VERSION ""

NS_ :

BS_:

BU_: WCM VPM VLM VKM UVM TIM TEST_TOOL_2 TEST_TOOL_1 TCP TCM TCCM3 TCCM STC SRR_SRR SRR_SLR SRR_RR SRR_RF SRR_LR_CR SRR_LF SIB SDM SCL SBZA_R SBZA_L SBM SADS RadioLow RSC RDCM PTM PDR PA NVM MTCM_R MTCM_L MSM_RR MSM_P MSM_LR MSM_D MSB2 MSB1 MRCM_R MRCM_L MFC LRR_HC LRR LIB1 IPC ICS_Info ICCM HVAC_FP_R HVAC_FP_F HUD_CAN HDLM FCM_LC FCM EPS EOCM_HCP2 EOCM_HCP1 EOCM ELM ECP_X1 ECP_MC ECP_E ECM EBCM DMS DEFC DCM CSM CMMb CMMa CGM BSM_MH BSM BCM ARS ARB APA AOS AMP ALC AHS AHL_AFL AGC

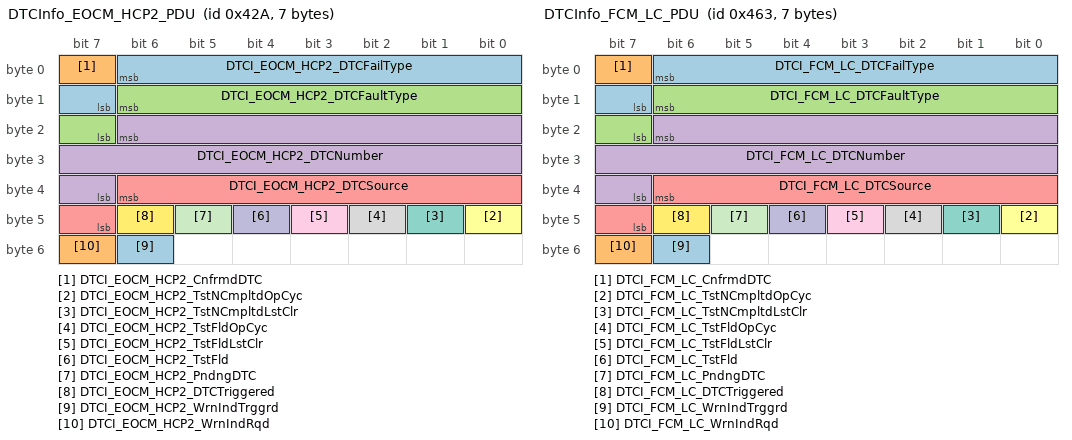
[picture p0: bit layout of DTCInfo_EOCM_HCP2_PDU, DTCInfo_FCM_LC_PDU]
BO_ 1066 DTCInfo_EOCM_HCP2_PDU: 7 EOCM_HCP2
 SG_ DTCI_EOCM_HCP2_DTCFailType : 6|8@0+ (1,0) [0|255] "" CGM
 SG_ DTCI_EOCM_HCP2_CnfrmdDTC : 7|1@0+ (1,0) [0|1] "" CGM
 SG_ DTCI_EOCM_HCP2_DTCFaultType : 14|8@0+ (1,0) [0|3] "" CGM
 SG_ DTCI_EOCM_HCP2_DTCNumber : 22|16@0+ (1,0) [0|65535] "" CGM
 SG_ DTCI_EOCM_HCP2_DTCSource : 38|8@0+ (1,0) [0|255] "" CGM
 SG_ DTCI_EOCM_HCP2_TstNCmpltdOpCyc : 40|1@0+ (1,0) [0|1] "" CGM
 SG_ DTCI_EOCM_HCP2_TstNCmpltdLstClr : 41|1@0+ (1,0) [0|1] "" CGM
 SG_ DTCI_EOCM_HCP2_TstFldOpCyc : 42|1@0+ (1,0) [0|1] "" CGM
 SG_ DTCI_EOCM_HCP2_TstFldLstClr : 43|1@0+ (1,0) [0|1] "" CGM
 SG_ DTCI_EOCM_HCP2_TstFld : 44|1@0+ (1,0) [0|1] "" CGM
 SG_ DTCI_EOCM_HCP2_PndngDTC : 45|1@0+ (1,0) [0|1] "" CGM
 SG_ DTCI_EOCM_HCP2_DTCTriggered : 46|1@0+ (1,0) [0|1] "" CGM
 SG_ DTCI_EOCM_HCP2_WrnIndTrggrd : 54|1@0+ (1,0) [0|1] "" CGM
 SG_ DTCI_EOCM_HCP2_WrnIndRqd : 55|1@0+ (1,0) [0|1] "" CGM

BO_ 1123 DTCInfo_FCM_LC_PDU: 7 FCM_LC
 SG_ DTCI_FCM_LC_DTCFailType : 6|8@0+ (1,0) [0|255] "" CGM
 SG_ DTCI_FCM_LC_CnfrmdDTC : 7|1@0+ (1,0) [0|1] "" CGM
 SG_ DTCI_FCM_LC_DTCFaultType : 14|8@0+ (1,0) [0|3] "" CGM
 SG_ DTCI_FCM_LC_DTCNumber : 22|16@0+ (1,0) [0|65535] "" CGM
 SG_ DTCI_FCM_LC_DTCSource : 38|8@0+ (1,0) [0|255] "" CGM
 SG_ DTCI_FCM_LC_TstNCmpltdOpCyc : 40|1@0+ (1,0) [0|1] "" CGM
 SG_ DTCI_FCM_LC_TstNCmpltdLstClr : 41|1@0+ (1,0) [0|1] "" CGM
 SG_ DTCI_FCM_LC_TstFldOpCyc : 42|1@0+ (1,0) [0|1] "" CGM
 SG_ DTCI_FCM_LC_TstFldLstClr : 43|1@0+ (1,0) [0|1] "" CGM
 SG_ DTCI_FCM_LC_TstFld : 44|1@0+ (1,0) [0|1] "" CGM
 SG_ DTCI_FCM_LC_PndngDTC : 45|1@0+ (1,0) [0|1] "" CGM
 SG_ DTCI_FCM_LC_DTCTriggered : 46|1@0+ (1,0) [0|1] "" CGM
 SG_ DTCI_FCM_LC_WrnIndTrggrd : 54|1@0+ (1,0) [0|1] "" CGM
 SG_ DTCI_FCM_LC_WrnIndRqd : 55|1@0+ (1,0) [0|1] "" CGM

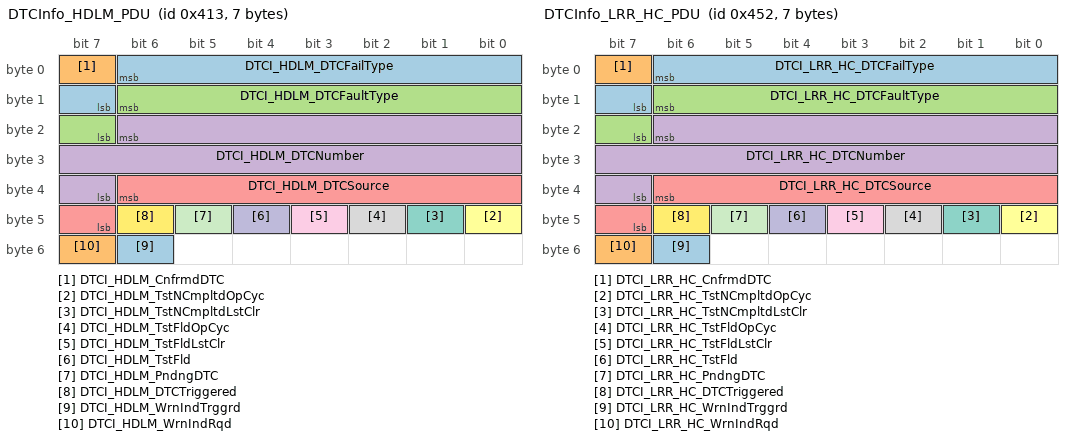
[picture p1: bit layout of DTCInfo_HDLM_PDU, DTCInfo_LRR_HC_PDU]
BO_ 1043 DTCInfo_HDLM_PDU: 7 HDLM
 SG_ DTCI_HDLM_DTCFailType : 6|8@0+ (1,0) [0|255] "" CGM
 SG_ DTCI_HDLM_CnfrmdDTC : 7|1@0+ (1,0) [0|1] "" CGM
 SG_ DTCI_HDLM_DTCFaultType : 14|8@0+ (1,0) [0|3] "" CGM
 SG_ DTCI_HDLM_DTCNumber : 22|16@0+ (1,0) [0|65535] "" CGM
 SG_ DTCI_HDLM_DTCSource : 38|8@0+ (1,0) [0|255] "" CGM
 SG_ DTCI_HDLM_TstNCmpltdOpCyc : 40|1@0+ (1,0) [0|1] "" CGM
 SG_ DTCI_HDLM_TstNCmpltdLstClr : 41|1@0+ (1,0) [0|1] "" CGM
 SG_ DTCI_HDLM_TstFldOpCyc : 42|1@0+ (1,0) [0|1] "" CGM
 SG_ DTCI_HDLM_TstFldLstClr : 43|1@0+ (1,0) [0|1] "" CGM
 SG_ DTCI_HDLM_TstFld : 44|1@0+ (1,0) [0|1] "" CGM
 SG_ DTCI_HDLM_PndngDTC : 45|1@0+ (1,0) [0|1] "" CGM
 SG_ DTCI_HDLM_DTCTriggered : 46|1@0+ (1,0) [0|1] "" CGM
 SG_ DTCI_HDLM_WrnIndTrggrd : 54|1@0+ (1,0) [0|1] "" CGM
 SG_ DTCI_HDLM_WrnIndRqd : 55|1@0+ (1,0) [0|1] "" CGM

BO_ 1106 DTCInfo_LRR_HC_PDU: 7 LRR_HC
 SG_ DTCI_LRR_HC_DTCFailType : 6|8@0+ (1,0) [0|255] "" CGM
 SG_ DTCI_LRR_HC_CnfrmdDTC : 7|1@0+ (1,0) [0|1] "" CGM
 SG_ DTCI_LRR_HC_DTCFaultType : 14|8@0+ (1,0) [0|3] "" CGM
 SG_ DTCI_LRR_HC_DTCNumber : 22|16@0+ (1,0) [0|65535] "" CGM
 SG_ DTCI_LRR_HC_DTCSource : 38|8@0+ (1,0) [0|255] "" CGM
 SG_ DTCI_LRR_HC_TstNCmpltdOpCyc : 40|1@0+ (1,0) [0|1] "" CGM
 SG_ DTCI_LRR_HC_TstNCmpltdLstClr : 41|1@0+ (1,0) [0|1] "" CGM
 SG_ DTCI_LRR_HC_TstFldOpCyc : 42|1@0+ (1,0) [0|1] "" CGM
 SG_ DTCI_LRR_HC_TstFldLstClr : 43|1@0+ (1,0) [0|1] "" CGM
 SG_ DTCI_LRR_HC_TstFld : 44|1@0+ (1,0) [0|1] "" CGM
 SG_ DTCI_LRR_HC_PndngDTC : 45|1@0+ (1,0) [0|1] "" CGM
 SG_ DTCI_LRR_HC_DTCTriggered : 46|1@0+ (1,0) [0|1] "" CGM
 SG_ DTCI_LRR_HC_WrnIndTrggrd : 54|1@0+ (1,0) [0|1] "" CGM
 SG_ DTCI_LRR_HC_WrnIndRqd : 55|1@0+ (1,0) [0|1] "" CGM

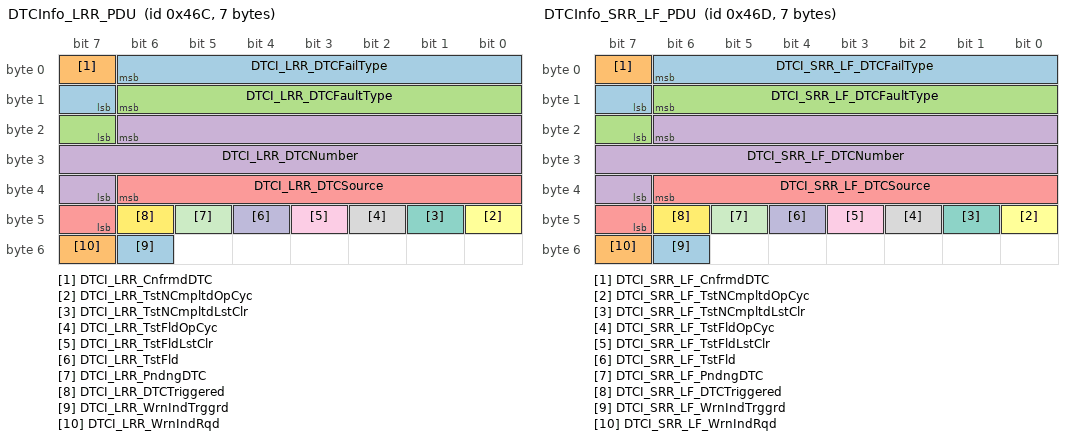
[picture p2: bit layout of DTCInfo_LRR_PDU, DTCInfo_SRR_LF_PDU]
BO_ 1132 DTCInfo_LRR_PDU: 7 LRR
 SG_ DTCI_LRR_DTCFailType : 6|8@0+ (1,0) [0|255] "" CGM
 SG_ DTCI_LRR_CnfrmdDTC : 7|1@0+ (1,0) [0|1] "" CGM
 SG_ DTCI_LRR_DTCFaultType : 14|8@0+ (1,0) [0|3] "" CGM
 SG_ DTCI_LRR_DTCNumber : 22|16@0+ (1,0) [0|65535] "" CGM
 SG_ DTCI_LRR_DTCSource : 38|8@0+ (1,0) [0|255] "" CGM
 SG_ DTCI_LRR_TstNCmpltdOpCyc : 40|1@0+ (1,0) [0|1] "" CGM
 SG_ DTCI_LRR_TstNCmpltdLstClr : 41|1@0+ (1,0) [0|1] "" CGM
 SG_ DTCI_LRR_TstFldOpCyc : 42|1@0+ (1,0) [0|1] "" CGM
 SG_ DTCI_LRR_TstFldLstClr : 43|1@0+ (1,0) [0|1] "" CGM
 SG_ DTCI_LRR_TstFld : 44|1@0+ (1,0) [0|1] "" CGM
 SG_ DTCI_LRR_PndngDTC : 45|1@0+ (1,0) [0|1] "" CGM
 SG_ DTCI_LRR_DTCTriggered : 46|1@0+ (1,0) [0|1] "" CGM
 SG_ DTCI_LRR_WrnIndTrggrd : 54|1@0+ (1,0) [0|1] "" CGM
 SG_ DTCI_LRR_WrnIndRqd : 55|1@0+ (1,0) [0|1] "" CGM

BO_ 1133 DTCInfo_SRR_LF_PDU: 7 SRR_LF
 SG_ DTCI_SRR_LF_DTCFailType : 6|8@0+ (1,0) [0|255] "" CGM
 SG_ DTCI_SRR_LF_CnfrmdDTC : 7|1@0+ (1,0) [0|1] "" CGM
 SG_ DTCI_SRR_LF_DTCFaultType : 14|8@0+ (1,0) [0|3] "" CGM
 SG_ DTCI_SRR_LF_DTCNumber : 22|16@0+ (1,0) [0|65535] "" CGM
 SG_ DTCI_SRR_LF_DTCSource : 38|8@0+ (1,0) [0|255] "" CGM
 SG_ DTCI_SRR_LF_TstNCmpltdOpCyc : 40|1@0+ (1,0) [0|1] "" CGM
 SG_ DTCI_SRR_LF_TstNCmpltdLstClr : 41|1@0+ (1,0) [0|1] "" CGM
 SG_ DTCI_SRR_LF_TstFldOpCyc : 42|1@0+ (1,0) [0|1] "" CGM
 SG_ DTCI_SRR_LF_TstFldLstClr : 43|1@0+ (1,0) [0|1] "" CGM
 SG_ DTCI_SRR_LF_TstFld : 44|1@0+ (1,0) [0|1] "" CGM
 SG_ DTCI_SRR_LF_PndngDTC : 45|1@0+ (1,0) [0|1] "" CGM
 SG_ DTCI_SRR_LF_DTCTriggered : 46|1@0+ (1,0) [0|1] "" CGM
 SG_ DTCI_SRR_LF_WrnIndTrggrd : 54|1@0+ (1,0) [0|1] "" CGM
 SG_ DTCI_SRR_LF_WrnIndRqd : 55|1@0+ (1,0) [0|1] "" CGM

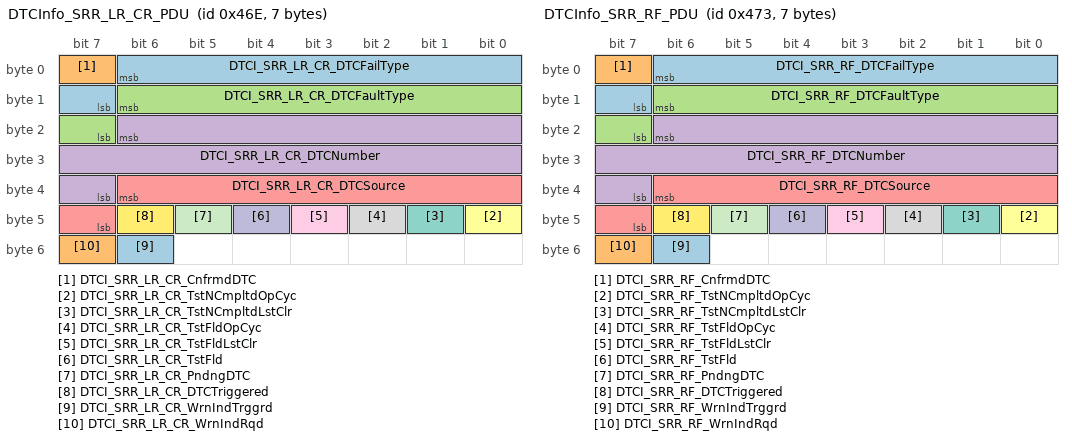
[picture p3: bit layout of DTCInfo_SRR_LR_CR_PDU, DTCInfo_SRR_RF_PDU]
BO_ 1134 DTCInfo_SRR_LR_CR_PDU: 7 SRR_LR_CR
 SG_ DTCI_SRR_LR_CR_DTCFailType : 6|8@0+ (1,0) [0|255] "" CGM
 SG_ DTCI_SRR_LR_CR_CnfrmdDTC : 7|1@0+ (1,0) [0|1] "" CGM
 SG_ DTCI_SRR_LR_CR_DTCFaultType : 14|8@0+ (1,0) [0|3] "" CGM
 SG_ DTCI_SRR_LR_CR_DTCNumber : 22|16@0+ (1,0) [0|65535] "" CGM
 SG_ DTCI_SRR_LR_CR_DTCSource : 38|8@0+ (1,0) [0|255] "" CGM
 SG_ DTCI_SRR_LR_CR_TstNCmpltdOpCyc : 40|1@0+ (1,0) [0|1] "" CGM
 SG_ DTCI_SRR_LR_CR_TstNCmpltdLstClr : 41|1@0+ (1,0) [0|1] "" CGM
 SG_ DTCI_SRR_LR_CR_TstFldOpCyc : 42|1@0+ (1,0) [0|1] "" CGM
 SG_ DTCI_SRR_LR_CR_TstFldLstClr : 43|1@0+ (1,0) [0|1] "" CGM
 SG_ DTCI_SRR_LR_CR_TstFld : 44|1@0+ (1,0) [0|1] "" CGM
 SG_ DTCI_SRR_LR_CR_PndngDTC : 45|1@0+ (1,0) [0|1] "" CGM
 SG_ DTCI_SRR_LR_CR_DTCTriggered : 46|1@0+ (1,0) [0|1] "" CGM
 SG_ DTCI_SRR_LR_CR_WrnIndTrggrd : 54|1@0+ (1,0) [0|1] "" CGM
 SG_ DTCI_SRR_LR_CR_WrnIndRqd : 55|1@0+ (1,0) [0|1] "" CGM

BO_ 1139 DTCInfo_SRR_RF_PDU: 7 SRR_RF
 SG_ DTCI_SRR_RF_DTCFailType : 6|8@0+ (1,0) [0|255] "" CGM
 SG_ DTCI_SRR_RF_CnfrmdDTC : 7|1@0+ (1,0) [0|1] "" CGM
 SG_ DTCI_SRR_RF_DTCFaultType : 14|8@0+ (1,0) [0|3] "" CGM
 SG_ DTCI_SRR_RF_DTCNumber : 22|16@0+ (1,0) [0|65535] "" CGM
 SG_ DTCI_SRR_RF_DTCSource : 38|8@0+ (1,0) [0|255] "" CGM
 SG_ DTCI_SRR_RF_TstNCmpltdOpCyc : 40|1@0+ (1,0) [0|1] "" CGM
 SG_ DTCI_SRR_RF_TstNCmpltdLstClr : 41|1@0+ (1,0) [0|1] "" CGM
 SG_ DTCI_SRR_RF_TstFldOpCyc : 42|1@0+ (1,0) [0|1] "" CGM
 SG_ DTCI_SRR_RF_TstFldLstClr : 43|1@0+ (1,0) [0|1] "" CGM
 SG_ DTCI_SRR_RF_TstFld : 44|1@0+ (1,0) [0|1] "" CGM
 SG_ DTCI_SRR_RF_PndngDTC : 45|1@0+ (1,0) [0|1] "" CGM
 SG_ DTCI_SRR_RF_DTCTriggered : 46|1@0+ (1,0) [0|1] "" CGM
 SG_ DTCI_SRR_RF_WrnIndTrggrd : 54|1@0+ (1,0) [0|1] "" CGM
 SG_ DTCI_SRR_RF_WrnIndRqd : 55|1@0+ (1,0) [0|1] "" CGM

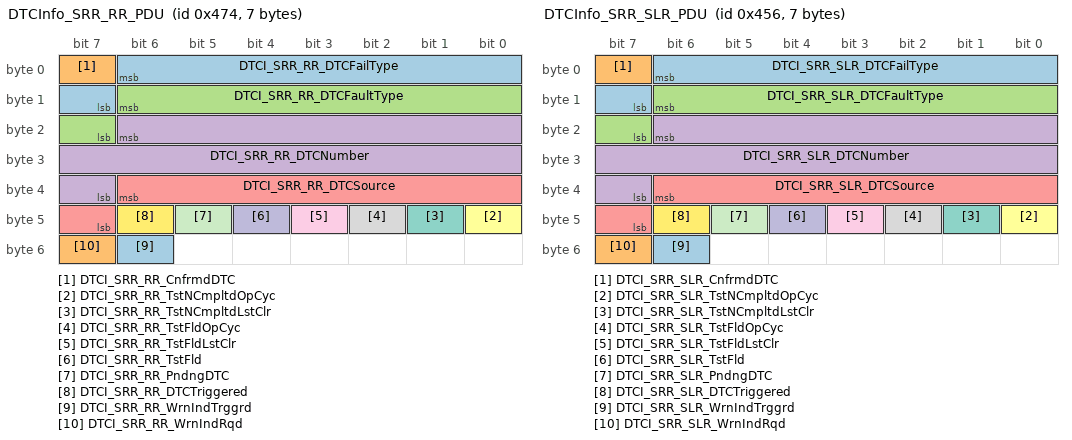
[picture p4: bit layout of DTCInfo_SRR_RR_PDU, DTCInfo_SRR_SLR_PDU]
BO_ 1140 DTCInfo_SRR_RR_PDU: 7 SRR_RR
 SG_ DTCI_SRR_RR_DTCFailType : 6|8@0+ (1,0) [0|255] "" CGM
 SG_ DTCI_SRR_RR_CnfrmdDTC : 7|1@0+ (1,0) [0|1] "" CGM
 SG_ DTCI_SRR_RR_DTCFaultType : 14|8@0+ (1,0) [0|3] "" CGM
 SG_ DTCI_SRR_RR_DTCNumber : 22|16@0+ (1,0) [0|65535] "" CGM
 SG_ DTCI_SRR_RR_DTCSource : 38|8@0+ (1,0) [0|255] "" CGM
 SG_ DTCI_SRR_RR_TstNCmpltdOpCyc : 40|1@0+ (1,0) [0|1] "" CGM
 SG_ DTCI_SRR_RR_TstNCmpltdLstClr : 41|1@0+ (1,0) [0|1] "" CGM
 SG_ DTCI_SRR_RR_TstFldOpCyc : 42|1@0+ (1,0) [0|1] "" CGM
 SG_ DTCI_SRR_RR_TstFldLstClr : 43|1@0+ (1,0) [0|1] "" CGM
 SG_ DTCI_SRR_RR_TstFld : 44|1@0+ (1,0) [0|1] "" CGM
 SG_ DTCI_SRR_RR_PndngDTC : 45|1@0+ (1,0) [0|1] "" CGM
 SG_ DTCI_SRR_RR_DTCTriggered : 46|1@0+ (1,0) [0|1] "" CGM
 SG_ DTCI_SRR_RR_WrnIndTrggrd : 54|1@0+ (1,0) [0|1] "" CGM
 SG_ DTCI_SRR_RR_WrnIndRqd : 55|1@0+ (1,0) [0|1] "" CGM

BO_ 1110 DTCInfo_SRR_SLR_PDU: 7 SRR_SLR
 SG_ DTCI_SRR_SLR_DTCFailType : 6|8@0+ (1,0) [0|255] "" CGM
 SG_ DTCI_SRR_SLR_CnfrmdDTC : 7|1@0+ (1,0) [0|1] "" CGM
 SG_ DTCI_SRR_SLR_DTCFaultType : 14|8@0+ (1,0) [0|3] "" CGM
 SG_ DTCI_SRR_SLR_DTCNumber : 22|16@0+ (1,0) [0|65535] "" CGM
 SG_ DTCI_SRR_SLR_DTCSource : 38|8@0+ (1,0) [0|255] "" CGM
 SG_ DTCI_SRR_SLR_TstNCmpltdOpCyc : 40|1@0+ (1,0) [0|1] "" CGM
 SG_ DTCI_SRR_SLR_TstNCmpltdLstClr : 41|1@0+ (1,0) [0|1] "" CGM
 SG_ DTCI_SRR_SLR_TstFldOpCyc : 42|1@0+ (1,0) [0|1] "" CGM
 SG_ DTCI_SRR_SLR_TstFldLstClr : 43|1@0+ (1,0) [0|1] "" CGM
 SG_ DTCI_SRR_SLR_TstFld : 44|1@0+ (1,0) [0|1] "" CGM
 SG_ DTCI_SRR_SLR_PndngDTC : 45|1@0+ (1,0) [0|1] "" CGM
 SG_ DTCI_SRR_SLR_DTCTriggered : 46|1@0+ (1,0) [0|1] "" CGM
 SG_ DTCI_SRR_SLR_WrnIndTrggrd : 54|1@0+ (1,0) [0|1] "" CGM
 SG_ DTCI_SRR_SLR_WrnIndRqd : 55|1@0+ (1,0) [0|1] "" CGM

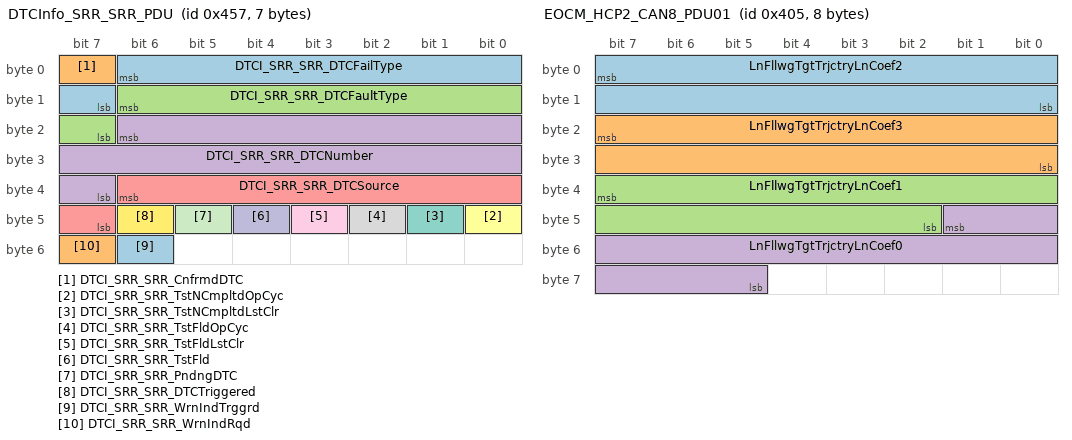
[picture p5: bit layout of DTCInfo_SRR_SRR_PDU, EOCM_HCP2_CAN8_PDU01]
BO_ 1111 DTCInfo_SRR_SRR_PDU: 7 SRR_SRR
 SG_ DTCI_SRR_SRR_DTCFailType : 6|8@0+ (1,0) [0|255] "" CGM
 SG_ DTCI_SRR_SRR_CnfrmdDTC : 7|1@0+ (1,0) [0|1] "" CGM
 SG_ DTCI_SRR_SRR_DTCFaultType : 14|8@0+ (1,0) [0|3] "" CGM
 SG_ DTCI_SRR_SRR_DTCNumber : 22|16@0+ (1,0) [0|65535] "" CGM
 SG_ DTCI_SRR_SRR_DTCSource : 38|8@0+ (1,0) [0|255] "" CGM
 SG_ DTCI_SRR_SRR_TstNCmpltdOpCyc : 40|1@0+ (1,0) [0|1] "" CGM
 SG_ DTCI_SRR_SRR_TstNCmpltdLstClr : 41|1@0+ (1,0) [0|1] "" CGM
 SG_ DTCI_SRR_SRR_TstFldOpCyc : 42|1@0+ (1,0) [0|1] "" CGM
 SG_ DTCI_SRR_SRR_TstFldLstClr : 43|1@0+ (1,0) [0|1] "" CGM
 SG_ DTCI_SRR_SRR_TstFld : 44|1@0+ (1,0) [0|1] "" CGM
 SG_ DTCI_SRR_SRR_PndngDTC : 45|1@0+ (1,0) [0|1] "" CGM
 SG_ DTCI_SRR_SRR_DTCTriggered : 46|1@0+ (1,0) [0|1] "" CGM
 SG_ DTCI_SRR_SRR_WrnIndTrggrd : 54|1@0+ (1,0) [0|1] "" CGM
 SG_ DTCI_SRR_SRR_WrnIndRqd : 55|1@0+ (1,0) [0|1] "" CGM

BO_ 1122 EOCM_CAN8_PDU01: 6 EOCM
 SG_ ASDREvntTrgrPrty : 5|4@0+ (1,0) [0|15] "" FCM_LC
 SG_ ACCAutoStSpStat : 7|2@0+ (1,0) [0|3] "" CGM,FCM_LC

BO_ 178 EOCM_CAN8_PDU02: 6 EOCM
 SG_ ACCBRP_ACCActvAuth : 7|1@0+ (1,0) [0|1] "" FCM_LC

BO_ 1108 EOCM_CAN8_PDU03: 6 EOCM
 SG_ LnDprtrWrnCtlSdThrtRtMirIndReq : 5|2@0+ (1,0) [0|3] "" SRR_SRR
 SG_ LnDprtrWrnCtlSdThrtLtMirIndReq : 7|2@0+ (1,0) [0|3] "" SRR_SLR

BO_ 1029 EOCM_HCP2_CAN8_PDU01: 8 EOCM_HCP2
 SG_ LnFllwgTgtTrjctryLnCoef2 : 7|16@0- (9.77e-07,0) [-0.0320143|0.0320134] "1/m" CGM
 SG_ LnFllwgTgtTrjctryLnCoef3 : 23|16@0- (3.73e-09,0) [-0.000122225|0.000122221] "1/m^2" CGM
 SG_ LnFllwgTgtTrjctryLnCoef1 : 39|14@0- (0.00125,0) [-10.24|10.2388] "m/m" CGM
 SG_ LnFllwgTgtTrjctryLnCoef0 : 41|13@0- (0.00309,0) [-12.6566|12.6535] "m" CGM

BO_ 1045 ElecPrkBrkSts_Prtctd_PDU: 6 CGM
 SG_ EPBSP_ElecPrkBrkApplStsAuth : 35|3@0+ (1,0) [0|4] "" SRR_SLR,SRR_SRR

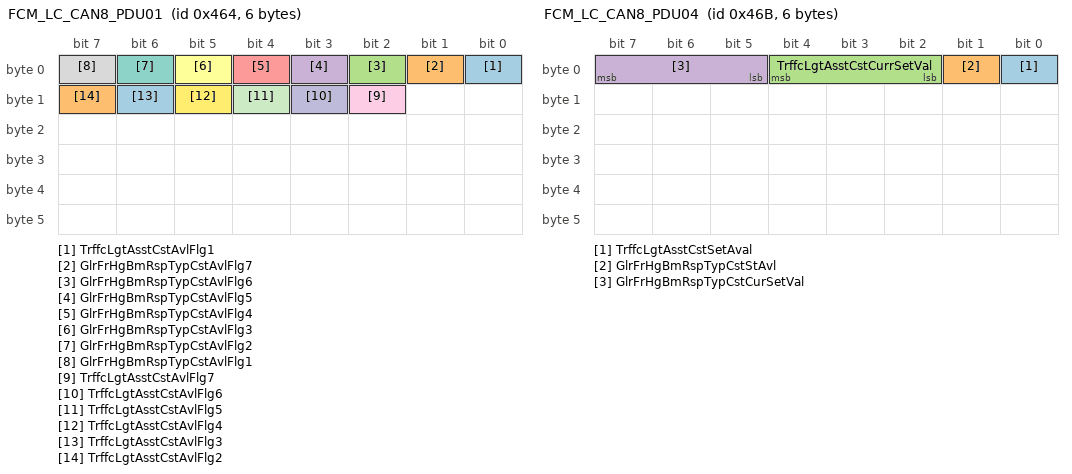
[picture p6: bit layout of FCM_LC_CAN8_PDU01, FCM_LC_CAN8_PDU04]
BO_ 1124 FCM_LC_CAN8_PDU01: 6 FCM_LC
 SG_ TrffcLgtAsstCstAvlFlg1 : 0|1@0+ (1,0) [0|1] "" CGM
 SG_ GlrFrHgBmRspTypCstAvlFlg7 : 1|1@0+ (1,0) [0|1] "" CGM
 SG_ GlrFrHgBmRspTypCstAvlFlg6 : 2|1@0+ (1,0) [0|1] "" CGM
 SG_ GlrFrHgBmRspTypCstAvlFlg5 : 3|1@0+ (1,0) [0|1] "" CGM
 SG_ GlrFrHgBmRspTypCstAvlFlg4 : 4|1@0+ (1,0) [0|1] "" CGM
 SG_ GlrFrHgBmRspTypCstAvlFlg3 : 5|1@0+ (1,0) [0|1] "" CGM
 SG_ GlrFrHgBmRspTypCstAvlFlg2 : 6|1@0+ (1,0) [0|1] "" CGM
 SG_ GlrFrHgBmRspTypCstAvlFlg1 : 7|1@0+ (1,0) [0|1] "" CGM
 SG_ TrffcLgtAsstCstAvlFlg7 : 10|1@0+ (1,0) [0|1] "" CGM
 SG_ TrffcLgtAsstCstAvlFlg6 : 11|1@0+ (1,0) [0|1] "" CGM
 SG_ TrffcLgtAsstCstAvlFlg5 : 12|1@0+ (1,0) [0|1] "" CGM
 SG_ TrffcLgtAsstCstAvlFlg4 : 13|1@0+ (1,0) [0|1] "" CGM
 SG_ TrffcLgtAsstCstAvlFlg3 : 14|1@0+ (1,0) [0|1] "" CGM
 SG_ TrffcLgtAsstCstAvlFlg2 : 15|1@0+ (1,0) [0|1] "" CGM

BO_ 1126 FCM_LC_CAN8_PDU02: 6 FCM_LC
 SG_ TrffcLgtAsstWrnChmEvntStat : 10|2@0+ (1,0) [0|3] "" CGM

BO_ 1129 FCM_LC_CAN8_PDU03: 6 FCM_LC
 SG_ AutoHgBmCtrlIO : 7|1@0+ (1,0) [0|1] "" CGM

BO_ 1131 FCM_LC_CAN8_PDU04: 6 FCM_LC
 SG_ TrffcLgtAsstCstSetAval : 0|1@0+ (1,0) [0|1] "" CGM
 SG_ GlrFrHgBmRspTypCstStAvl : 1|1@0+ (1,0) [0|1] "" CGM
 SG_ TrffcLgtAsstCstCurrSetVal : 4|3@0+ (1,0) [0|7] "" CGM
 SG_ GlrFrHgBmRspTypCstCurSetVal : 7|3@0+ (1,0) [0|7] "" CGM

BO_ 1070 FCODP_Brst1_PCSM_PDU: 8 FCM_LC
 SG_ FCODP_Brst1_PCSM : 0|64@1+ (1,0) [0|1.84467e+019] "" EOCM,EOCM_HCP1,EOCM_HCP2,HDLM

BO_ 17 FsdLoclzdRdTyp_CAN8_PDU01: 6 EOCM
 SG_ FsdLoclzdRdTyp : 1|2@0+ (1,0) [0|2] "" CGM

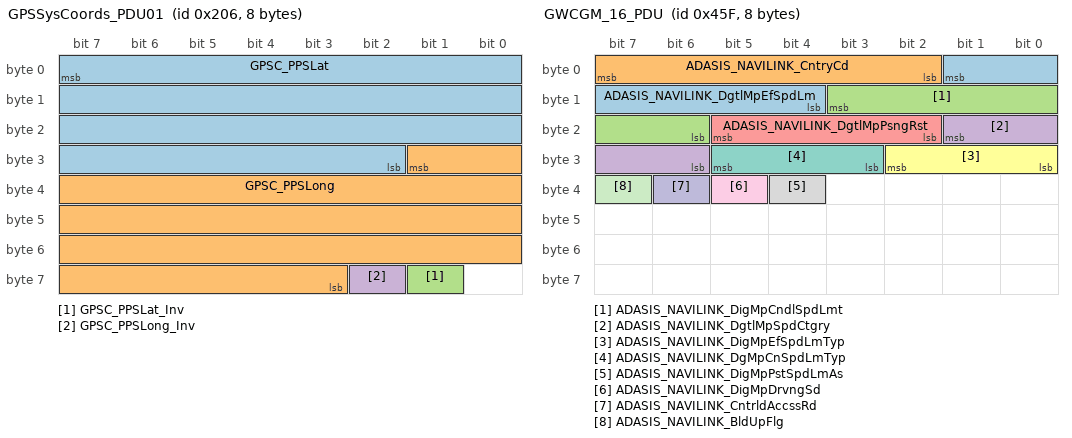
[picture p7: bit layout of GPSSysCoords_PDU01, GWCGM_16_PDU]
BO_ 518 GPSSysCoords_PDU01: 8 CGM
 SG_ GPSC_PPSLat : 7|30@0- (1,0) [-5.36871e+008|5.36871e+008] "ms arc" FCM_LC
 SG_ GPSC_PPSLong : 25|31@0- (1,0) [-1.07374e+009|1.07374e+009] "ms arc" FCM_LC
 SG_ GPSC_PPSLat_Inv : 57|1@0+ (1,0) [0|1] "" FCM_LC
 SG_ GPSC_PPSLong_Inv : 58|1@0+ (1,0) [0|1] "" FCM_LC

BO_ 1128 GWCGM_12_PDU: 8 FCM_LC
 SG_ TSMCurrSpdLim : 7|8@0+ (1,0) [0|255] "" Vector__XXX
 SG_ TSMEurDispSgn2Mn : 9|6@0+ (1,0) [0|54] "" Vector__XXX
 SG_ TSMEurDispSgn1Mn : 15|6@0+ (1,0) [0|54] "" Vector__XXX
 SG_ TSMUSAndCADispSgn1Mn : 19|6@0+ (1,0) [0|45] "" Vector__XXX
 SG_ TSMUSAndCADispSgn2Mn : 29|6@0+ (1,0) [0|45] "" Vector__XXX
 SG_ TSMEurDispSgn2AddOn : 35|4@0+ (1,0) [0|15] "" Vector__XXX
 SG_ TSMEurDispSgn1AddOn : 39|4@0+ (1,0) [0|15] "" Vector__XXX
 SG_ FrwdVsFlDtcnIndOn : 40|1@0+ (1,0) [0|1] "" Vector__XXX
 SG_ FrwdVsAdvWthrIndOn : 41|1@0+ (1,0) [0|1] "" Vector__XXX
 SG_ TSMUSAndCADispSgn2AddOn : 44|3@0+ (1,0) [0|5] "" Vector__XXX
 SG_ TSMUSAndCADispSgn1AddOn : 47|3@0+ (1,0) [0|5] "" Vector__XXX
 SG_ TrffcLgtAsstHUDWrnIndOn : 48|1@0+ (1,0) [0|1] "" Vector__XXX
 SG_ TrffcLgtAsstClstrWrnIndOn : 49|1@0+ (1,0) [0|1] "" Vector__XXX
 SG_ TSMSgnNtfnIndOn : 50|1@0+ (1,0) [0|1] "" Vector__XXX
 SG_ TSMPDAMnSgnFlshgReq : 51|1@0+ (1,0) [0|1] "" Vector__XXX
 SG_ TSMNoEntryIndOn : 52|1@0+ (1,0) [0|1] "" Vector__XXX
 SG_ TSMIcePsblIndOn : 53|1@0+ (1,0) [0|1] "" Vector__XXX
 SG_ TSMAddTrfSgnAvIndOn : 54|1@0+ (1,0) [0|1] "" Vector__XXX
 SG_ FrwdVsFllBlckIndOn : 55|1@0+ (1,0) [0|1] "" Vector__XXX
 SG_ TrffcLgtAsstRLADWrnIndOn : 63|1@0+ (1,0) [0|1] "" Vector__XXX

BO_ 1119 GWCGM_16_PDU: 8 CGM
 SG_ ADASIS_NAVILINK_DgtlMpEfSpdLm : 1|6@0+ (1,0) [0|31] "" FCM_LC
 SG_ ADASIS_NAVILINK_CntryCd : 7|6@0+ (1,0) [0|46] "" FCM_LC
 SG_ ADASIS_NAVILINK_DigMpCndlSpdLmt : 11|6@0+ (1,0) [0|31] "" FCM_LC
 SG_ ADASIS_NAVILINK_DgtlMpSpdCtgry : 17|4@0+ (1,0) [0|8] "" FCM_LC
 SG_ ADASIS_NAVILINK_DgtlMpPsngRst : 21|4@0+ (1,0) [0|7] "" FCM_LC
 SG_ ADASIS_NAVILINK_DigMpEfSpdLmTyp : 26|3@0+ (1,0) [0|7] "" FCM_LC
 SG_ ADASIS_NAVILINK_DgMpCnSpdLmTyp : 29|3@0+ (1,0) [0|7] "" FCM_LC
 SG_ ADASIS_NAVILINK_DigMpPstSpdLmAs : 36|1@0+ (1,0) [0|1] "" FCM_LC
 SG_ ADASIS_NAVILINK_DigMpDrvngSd : 37|1@0+ (1,0) [0|1] "" FCM_LC
 SG_ ADASIS_NAVILINK_CntrldAccssRd : 38|1@0+ (1,0) [0|1] "" FCM_LC
 SG_ ADASIS_NAVILINK_BldUpFlg : 39|1@0+ (1,0) [0|1] "" FCM_LC

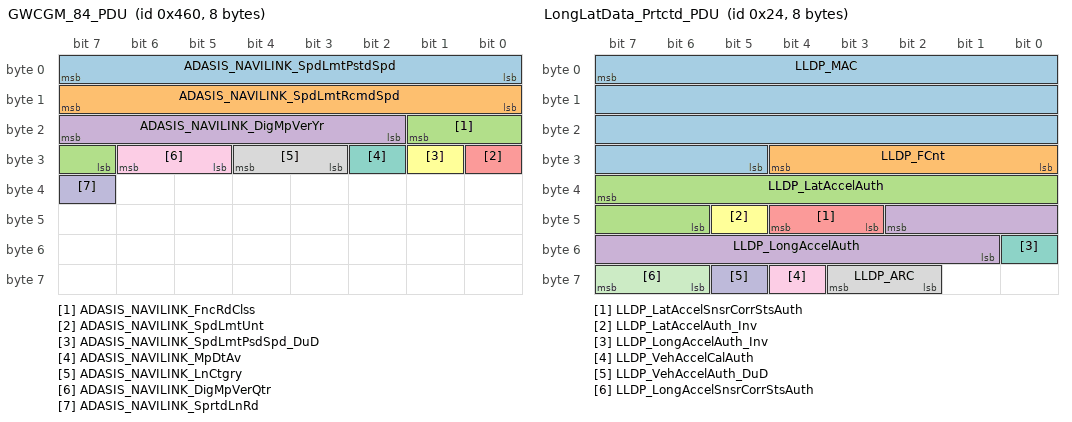
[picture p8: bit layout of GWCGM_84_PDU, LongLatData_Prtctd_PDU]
BO_ 1120 GWCGM_84_PDU: 8 CGM
 SG_ ADASIS_NAVILINK_SpdLmtPstdSpd : 7|8@0+ (1,0) [0|255] "" FCM_LC,HDLM
 SG_ ADASIS_NAVILINK_SpdLmtRcmdSpd : 15|8@0+ (1,0) [0|255] "" FCM_LC
 SG_ ADASIS_NAVILINK_FncRdClss : 17|3@0+ (1,0) [0|7] "" EOCM,EOCM_HCP2,FCM_LC,HDLM
 SG_ ADASIS_NAVILINK_DigMpVerYr : 23|6@0+ (1,0) [0|63] "" FCM_LC
 SG_ ADASIS_NAVILINK_SpdLmtUnt : 24|1@0+ (1,0) [0|1] "" FCM_LC
 SG_ ADASIS_NAVILINK_SpdLmtPsdSpd_DuD : 25|1@0+ (1,0) [0|1] "" FCM_LC
 SG_ ADASIS_NAVILINK_MpDtAv : 26|1@0+ (1,0) [0|1] "" EOCM,EOCM_HCP2,FCM_LC
 SG_ ADASIS_NAVILINK_LnCtgry : 28|2@0+ (1,0) [0|3] "" FCM_LC
 SG_ ADASIS_NAVILINK_DigMpVerQtr : 30|2@0+ (1,0) [0|3] "" FCM_LC
 SG_ ADASIS_NAVILINK_SprtdLnRd : 39|1@0+ (1,0) [0|1] "" FCM_LC

BO_ 1060 GWCGM_85_PDU: 6 CGM
 SG_ VehIdNmDig1 : 7|8@0+ (1,0) [0|255] "" HDLM

BO_ 514 GWCGM_92_PDU: 6 CGM
 SG_ EASSI_StrtStpSt : 5|2@0+ (1,0) [0|3] "" HDLM

BO_ 577 HstVehPathParms_PCSM_PDU: 8 EOCM
 SG_ HstVehPathParms_PCSM : 0|64@1+ (1,0) [0|1.84467e+019] "" FCM_LC,LRR,SRR_LF,SRR_LR_CR,SRR_RF,SRR_RR,SRR_SLR,SRR_SRR

BO_ 32 HstVehPathParms_Prtctd_PDU: 32 EOCM
 SG_ HVPPP_MAC : 7|32@0+ (1,0) [0|4.29497e+009] "" FCM_LC,LRR,SRR_LF,SRR_LR_CR,SRR_RF,SRR_RR,SRR_SLR,SRR_SRR
 SG_ HVPPP_FCnt : 39|5@0+ (1,0) [0|31] "" FCM_LC,LRR,SRR_LF,SRR_LR_CR,SRR_RF,SRR_RR,SRR_SLR,SRR_SRR
 SG_ HVPPP_HstVehTrnCntrLatOfstAuth : 42|14@0+ (1,-8192) [-8192|8191] "m" FCM_LC,LRR,SRR_LF,SRR_LR_CR,SRR_RF,SRR_RR,SRR_SLR,SRR_SRR
 SG_ HVPPP_ShrtRngRadarModeCmdAuth : 44|2@0+ (1,0) [0|2] "" FCM_LC,LRR,SRR_LF,SRR_LR_CR,SRR_RF,SRR_RR,SRR_SLR,SRR_SRR
 SG_ HVPPP_LngRngRadarModeCmdAuth : 46|2@0+ (1,0) [0|2] "" FCM_LC,LRR,SRR_LF,SRR_LR_CR,SRR_RF,SRR_RR,SRR_SLR,SRR_SRR
 SG_ HVPPP_HstVehLatVelAuth_Inv : 47|1@0+ (1,0) [0|1] "" FCM_LC,LRR,SRR_LF,SRR_LR_CR,SRR_RF,SRR_RR,SRR_SLR,SRR_SRR
 SG_ HVPPP_HstVehYawRateAuth : 60|12@0+ (0.0625,-128) [-128|127.938] "deg/s" FCM_LC,LRR,SRR_LF,SRR_LR_CR,SRR_RF,SRR_RR,SRR_SLR,SRR_SRR
 SG_ HVPPP_ObjSnsrTmSyncMstrClckAuth : 64|32@0+ (1,0) [0|4.29497e+009] "ms" FCM_LC,LRR,SRR_LF,SRR_LR_CR,SRR_RF,SRR_RR,SRR_SLR,SRR_SRR
 SG_ HVPPP_HstVehVelAuth_Inv : 96|1@0+ (1,0) [0|1] "" FCM_LC,LRR,SRR_LF,SRR_LR_CR,SRR_RF,SRR_RR,SRR_SLR,SRR_SRR
 SG_ HVPPP_HstVehPathCrvDrvtAuth : 111|15@0+ (0.001,-16) [-16|16.767] "1/m-s" FCM_LC,LRR,SRR_LF,SRR_LR_CR,SRR_RF,SRR_RR,SRR_SLR,SRR_SRR
 SG_ HVPPP_HstVehLatVelAuth : 112|8@0+ (0.05,-6.4) [-6.4|6.35] "m/s" FCM_LC,LRR,SRR_LF,SRR_LR_CR,SRR_RF,SRR_RR,SRR_SLR,SRR_SRR
 SG_ HVPPP_ObjsRetndRrwdSnsrsAuth : 120|2@0+ (1,0) [0|2] "" FCM_LC,LRR,SRR_LF,SRR_LR_CR,SRR_RF,SRR_RR,SRR_SLR,SRR_SRR
 SG_ HVPPP_HstVehLngVelAuth : 134|12@0+ (0.0625,-128) [-128|127.938] "m/s" FCM_LC,LRR,SRR_LF,SRR_LR_CR,SRR_RF,SRR_RR,SRR_SLR,SRR_SRR
 SG_ HVPPP_HstVehTrnCntrLngOfstAuth : 137|8@0+ (0.1,-12.8) [-12.8|12.7] "m" FCM_LC,LRR,SRR_LF,SRR_LR_CR,SRR_RF,SRR_RR,SRR_SLR,SRR_SRR
 SG_ HVPPP_HstVehLngVelAuth_Inv : 138|1@0+ (1,0) [0|1] "" FCM_LC,LRR,SRR_LF,SRR_LR_CR,SRR_RF,SRR_RR,SRR_SLR,SRR_SRR
 SG_ HVPPP_HstVehPathCrvAuth : 145|16@0- (1e-05,0) [-0.32768|0.32767] "1/m" FCM_LC,LRR,SRR_LF,SRR_LR_CR,SRR_RF,SRR_RR,SRR_SLR,SRR_SRR
 SG_ HVPPP_HstVehVelAuth : 161|12@0+ (0.0625,-128) [-128|127.938] "m/s" FCM_LC,LRR,SRR_LF,SRR_LR_CR,SRR_RF,SRR_RR,SRR_SLR,SRR_SRR
 SG_ HVPPP_HstVehSdslAngAuth : 179|12@0+ (0.0625,-128) [-128|127.938] "deg/s" FCM_LC,LRR,SRR_LF,SRR_LR_CR,SRR_RF,SRR_RR,SRR_SLR,SRR_SRR
 SG_ HVPPP_ObjsRetndFrwdSnsrsAuth : 181|2@0+ (1,0) [0|2] "" FCM_LC,LRR,SRR_LF,SRR_LR_CR,SRR_RF,SRR_RR,SRR_SLR,SRR_SRR
 SG_ HVPPP_ARC : 193|2@0+ (1,0) [0|3] "" FCM_LC,LRR,SRR_LF,SRR_LR_CR,SRR_RF,SRR_RR,SRR_SLR,SRR_SRR
 SG_ HVPPP_HstVehPathModeAuth : 195|2@0+ (1,0) [0|2] "" FCM_LC,LRR,SRR_LF,SRR_LR_CR,SRR_RF,SRR_RR,SRR_SLR,SRR_SRR
 SG_ HVPPP_HstVehYawRateAuth_Inv : 196|1@0+ (1,0) [0|1] "" FCM_LC,LRR,SRR_LF,SRR_LR_CR,SRR_RF,SRR_RR,SRR_SLR,SRR_SRR
 SG_ HVPPP_HstVehTrvlDirAuth : 198|2@0+ (1,0) [0|3] "" FCM_LC,LRR,SRR_LF,SRR_LR_CR,SRR_RF,SRR_RR,SRR_SLR,SRR_SRR
 SG_ HVPPP_FrwdVsnModeCmdAuth : 199|1@0+ (1,0) [0|1] "" FCM_LC,LRR,SRR_LF,SRR_LR_CR,SRR_RF,SRR_RR,SRR_SLR,SRR_SRR

BO_ 1082 LRRODP_Brst1_PCSM_PDU: 8 LRR
 SG_ LRRODP_Brst1_PCSM : 0|64@1+ (1,0) [0|1.84467e+019] "" EOCM,EOCM_HCP1,EOCM_HCP2

BO_ 593 LongLatData_PCSM_PDU: 8 CGM
 SG_ LongLatData_PCSM : 0|64@1+ (1,0) [0|1.84467e+019] "" FCM_LC

BO_ 36 LongLatData_Prtctd_PDU: 8 CGM
 SG_ LLDP_MAC : 7|27@0+ (1,0) [0|1.34218e+008] "" FCM_LC
 SG_ LLDP_FCnt : 28|5@0+ (1,0) [0|31] "" FCM_LC
 SG_ LLDP_LatAccelAuth : 39|10@0- (0.0625,0) [-32|31.9375] "m/s^2" FCM_LC
 SG_ LLDP_LongAccelAuth : 42|10@0- (0.0625,0) [-32|31.9375] "m/s^2" FCM_LC
 SG_ LLDP_LatAccelSnsrCorrStsAuth : 44|2@0+ (1,0) [0|3] "" FCM_LC
 SG_ LLDP_LatAccelAuth_Inv : 45|1@0+ (1,0) [0|1] "" FCM_LC
 SG_ LLDP_LongAccelAuth_Inv : 48|1@0+ (1,0) [0|1] "" FCM_LC
 SG_ LLDP_ARC : 59|2@0+ (1,0) [0|3] "" FCM_LC
 SG_ LLDP_VehAccelCalAuth : 60|1@0+ (1,0) [0|1] "" FCM_LC
 SG_ LLDP_VehAccelAuth_DuD : 61|1@0+ (1,0) [0|1] "" FCM_LC
 SG_ LLDP_LongAccelSnsrCorrStsAuth : 63|2@0+ (1,0) [0|3] "" FCM_LC

BO_ 1377 NodeStatus_CAN8_PDU01: 8 CGM
 SG_ NodeStsAPA_CAN_2_LcFA : 0|1@0+ (1,0) [0|1] "" Vector__XXX
 SG_ NodeStsAPA_CAN_1_LcFA : 1|1@0+ (1,0) [0|1] "" Vector__XXX
 SG_ NodeStsAOS_LcFA : 2|1@0+ (1,0) [0|1] "" Vector__XXX
 SG_ NodeStsAMP_LcFA : 3|1@0+ (1,0) [0|1] "" Vector__XXX
 SG_ NodeStsALC_LcFA : 4|1@0+ (1,0) [0|1] "" Vector__XXX
 SG_ NodeStsAHL_AFL_LcFA : 5|1@0+ (1,0) [0|1] "" Vector__XXX
 SG_ NodeStsAGC_LcFA : 6|1@0+ (1,0) [0|1] "" Vector__XXX
 SG_ NodeStsDMS_LcFA : 8|1@0+ (1,0) [0|1] "" Vector__XXX
 SG_ NodeStsDEFC_LcFA : 9|1@0+ (1,0) [0|1] "" Vector__XXX
 SG_ NodeStsDCM_LcFA : 10|1@0+ (1,0) [0|1] "" Vector__XXX
 SG_ NodeStsCSM_LcFA : 11|1@0+ (1,0) [0|1] "" Vector__XXX
 SG_ NodeStsBSM_CAN_3_LcFA : 12|1@0+ (1,0) [0|1] "" Vector__XXX
 SG_ NodeStsBSM_CAN_2_LcFA : 13|1@0+ (1,0) [0|1] "" Vector__XXX
 SG_ NodeStsBCM_LcFA : 14|1@0+ (1,0) [0|1] "" EOCM_HCP2,FCM_LC,HDLM,LRR,LRR_HC,SRR_LF,SRR_LR_CR,SRR_RF,SRR_RR,SRR_SLR,SRR_SRR
 SG_ NodeStsARB_LcFA : 15|1@0+ (1,0) [0|1] "" Vector__XXX
 SG_ NodeStsELM_LcFA : 16|1@0+ (1,0) [0|1] "" Vector__XXX
 SG_ NodeStsECP_X1_CAN_3_LcFA : 18|1@0+ (1,0) [0|1] "" Vector__XXX
 SG_ NodeStsECP_X1_CAN_2_LcFA : 19|1@0+ (1,0) [0|1] "" Vector__XXX
 SG_ NodeStsECM_CAN_3_LcFA : 20|1@0+ (1,0) [0|1] "" Vector__XXX
 SG_ NodeStsECM_CAN_2_LcFA : 21|1@0+ (1,0) [0|1] "" EOCM_HCP2,FCM_LC,LRR,LRR_HC,SRR_LF,SRR_LR_CR,SRR_RF,SRR_RR,SRR_SLR,SRR_SRR
 SG_ NodeStsEBCM_CAN_2_LcFA : 22|1@0+ (1,0) [0|1] "" Vector__XXX
 SG_ NodeStsEBCM_CAN_1_LcFA : 23|1@0+ (1,0) [0|1] "" FCM_LC
 SG_ NodeStsEPS_LcFA : 24|1@0+ (1,0) [0|1] "" FCM_LC
 SG_ NodeStsEOCM_HCP2_LcFA : 25|1@0+ (1,0) [0|1] "" Vector__XXX
 SG_ NodeStsEOCM_HCP1_CAN_8_LcFA : 26|1@0+ (1,0) [0|1] "" Vector__XXX
 SG_ NodeStsEOCM_HCP1_CAN_2_LcFA : 27|1@0+ (1,0) [0|1] "" Vector__XXX
 SG_ NodeStsEOCM_HCP1_CAN_1_LcFA : 28|1@0+ (1,0) [0|1] "" Vector__XXX
 SG_ NodeStsEOCM_CAN_8_LcFA : 29|1@0+ (1,0) [0|1] "" Vector__XXX
 SG_ NodeStsEOCM_CAN_2_LcFA : 30|1@0+ (1,0) [0|1] "" Vector__XXX
 SG_ NodeStsEOCM_CAN_1_LcFA : 31|1@0+ (1,0) [0|1] "" Vector__XXX
 SG_ NodeStsIPC_LcFA : 32|1@0+ (1,0) [0|1] "" Vector__XXX
 SG_ NodeStsICS_Info_LcFA : 33|1@0+ (1,0) [0|1] "" Vector__XXX
 SG_ NodeStsICCM_LcFA : 34|1@0+ (1,0) [0|1] "" Vector__XXX
 SG_ NodeStsHVAC_FP_R_LcFA : 35|1@0+ (1,0) [0|1] "" Vector__XXX
 SG_ NodeStsHVAC_FP_F_LcFA : 36|1@0+ (1,0) [0|1] "" Vector__XXX
 SG_ NodeStsHUD_CAN_LcFA : 37|1@0+ (1,0) [0|1] "" Vector__XXX
 SG_ NodeStsFCM_LcFA : 38|1@0+ (1,0) [0|1] "" Vector__XXX
 SG_ NodeStsFCM_LC_LcFA : 39|1@0+ (1,0) [0|1] "" Vector__XXX
 SG_ NodeStsMSM_D_LcFA : 40|1@0+ (1,0) [0|1] "" Vector__XXX
 SG_ NodeStsMSB2_LcFA : 41|1@0+ (1,0) [0|1] "" Vector__XXX
 SG_ NodeStsMSB1_LcFA : 42|1@0+ (1,0) [0|1] "" Vector__XXX
 SG_ NodeStsMRCM_R_LcFA : 43|1@0+ (1,0) [0|1] "" Vector__XXX
 SG_ NodeStsMRCM_L_LcFA : 44|1@0+ (1,0) [0|1] "" Vector__XXX
 SG_ NodeStsMFC_LcFA : 45|1@0+ (1,0) [0|1] "" Vector__XXX
 SG_ NodeStsLRR_LcFA : 46|1@0+ (1,0) [0|1] "" Vector__XXX
 SG_ NodeStsLRR_HC_LcFA : 47|1@0+ (1,0) [0|1] "" Vector__XXX
 SG_ NodeStsPDR_LcFA : 48|1@0+ (1,0) [0|1] "" Vector__XXX
 SG_ NodeStsPA_LcFA : 49|1@0+ (1,0) [0|1] "" Vector__XXX
 SG_ NodeStsNVM_LcFA : 50|1@0+ (1,0) [0|1] "" Vector__XXX
 SG_ NodeStsMTCM_R_LcFA : 51|1@0+ (1,0) [0|1] "" Vector__XXX
 SG_ NodeStsMTCM_L_LcFA : 52|1@0+ (1,0) [0|1] "" Vector__XXX
 SG_ NodeStsMSM_RR_LcFA : 53|1@0+ (1,0) [0|1] "" Vector__XXX
 SG_ NodeStsMSM_P_LcFA : 54|1@0+ (1,0) [0|1] "" Vector__XXX
 SG_ NodeStsMSM_LR_LcFA : 55|1@0+ (1,0) [0|1] "" Vector__XXX
 SG_ NodeStsSBZA_R_LcFA : 56|1@0+ (1,0) [0|1] "" Vector__XXX
 SG_ NodeStsSBZA_L_LcFA : 57|1@0+ (1,0) [0|1] "" Vector__XXX
 SG_ NodeStsSADS_LcFA : 58|1@0+ (1,0) [0|1] "" Vector__XXX
 SG_ NodeStsAHS_LcFA : 59|1@0+ (1,0) [0|1] "" Vector__XXX
 SG_ NodeStsRSC_LcFA : 60|1@0+ (1,0) [0|1] "" Vector__XXX
 SG_ NodeStsRDCM_LcFA : 61|1@0+ (1,0) [0|1] "" Vector__XXX
 SG_ NodeStsRadioLow_LcFA : 62|1@0+ (1,0) [0|1] "" Vector__XXX
 SG_ NodeStsPTM_LcFA : 63|1@0+ (1,0) [0|1] "" Vector__XXX

BO_ 1378 NodeStatus_CAN8_PDU02: 6 CGM
 SG_ NodeStsSRR_SLR_LcFA : 0|1@0+ (1,0) [0|1] "" Vector__XXX
 SG_ NodeStsSRR_RR_LcFA : 1|1@0+ (1,0) [0|1] "" Vector__XXX
 SG_ NodeStsSRR_RF_LcFA : 2|1@0+ (1,0) [0|1] "" Vector__XXX
 SG_ NodeStsSRR_LR_CR_LcFA : 3|1@0+ (1,0) [0|1] "" Vector__XXX
 SG_ NodeStsSRR_LF_LcFA : 4|1@0+ (1,0) [0|1] "" Vector__XXX
 SG_ NodeStsSIB_LcFA : 5|1@0+ (1,0) [0|1] "" Vector__XXX
 SG_ NodeStsSDM_LcFA : 6|1@0+ (1,0) [0|1] "" FCM_LC
 SG_ NodeStsSCL_LcFA : 7|1@0+ (1,0) [0|1] "" Vector__XXX
 SG_ NodeStsTIM_LcFA : 8|1@0+ (1,0) [0|1] "" Vector__XXX
 SG_ NodeStsTCP_LcFA : 9|1@0+ (1,0) [0|1] "" Vector__XXX
 SG_ NodeStsTCM_LcFA : 10|1@0+ (1,0) [0|1] "" Vector__XXX
 SG_ NodeStsTCCM3_LcFA : 11|1@0+ (1,0) [0|1] "" Vector__XXX
 SG_ NodeStsTCCM_LcFA : 12|1@0+ (1,0) [0|1] "" Vector__XXX
 SG_ NodeStsSTC_LcFA : 14|1@0+ (1,0) [0|1] "" Vector__XXX
 SG_ NodeStsSRR_SRR_LcFA : 15|1@0+ (1,0) [0|1] "" Vector__XXX
 SG_ NodeStsECP_E_CAN_9_LcFA : 16|1@0+ (1,0) [0|1] "" Vector__XXX
 SG_ NodeStsCMMb_CAN_2_LcFA : 17|1@0+ (1,0) [0|1] "" Vector__XXX
 SG_ NodeStsCMMa_CAN_2_LcFA : 18|1@0+ (1,0) [0|1] "" Vector__XXX
 SG_ NodeStsARS_LcFA : 19|1@0+ (1,0) [0|1] "" Vector__XXX
 SG_ NodeStsVLM_LcFA : 20|1@0+ (1,0) [0|1] "" Vector__XXX
 SG_ NodeStsWCM_LcFA : 21|1@0+ (1,0) [0|1] "" Vector__XXX
 SG_ NodeStsVPM_LcFA : 22|1@0+ (1,0) [0|1] "" Vector__XXX
 SG_ NodeStsVKM_LcFA : 23|1@0+ (1,0) [0|1] "" Vector__XXX
 SG_ NodeStsECP_E_CAN_2_LcFA : 31|1@0+ (1,0) [0|1] "" Vector__XXX

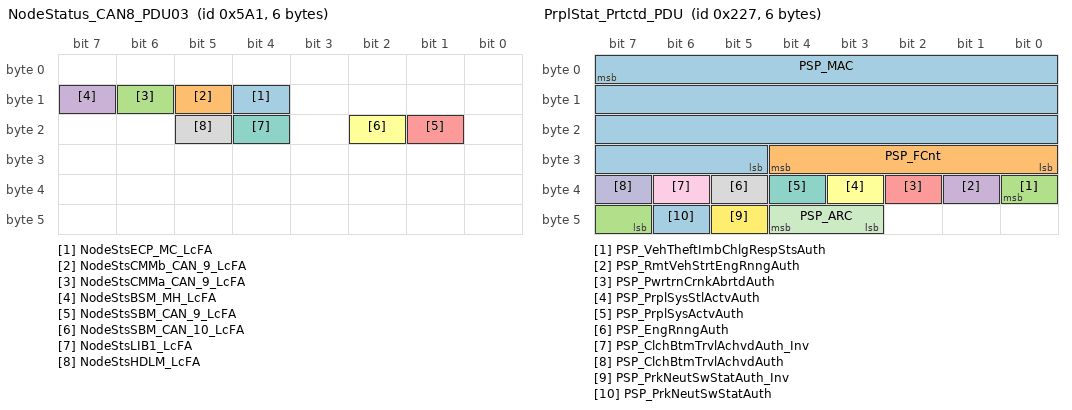
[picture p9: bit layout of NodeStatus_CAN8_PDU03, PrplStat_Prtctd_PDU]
BO_ 1441 NodeStatus_CAN8_PDU03: 6 CGM
 SG_ NodeStsECP_MC_LcFA : 12|1@0+ (1,0) [0|1] "" Vector__XXX
 SG_ NodeStsCMMb_CAN_9_LcFA : 13|1@0+ (1,0) [0|1] "" Vector__XXX
 SG_ NodeStsCMMa_CAN_9_LcFA : 14|1@0+ (1,0) [0|1] "" Vector__XXX
 SG_ NodeStsBSM_MH_LcFA : 15|1@0+ (1,0) [0|1] "" Vector__XXX
 SG_ NodeStsSBM_CAN_9_LcFA : 17|1@0+ (1,0) [0|1] "" Vector__XXX
 SG_ NodeStsSBM_CAN_10_LcFA : 18|1@0+ (1,0) [0|1] "" Vector__XXX
 SG_ NodeStsLIB1_LcFA : 20|1@0+ (1,0) [0|1] "" Vector__XXX
 SG_ NodeStsHDLM_LcFA : 21|1@0+ (1,0) [0|1] "" Vector__XXX

BO_ 566 PrplStat_PCSM_PDU: 8 CGM
 SG_ PrplStat_PCSM : 0|64@1+ (1,0) [0|1.84467e+019] "" HDLM

BO_ 551 PrplStat_Prtctd_PDU: 6 CGM
 SG_ PSP_MAC : 7|27@0+ (1,0) [0|1.34218e+008] "" HDLM
 SG_ PSP_FCnt : 28|5@0+ (1,0) [0|31] "" HDLM
 SG_ PSP_VehTheftImbChlgRespStsAuth : 32|2@0+ (1,0) [0|2] "" HDLM
 SG_ PSP_RmtVehStrtEngRnngAuth : 33|1@0+ (1,0) [0|1] "" HDLM
 SG_ PSP_PwrtrnCrnkAbrtdAuth : 34|1@0+ (1,0) [0|1] "" HDLM
 SG_ PSP_PrplSysStlActvAuth : 35|1@0+ (1,0) [0|1] "" HDLM
 SG_ PSP_PrplSysActvAuth : 36|1@0+ (1,0) [0|1] "" FCM_LC,HDLM,LRR,SRR_LF,SRR_LR_CR,SRR_RF,SRR_RR,SRR_SLR,SRR_SRR
 SG_ PSP_EngRnngAuth : 37|1@0+ (1,0) [0|1] "" EOCM_HCP2,FCM_LC,HDLM,LRR,LRR_HC,SRR_LF,SRR_LR_CR,SRR_RF,SRR_RR,SRR_SLR,SRR_SRR
 SG_ PSP_ClchBtmTrvlAchvdAuth_Inv : 38|1@0+ (1,0) [0|1] "" HDLM
 SG_ PSP_ClchBtmTrvlAchvdAuth : 39|1@0+ (1,0) [0|1] "" HDLM
 SG_ PSP_ARC : 44|2@0+ (1,0) [0|3] "" HDLM
 SG_ PSP_PrkNeutSwStatAuth_Inv : 45|1@0+ (1,0) [0|1] "" HDLM
 SG_ PSP_PrkNeutSwStatAuth : 46|1@0+ (1,0) [0|1] "" HDLM

BO_ 1054 RrCrsTrfcBrkgAutoBrkgRelIndOn_PD: 6 SRR_SLR
 SG_ RrCrsTrfcBrkgAutoBrkgRelIndOn : 7|1@0+ (1,0) [0|1] "" Vector__XXX

BO_ 140 RrCrsTrfcBrkgAutoBrkgReqdRt_PDU0: 6 SRR_SRR
 SG_ RrCrsTrfcBrkgAutoBrkgReqdRt : 7|1@0+ (1,0) [0|1] "" SRR_SLR

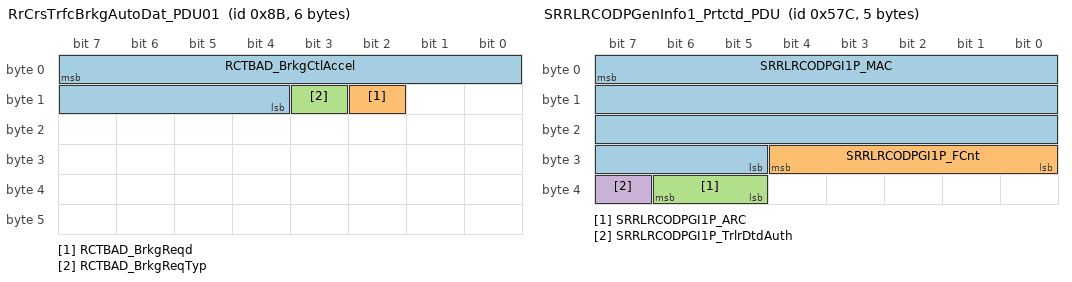
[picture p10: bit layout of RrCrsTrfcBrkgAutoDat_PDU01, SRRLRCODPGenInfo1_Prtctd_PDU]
BO_ 139 RrCrsTrfcBrkgAutoDat_PDU01: 6 SRR_SLR
 SG_ RCTBAD_BrkgCtlAccel : 7|12@0- (0.01,0) [-20.48|20.47] "m/s2" CGM
 SG_ RCTBAD_BrkgReqd : 10|1@0+ (1,0) [0|1] "" CGM
 SG_ RCTBAD_BrkgReqTyp : 11|1@0+ (1,0) [0|1] "" CGM

BO_ 1153 SDS_2_PDU01: 4 SRR_SLR
 SG_ RCTALSHSR_HptcStReqPuls : 5|6@0+ (1,0) [0|63] "pulses" CGM
 SG_ RCTALSHSR_HptcStReqSeqNum : 7|2@0+ (1,0) [0|3] "counts" CGM

BO_ 1154 SDS_2_PDU02: 4 SRR_SRR
 SG_ RCTARSHSR_HptcStReqPuls : 5|2@0+ (1,0) [0|3] "pulses" CGM
 SG_ RCTARSHSR_HptcStReqSeqNum : 7|2@0+ (1,0) [0|3] "counts" CGM

BO_ 613 SDS_3_PDU01: 4 SRR_LR_CR
 SG_ LtLnChgThrtAprchSpd : 7|8@0- (1,0) [-128|127] "Kph" CGM,FCM_LC

BO_ 1136 SDS_3_PDU02: 4 SRR_LR_CR
 SG_ LtFstAprchgVehObjDtd : 7|1@0+ (1,0) [0|1] "" CGM,EOCM,EOCM_HCP1,FCM_LC,SRR_SLR

BO_ 614 SDS_3_PDU03: 4 SRR_LR_CR
 SG_ RtLnChgThrtAprchSpd : 7|8@0- (1,0) [-128|127] "Kph" CGM,FCM_LC

BO_ 1137 SDS_3_PDU04: 4 SRR_LR_CR
 SG_ RtFstAprchgVehObjDtd : 7|1@0+ (1,0) [0|1] "" CGM,EOCM,EOCM_HCP1,FCM_LC,SRR_SRR

BO_ 1138 SDS_Width_CAN8_PDU01: 6 SRR_LR_CR
 SG_ RtSdObjDtdAdjTrlr : 7|1@0+ (1,0) [0|1] "" SRR_SRR

BO_ 1097 SRRLFODP_Brst1_PCSM_PDU: 8 SRR_LF
 SG_ SRRLFODP_Brst1_PCSM : 0|64@1+ (1,0) [0|1.84467e+019] "" EOCM,EOCM_HCP1,EOCM_HCP2

BO_ 1796 SRRLRCODPGenInfo1_PCSM_PDU: 8 SRR_LR_CR
 SG_ SRRLRCODPGenInfo1_PCSM : 0|64@1+ (1,0) [0|1.84467e+019] "" EOCM,EOCM_HCP1

BO_ 1404 SRRLRCODPGenInfo1_Prtctd_PDU: 5 SRR_LR_CR
 SG_ SRRLRCODPGI1P_MAC : 7|27@0+ (1,0) [0|1.34218e+008] "" EOCM,EOCM_HCP1
 SG_ SRRLRCODPGI1P_FCnt : 28|5@0+ (1,0) [0|31] "" EOCM,EOCM_HCP1
 SG_ SRRLRCODPGI1P_ARC : 38|2@0+ (1,0) [0|3] "" EOCM,EOCM_HCP1
 SG_ SRRLRCODPGI1P_TrlrDtdAuth : 39|1@0+ (1,0) [0|1] "" EOCM,EOCM_HCP1

BO_ 1098 SRRLRCODP_Brst1_PCSM_PDU: 8 SRR_LR_CR
 SG_ SRRLRCODP_Brst1_PCSM : 0|64@1+ (1,0) [0|1.84467e+019] "" EOCM,EOCM_HCP1,EOCM_HCP2

BO_ 1099 SRRRFODP_Brst1_PCSM_PDU: 8 SRR_RF
 SG_ SRRRFODP_Brst1_PCSM : 0|64@1+ (1,0) [0|1.84467e+019] "" EOCM,EOCM_HCP1,EOCM_HCP2

BO_ 1799 SRRRRODPGenInfo1_PCSM_PDU: 8 SRR_RR
 SG_ SRRRRODPGenInfo1_PCSM : 0|64@1+ (1,0) [0|1.84467e+019] "" EOCM,EOCM_HCP1

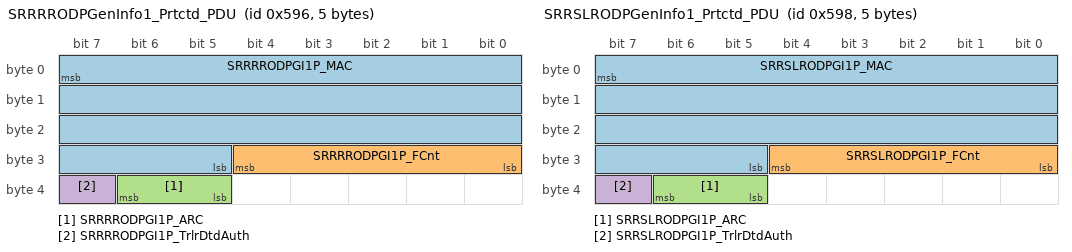
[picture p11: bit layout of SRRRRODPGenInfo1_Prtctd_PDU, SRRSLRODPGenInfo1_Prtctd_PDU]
BO_ 1430 SRRRRODPGenInfo1_Prtctd_PDU: 5 SRR_RR
 SG_ SRRRRODPGI1P_MAC : 7|27@0+ (1,0) [0|1.34218e+008] "" EOCM,EOCM_HCP1
 SG_ SRRRRODPGI1P_FCnt : 28|5@0+ (1,0) [0|31] "" EOCM,EOCM_HCP1
 SG_ SRRRRODPGI1P_ARC : 38|2@0+ (1,0) [0|3] "" EOCM,EOCM_HCP1
 SG_ SRRRRODPGI1P_TrlrDtdAuth : 39|1@0+ (1,0) [0|1] "" EOCM,EOCM_HCP1

BO_ 1100 SRRRRODP_Brst1_PCSM_PDU: 8 SRR_RR
 SG_ SRRRRODP_Brst1_PCSM : 0|64@1+ (1,0) [0|1.84467e+019] "" EOCM,EOCM_HCP1,EOCM_HCP2

BO_ 1804 SRRSLRODPGenInfo1_PCSM_PDU: 8 SRR_SLR
 SG_ SRRSLRODPGenInfo1_PCSM : 0|64@1+ (1,0) [0|1.84467e+019] "" EOCM,EOCM_HCP1

BO_ 1432 SRRSLRODPGenInfo1_Prtctd_PDU: 5 SRR_SLR
 SG_ SRRSLRODPGI1P_MAC : 7|27@0+ (1,0) [0|1.34218e+008] "" EOCM,EOCM_HCP1
 SG_ SRRSLRODPGI1P_FCnt : 28|5@0+ (1,0) [0|31] "" EOCM,EOCM_HCP1
 SG_ SRRSLRODPGI1P_ARC : 38|2@0+ (1,0) [0|3] "" EOCM,EOCM_HCP1
 SG_ SRRSLRODPGI1P_TrlrDtdAuth : 39|1@0+ (1,0) [0|1] "" EOCM,EOCM_HCP1

BO_ 1290 SRRSLRODP_Brst1_PCSM_PDU: 8 SRR_SLR
 SG_ SRRSLRODP_Brst1_PCSM : 0|64@1+ (1,0) [0|1.84467e+019] "" EOCM_HCP1,EOCM_HCP2

BO_ 1806 SRRSRRODPGenInfo1_PCSM_PDU: 8 SRR_SRR
 SG_ SRRSRRODPGenInfo1_PCSM : 0|64@1+ (1,0) [0|1.84467e+019] "" EOCM,EOCM_HCP1

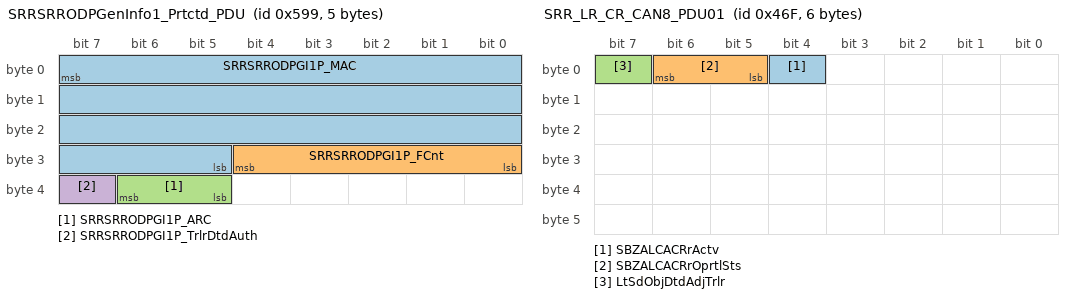
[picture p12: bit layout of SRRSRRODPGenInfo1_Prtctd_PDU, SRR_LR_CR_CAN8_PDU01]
BO_ 1433 SRRSRRODPGenInfo1_Prtctd_PDU: 5 SRR_SRR
 SG_ SRRSRRODPGI1P_MAC : 7|27@0+ (1,0) [0|1.34218e+008] "" EOCM,EOCM_HCP1
 SG_ SRRSRRODPGI1P_FCnt : 28|5@0+ (1,0) [0|31] "" EOCM,EOCM_HCP1
 SG_ SRRSRRODPGI1P_ARC : 38|2@0+ (1,0) [0|3] "" EOCM,EOCM_HCP1
 SG_ SRRSRRODPGI1P_TrlrDtdAuth : 39|1@0+ (1,0) [0|1] "" EOCM,EOCM_HCP1

BO_ 1291 SRRSRRODP_Brst1_PCSM_PDU: 8 SRR_SRR
 SG_ SRRSRRODP_Brst1_PCSM : 0|64@1+ (1,0) [0|1.84467e+019] "" EOCM_HCP1,EOCM_HCP2

BO_ 1135 SRR_LR_CR_CAN8_PDU01: 6 SRR_LR_CR
 SG_ SBZALCACRrActv : 4|1@0+ (1,0) [0|1] "" SRR_SLR
 SG_ SBZALCACRrOprtlSts : 6|2@0+ (1,0) [0|2] "" SRR_SLR
 SG_ LtSdObjDtdAdjTrlr : 7|1@0+ (1,0) [0|1] "" SRR_SLR

BO_ 1109 SRR_RR_CAN8_PDU02: 6 SRR_RR
 SG_ SBZALCARRActv : 5|1@0+ (1,0) [0|1] "" SRR_SLR
 SG_ SBZALCARROprtlSts : 7|2@0+ (1,0) [0|2] "" SRR_SLR

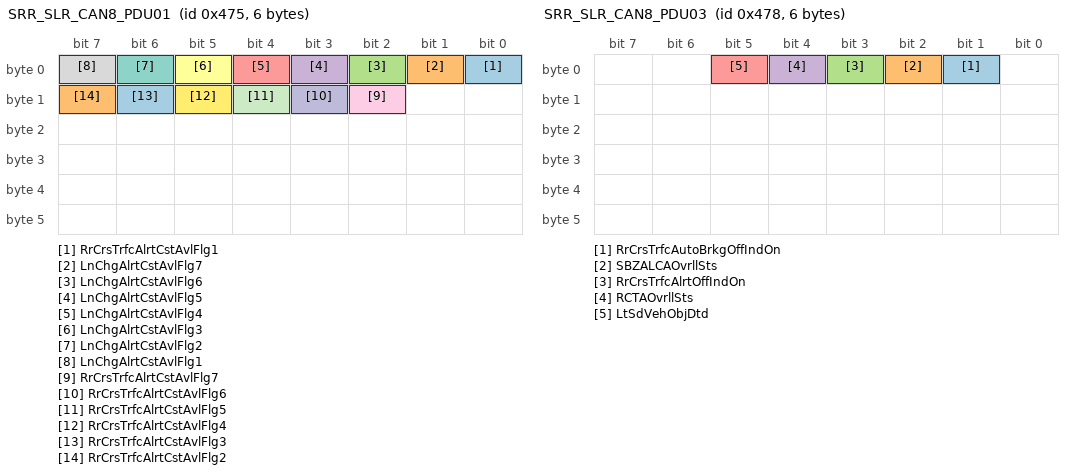
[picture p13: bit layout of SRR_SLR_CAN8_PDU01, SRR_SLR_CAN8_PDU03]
BO_ 1141 SRR_SLR_CAN8_PDU01: 6 SRR_SLR
 SG_ RrCrsTrfcAlrtCstAvlFlg1 : 0|1@0+ (1,0) [0|1] "" CGM
 SG_ LnChgAlrtCstAvlFlg7 : 1|1@0+ (1,0) [0|1] "" CGM
 SG_ LnChgAlrtCstAvlFlg6 : 2|1@0+ (1,0) [0|1] "" CGM
 SG_ LnChgAlrtCstAvlFlg5 : 3|1@0+ (1,0) [0|1] "" CGM
 SG_ LnChgAlrtCstAvlFlg4 : 4|1@0+ (1,0) [0|1] "" CGM
 SG_ LnChgAlrtCstAvlFlg3 : 5|1@0+ (1,0) [0|1] "" CGM
 SG_ LnChgAlrtCstAvlFlg2 : 6|1@0+ (1,0) [0|1] "" CGM
 SG_ LnChgAlrtCstAvlFlg1 : 7|1@0+ (1,0) [0|1] "" CGM
 SG_ RrCrsTrfcAlrtCstAvlFlg7 : 10|1@0+ (1,0) [0|1] "" CGM
 SG_ RrCrsTrfcAlrtCstAvlFlg6 : 11|1@0+ (1,0) [0|1] "" CGM
 SG_ RrCrsTrfcAlrtCstAvlFlg5 : 12|1@0+ (1,0) [0|1] "" CGM
 SG_ RrCrsTrfcAlrtCstAvlFlg4 : 13|1@0+ (1,0) [0|1] "" CGM
 SG_ RrCrsTrfcAlrtCstAvlFlg3 : 14|1@0+ (1,0) [0|1] "" CGM
 SG_ RrCrsTrfcAlrtCstAvlFlg2 : 15|1@0+ (1,0) [0|1] "" CGM

BO_ 1142 SRR_SLR_CAN8_PDU02: 6 SRR_SLR
 SG_ RrCrsTrfcAlrtLtSdChmEvntStat : 5|2@0+ (1,0) [0|2] "" CGM
 SG_ RrCrsTrfcAlrtLftIndCtrl : 7|2@0+ (1,0) [0|2] "" CGM

BO_ 1144 SRR_SLR_CAN8_PDU03: 6 SRR_SLR
 SG_ RrCrsTrfcAutoBrkgOffIndOn : 1|1@0+ (1,0) [0|1] "" CGM
 SG_ SBZALCAOvrllSts : 2|1@0+ (1,0) [0|1] "" SRR_SRR
 SG_ RrCrsTrfcAlrtOffIndOn : 3|1@0+ (1,0) [0|1] "" CGM
 SG_ RCTAOvrllSts : 4|1@0+ (1,0) [0|1] "" SRR_SRR
 SG_ LtSdVehObjDtd : 5|1@0+ (1,0) [0|1] "" CGM,FCM_LC

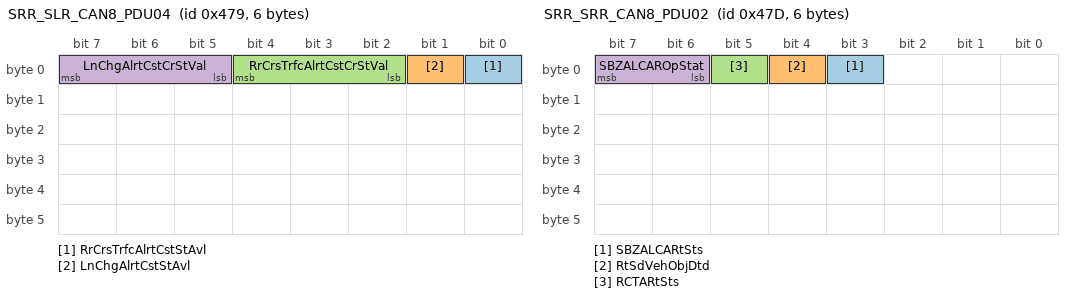
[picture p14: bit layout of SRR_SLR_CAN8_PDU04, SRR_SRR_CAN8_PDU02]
BO_ 1145 SRR_SLR_CAN8_PDU04: 6 SRR_SLR
 SG_ RrCrsTrfcAlrtCstStAvl : 0|1@0+ (1,0) [0|1] "" CGM
 SG_ LnChgAlrtCstStAvl : 1|1@0+ (1,0) [0|1] "" CGM
 SG_ RrCrsTrfcAlrtCstCrStVal : 4|3@0+ (1,0) [0|7] "" CGM,SRR_SRR
 SG_ LnChgAlrtCstCrStVal : 7|3@0+ (1,0) [0|7] "" CGM,SRR_LR_CR,SRR_RR,SRR_SRR

BO_ 1147 SRR_SRR_CAN8_PDU01: 6 SRR_SRR
 SG_ RrCrsTrfcAlrtRtSdChmEvntStat : 5|2@0+ (1,0) [0|2] "" CGM
 SG_ RrCrsTrfcAlrtRgIndCtrl : 7|2@0+ (1,0) [0|2] "" CGM

BO_ 1149 SRR_SRR_CAN8_PDU02: 6 SRR_SRR
 SG_ SBZALCARtSts : 3|1@0+ (1,0) [0|1] "" SRR_SLR
 SG_ RtSdVehObjDtd : 4|1@0+ (1,0) [0|1] "" CGM,FCM_LC
 SG_ RCTARtSts : 5|1@0+ (1,0) [0|1] "" SRR_SLR
 SG_ SBZALCAROpStat : 7|2@0+ (1,0) [0|2] "" SRR_SLR

BO_ 1155 Side_Blind_Spot_2_PDU01: 4 SRR_SLR
 SG_ SBZALCAOvrllOplSts : 7|2@0+ (1,0) [0|2] "" CGM,SRR_SRR

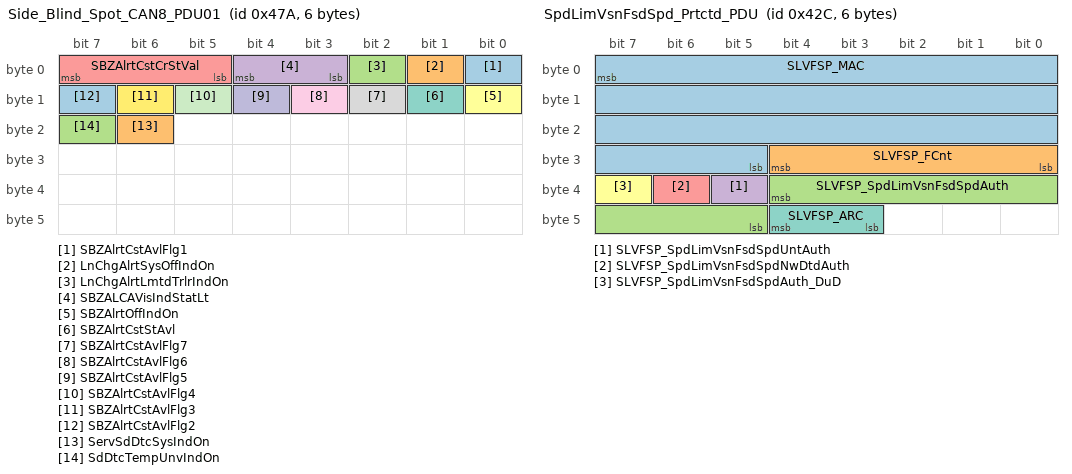
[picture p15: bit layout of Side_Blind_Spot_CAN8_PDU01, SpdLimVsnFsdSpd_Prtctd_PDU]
BO_ 1146 Side_Blind_Spot_CAN8_PDU01: 6 SRR_SLR
 SG_ SBZAlrtCstAvlFlg1 : 0|1@0+ (1,0) [0|1] "" CGM
 SG_ LnChgAlrtSysOffIndOn : 1|1@0+ (1,0) [0|1] "" CGM
 SG_ LnChgAlrtLmtdTrlrIndOn : 2|1@0+ (1,0) [0|1] "" CGM
 SG_ SBZALCAVisIndStatLt : 4|2@0+ (1,0) [0|2] "" CGM
 SG_ SBZAlrtCstCrStVal : 7|3@0+ (1,0) [0|7] "" CGM,SRR_LR_CR,SRR_RR,SRR_SRR
 SG_ SBZAlrtOffIndOn : 8|1@0+ (1,0) [0|1] "" CGM
 SG_ SBZAlrtCstStAvl : 9|1@0+ (1,0) [0|1] "" CGM
 SG_ SBZAlrtCstAvlFlg7 : 10|1@0+ (1,0) [0|1] "" CGM
 SG_ SBZAlrtCstAvlFlg6 : 11|1@0+ (1,0) [0|1] "" CGM
 SG_ SBZAlrtCstAvlFlg5 : 12|1@0+ (1,0) [0|1] "" CGM
 SG_ SBZAlrtCstAvlFlg4 : 13|1@0+ (1,0) [0|1] "" CGM
 SG_ SBZAlrtCstAvlFlg3 : 14|1@0+ (1,0) [0|1] "" CGM
 SG_ SBZAlrtCstAvlFlg2 : 15|1@0+ (1,0) [0|1] "" CGM
 SG_ ServSdDtcSysIndOn : 22|1@0+ (1,0) [0|1] "" CGM
 SG_ SdDtcTempUnvIndOn : 23|1@0+ (1,0) [0|1] "" CGM

BO_ 1150 Side_Blind_Spot_CAN8_PDU02: 6 SRR_SRR
 SG_ SBZALCAVisIndStatRt : 7|2@0+ (1,0) [0|2] "" CGM

BO_ 1073 SpdLimVsnFsdSpd_PCSM_PDU: 8 FCM_LC
 SG_ SpdLimVsnFsdSpd_PCSM : 0|64@1+ (1,0) [0|1.84467e+019] "" EOCM,EOCM_HCP1

BO_ 1068 SpdLimVsnFsdSpd_Prtctd_PDU: 6 FCM_LC
 SG_ SLVFSP_MAC : 7|27@0+ (1,0) [0|1.34218e+008] "" CGM,EOCM,EOCM_HCP1
 SG_ SLVFSP_FCnt : 28|5@0+ (1,0) [0|31] "" CGM,EOCM,EOCM_HCP1
 SG_ SLVFSP_SpdLimVsnFsdSpdAuth : 36|8@0+ (1,0) [0|255] "" CGM,EOCM,EOCM_HCP1
 SG_ SLVFSP_SpdLimVsnFsdSpdUntAuth : 37|1@0+ (1,0) [0|1] "" CGM,EOCM,EOCM_HCP1
 SG_ SLVFSP_SpdLimVsnFsdSpdNwDtdAuth : 38|1@0+ (1,0) [0|1] "" CGM,EOCM,EOCM_HCP1
 SG_ SLVFSP_SpdLimVsnFsdSpdAuth_DuD : 39|1@0+ (1,0) [0|1] "" CGM,EOCM,EOCM_HCP1
 SG_ SLVFSP_ARC : 44|2@0+ (1,0) [0|3] "" CGM,EOCM,EOCM_HCP1

BO_ 1842 SpnsnGenInfo2_PCSM_PDU: 8 CGM
 SG_ SpnsnGenInfo2_PCSM : 0|64@1+ (1,0) [0|1.84467e+019] "" FCM_LC

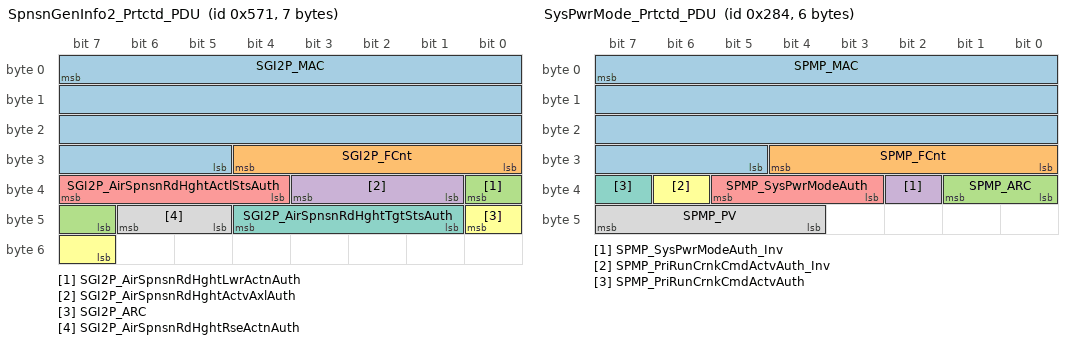
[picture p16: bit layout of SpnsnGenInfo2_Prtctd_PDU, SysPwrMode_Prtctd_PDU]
BO_ 1393 SpnsnGenInfo2_Prtctd_PDU: 7 CGM
 SG_ SGI2P_MAC : 7|27@0+ (1,0) [0|1.34218e+008] "" FCM_LC
 SG_ SGI2P_FCnt : 28|5@0+ (1,0) [0|31] "" FCM_LC
 SG_ SGI2P_AirSpnsnRdHghtLwrActnAuth : 32|2@0+ (1,0) [0|3] "" FCM_LC
 SG_ SGI2P_AirSpnsnRdHghtActvAxlAuth : 35|3@0+ (1,0) [0|4] "" FCM_LC
 SG_ SGI2P_AirSpnsnRdHghtActlStsAuth : 39|4@0+ (1,0) [0|9] "" FCM_LC
 SG_ SGI2P_ARC : 40|2@0+ (1,0) [0|3] "" FCM_LC
 SG_ SGI2P_AirSpnsnRdHghtTgtStsAuth : 44|4@0+ (1,0) [0|9] "" FCM_LC
 SG_ SGI2P_AirSpnsnRdHghtRseActnAuth : 46|2@0+ (1,0) [0|3] "" FCM_LC

BO_ 522 SysPwrMode_PCSM_PDU: 8 CGM
 SG_ SysPwrMode_PCSM : 0|64@1+ (1,0) [0|1.84467e+019] "" EOCM_HCP2,FCM_LC,HDLM,LRR,LRR_HC,SRR_LF,SRR_LR_CR,SRR_RF,SRR_RR,SRR_SLR,SRR_SRR

BO_ 644 SysPwrMode_Prtctd_PDU: 6 CGM
 SG_ SPMP_MAC : 7|27@0+ (1,0) [0|1.34218e+008] "" EOCM_HCP2,FCM_LC,HDLM,LRR,LRR_HC,SRR_LF,SRR_LR_CR,SRR_RF,SRR_RR,SRR_SLR,SRR_SRR
 SG_ SPMP_FCnt : 28|5@0+ (1,0) [0|31] "" EOCM_HCP2,FCM_LC,HDLM,LRR,LRR_HC,SRR_LF,SRR_LR_CR,SRR_RF,SRR_RR,SRR_SLR,SRR_SRR
 SG_ SPMP_ARC : 33|2@0+ (1,0) [0|3] "" EOCM_HCP2,FCM_LC,HDLM,LRR,LRR_HC,SRR_LF,SRR_LR_CR,SRR_RF,SRR_RR,SRR_SLR,SRR_SRR
 SG_ SPMP_SysPwrModeAuth_Inv : 34|1@0+ (1,0) [0|1] "" EOCM_HCP2,FCM_LC,HDLM,LRR,LRR_HC,SRR_LF,SRR_LR_CR,SRR_RF,SRR_RR,SRR_SLR,SRR_SRR
 SG_ SPMP_SysPwrModeAuth : 37|3@0+ (1,0) [0|4] "" EOCM_HCP2,FCM_LC,HDLM,LRR,LRR_HC,SRR_LF,SRR_LR_CR,SRR_RF,SRR_RR,SRR_SLR,SRR_SRR
 SG_ SPMP_PriRunCrnkCmdActvAuth_Inv : 38|1@0+ (1,0) [0|1] "" EOCM_HCP2,FCM_LC,HDLM,LRR,LRR_HC,SRR_LF,SRR_LR_CR,SRR_RF,SRR_RR,SRR_SLR,SRR_SRR
 SG_ SPMP_PriRunCrnkCmdActvAuth : 39|1@0+ (1,0) [0|1] "" EOCM_HCP2,FCM_LC,HDLM,LRR,LRR_HC,SRR_LF,SRR_LR_CR,SRR_RF,SRR_RR,SRR_SLR,SRR_SRR
 SG_ SPMP_PV : 47|4@0+ (1,0) [0|15] "" EOCM_HCP2,FCM_LC,HDLM,LRR,LRR_HC,SRR_LF,SRR_LR_CR,SRR_RF,SRR_RR,SRR_SLR,SRR_SRR

BO_ 568 TrnsEstGr_PCSM_PDU: 8 CGM
 SG_ TrnsEstGr_PCSM : 0|64@1+ (1,0) [0|1.84467e+019] "" FCM_LC

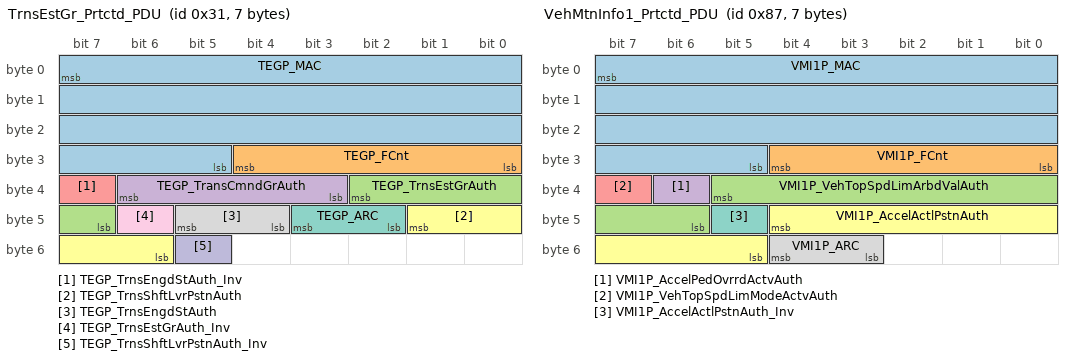
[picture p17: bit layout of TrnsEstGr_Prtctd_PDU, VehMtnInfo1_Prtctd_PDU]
BO_ 49 TrnsEstGr_Prtctd_PDU: 7 CGM
 SG_ TEGP_MAC : 7|27@0+ (1,0) [0|1.34218e+008] "" FCM_LC
 SG_ TEGP_FCnt : 28|5@0+ (1,0) [0|31] "" FCM_LC
 SG_ TEGP_TrnsEstGrAuth : 34|4@0+ (1,0) [0|15] "" FCM_LC
 SG_ TEGP_TransCmndGrAuth : 38|4@0+ (1,0) [0|15] "" FCM_LC
 SG_ TEGP_TrnsEngdStAuth_Inv : 39|1@0+ (1,0) [0|1] "" FCM_LC
 SG_ TEGP_TrnsShftLvrPstnAuth : 41|4@0+ (1,0) [0|14] "" FCM_LC
 SG_ TEGP_ARC : 43|2@0+ (1,0) [0|3] "" FCM_LC
 SG_ TEGP_TrnsEngdStAuth : 45|2@0+ (1,0) [0|3] "" FCM_LC
 SG_ TEGP_TrnsEstGrAuth_Inv : 46|1@0+ (1,0) [0|1] "" FCM_LC
 SG_ TEGP_TrnsShftLvrPstnAuth_Inv : 53|1@0+ (1,0) [0|1] "" FCM_LC

BO_ 1644 USDT_Req_BootMode_To_EOCM_CAN_8_: 64 CGM

BO_ 1636 USDT_Req_BootMode_To_EOCM_HCP1_C: 64 CGM

BO_ 1755 USDT_Req_BootMode_To_EOCM_HCP2_C: 64 CGM

BO_ 1724 USDT_Req_BootMode_To_FCM_LC_CAN_: 64 CGM

BO_ 1646 USDT_Req_BootMode_To_HDLM_CAN_8_: 64 CGM

BO_ 1746 USDT_Req_BootMode_To_LRR_CAN_8_c: 64 CGM

BO_ 1747 USDT_Req_BootMode_To_SRR_LF_CAN_: 64 CGM

BO_ 1751 USDT_Req_BootMode_To_SRR_LR_CR_C: 64 CGM

BO_ 1750 USDT_Req_BootMode_To_SRR_RF_CAN_: 64 CGM

BO_ 1752 USDT_Req_BootMode_To_SRR_RR_CAN_: 64 CGM

BO_ 1753 USDT_Req_BootMode_To_SRR_SLR_CAN: 64 CGM

BO_ 1754 USDT_Req_BootMode_To_SRR_SRR_CAN: 64 CGM

BO_ 2430336753 USDT_Req_From_TEST_TOOL_1_To_All: 64 CGM

BO_ 2431385329 USDT_Req_From_TEST_TOOL_1_To_CAN: 64 CGM

BO_ 2497342705 USDT_Req_From_TEST_TOOL_1_To_EOC: 64 CGM

BO_ 2497340657 USDT_Req_From_TEST_TOOL_1_To_E01: 64 CGM

BO_ 2497371121 USDT_Req_From_TEST_TOOL_1_To_E02: 64 CGM

BO_ 2565827825 USDT_Req_From_TEST_TOOL_1_To_E03: 64 CGM

BO_ 2497363185 USDT_Req_From_TEST_TOOL_1_To_FCM: 64 CGM

BO_ 2497343217 USDT_Req_From_TEST_TOOL_1_To_HDL: 64 CGM

BO_ 2497368817 USDT_Req_From_TEST_TOOL_1_To_LRR: 64 CGM

BO_ 2497369073 USDT_Req_From_TEST_TOOL_1_To_SRR: 64 CGM

BO_ 2497370097 USDT_Req_From_TEST_TOOL_1_To_S01: 64 CGM

BO_ 2497369841 USDT_Req_From_TEST_TOOL_1_To_S02: 64 CGM

BO_ 2497370353 USDT_Req_From_TEST_TOOL_1_To_S03: 64 CGM

BO_ 2497370609 USDT_Req_From_TEST_TOOL_1_To_S04: 64 CGM

BO_ 2497370865 USDT_Req_From_TEST_TOOL_1_To_S05: 64 CGM

BO_ 2430336754 USDT_Req_From_TEST_TOOL_2_To_All: 64 CGM

BO_ 2431385330 USDT_Req_From_TEST_TOOL_2_To_CAN: 64 CGM

BO_ 2497342706 USDT_Req_From_TEST_TOOL_2_To_EOC: 64 CGM

BO_ 2497340658 USDT_Req_From_TEST_TOOL_2_To_E01: 64 CGM

BO_ 2497371122 USDT_Req_From_TEST_TOOL_2_To_E02: 64 CGM

BO_ 2497363186 USDT_Req_From_TEST_TOOL_2_To_FCM: 64 CGM

BO_ 2497368818 USDT_Req_From_TEST_TOOL_2_To_LRR: 64 CGM

BO_ 2497369074 USDT_Req_From_TEST_TOOL_2_To_SRR: 64 CGM

BO_ 2497370098 USDT_Req_From_TEST_TOOL_2_To_S01: 64 CGM

BO_ 2497369842 USDT_Req_From_TEST_TOOL_2_To_S02: 64 CGM

BO_ 2497370354 USDT_Req_From_TEST_TOOL_2_To_S03: 64 CGM

BO_ 2497370610 USDT_Req_From_TEST_TOOL_2_To_S04: 64 CGM

BO_ 2497370866 USDT_Req_From_TEST_TOOL_2_To_S05: 64 CGM

BO_ 2430336755 USDT_Req_From_TEST_TOOL_3_To_All: 8 CGM

BO_ 2431385331 USDT_Req_From_TEST_TOOL_3_To_CAN: 8 CGM

BO_ 2497342707 USDT_Req_From_TEST_TOOL_3_To_EOC: 8 CGM

BO_ 2497340659 USDT_Req_From_TEST_TOOL_3_To_E01: 8 CGM

BO_ 2497371123 USDT_Req_From_TEST_TOOL_3_To_E02: 8 CGM

BO_ 2497363187 USDT_Req_From_TEST_TOOL_3_To_FCM: 8 CGM

BO_ 2497343219 USDT_Req_From_TEST_TOOL_3_To_HDL: 8 CGM

BO_ 2497368819 USDT_Req_From_TEST_TOOL_3_To_LRR: 8 CGM

BO_ 2497369075 USDT_Req_From_TEST_TOOL_3_To_SRR: 8 CGM

BO_ 2497370099 USDT_Req_From_TEST_TOOL_3_To_S01: 8 CGM

BO_ 2497369843 USDT_Req_From_TEST_TOOL_3_To_S02: 8 CGM

BO_ 2497370355 USDT_Req_From_TEST_TOOL_3_To_S03: 8 CGM

BO_ 2497370611 USDT_Req_From_TEST_TOOL_3_To_S04: 8 CGM

BO_ 2497370867 USDT_Req_From_TEST_TOOL_3_To_S05: 8 CGM

BO_ 2430336756 USDT_Req_From_TEST_TOOL_4_To_All: 64 CGM

BO_ 2431385332 USDT_Req_From_TEST_TOOL_4_To_CAN: 64 CGM

BO_ 2497342708 USDT_Req_From_TEST_TOOL_4_To_EOC: 64 CGM

BO_ 2497340660 USDT_Req_From_TEST_TOOL_4_To_E01: 64 CGM

BO_ 2497371124 USDT_Req_From_TEST_TOOL_4_To_E02: 64 CGM

BO_ 2497363188 USDT_Req_From_TEST_TOOL_4_To_FCM: 64 CGM

BO_ 2497343220 USDT_Req_From_TEST_TOOL_4_To_HDL: 64 CGM

BO_ 2497368820 USDT_Req_From_TEST_TOOL_4_To_LRR: 64 CGM

BO_ 2497369076 USDT_Req_From_TEST_TOOL_4_To_SRR: 64 CGM

BO_ 2497370100 USDT_Req_From_TEST_TOOL_4_To_S01: 64 CGM

BO_ 2497369844 USDT_Req_From_TEST_TOOL_4_To_S02: 64 CGM

BO_ 2497370356 USDT_Req_From_TEST_TOOL_4_To_S03: 64 CGM

BO_ 2497370612 USDT_Req_From_TEST_TOOL_4_To_S04: 64 CGM

BO_ 2497370868 USDT_Req_From_TEST_TOOL_4_To_S05: 64 CGM

BO_ 2430336757 USDT_Req_From_TEST_TOOL_5_To_All: 64 CGM

BO_ 2431385333 USDT_Req_From_TEST_TOOL_5_To_CAN: 64 CGM

BO_ 2497342709 USDT_Req_From_TEST_TOOL_5_To_EOC: 64 CGM

BO_ 2497340661 USDT_Req_From_TEST_TOOL_5_To_E01: 64 CGM

BO_ 2497371125 USDT_Req_From_TEST_TOOL_5_To_E02: 64 CGM

BO_ 2497363189 USDT_Req_From_TEST_TOOL_5_To_FCM: 64 CGM

BO_ 2497343221 USDT_Req_From_TEST_TOOL_5_To_HDL: 64 CGM

BO_ 2497368821 USDT_Req_From_TEST_TOOL_5_To_LRR: 64 CGM

BO_ 2497369077 USDT_Req_From_TEST_TOOL_5_To_SRR: 64 CGM

BO_ 2497370101 USDT_Req_From_TEST_TOOL_5_To_S01: 64 CGM

BO_ 2497369845 USDT_Req_From_TEST_TOOL_5_To_S02: 64 CGM

BO_ 2497370357 USDT_Req_From_TEST_TOOL_5_To_S03: 64 CGM

BO_ 2497370613 USDT_Req_From_TEST_TOOL_5_To_S04: 64 CGM

BO_ 2497370869 USDT_Req_From_TEST_TOOL_5_To_S05: 64 CGM

BO_ 2430336758 USDT_Req_From_TEST_TOOL_6_To_All: 8 CGM

BO_ 2431385334 USDT_Req_From_TEST_TOOL_6_To_CAN: 8 CGM

BO_ 2497342710 USDT_Req_From_TEST_TOOL_6_To_EOC: 8 CGM

BO_ 2497340662 USDT_Req_From_TEST_TOOL_6_To_E01: 8 CGM

BO_ 2497371126 USDT_Req_From_TEST_TOOL_6_To_E02: 8 CGM

BO_ 2497363190 USDT_Req_From_TEST_TOOL_6_To_FCM: 8 CGM

BO_ 2497343222 USDT_Req_From_TEST_TOOL_6_To_HDL: 8 CGM

BO_ 2497368822 USDT_Req_From_TEST_TOOL_6_To_LRR: 8 CGM

BO_ 2497369078 USDT_Req_From_TEST_TOOL_6_To_SRR: 8 CGM

BO_ 2497370102 USDT_Req_From_TEST_TOOL_6_To_S01: 8 CGM

BO_ 2497369846 USDT_Req_From_TEST_TOOL_6_To_S02: 8 CGM

BO_ 2497370358 USDT_Req_From_TEST_TOOL_6_To_S03: 8 CGM

BO_ 2497370614 USDT_Req_From_TEST_TOOL_6_To_S04: 8 CGM

BO_ 2497370870 USDT_Req_From_TEST_TOOL_6_To_S05: 8 CGM

BO_ 2497379436 USDT_Rsp_BootMode_From_EOCM_CAN_: 64 EOCM

BO_ 2497379428 USDT_Rsp_BootMode_From_EOCM_HCP1: 64 EOCM_HCP1

BO_ 2497379547 USDT_Rsp_BootMode_From_EOCM_HCP2: 64 EOCM_HCP2

BO_ 2497379516 USDT_Rsp_BootMode_From_FCM_LC_CA: 64 FCM_LC

BO_ 2497379438 USDT_Rsp_BootMode_From_HDLM_CAN_: 64 HDLM

BO_ 2497379538 USDT_Rsp_BootMode_From_LRR_CAN_8: 64 LRR

BO_ 2497379539 USDT_Rsp_BootMode_From_SRR_LF_CA: 64 SRR_LF

BO_ 2497379543 USDT_Rsp_BootMode_From_SRR_LR_CR: 64 SRR_LR_CR

BO_ 2497379542 USDT_Rsp_BootMode_From_SRR_RF_CA: 64 SRR_RF

BO_ 2497379544 USDT_Rsp_BootMode_From_SRR_RR_CA: 64 SRR_RR

BO_ 2497379545 USDT_Rsp_BootMode_From_SRR_SLR_C: 64 SRR_SLR

BO_ 2497379546 USDT_Rsp_BootMode_From_SRR_SRR_C: 64 SRR_SRR

BO_ 2497376620 USDT_Rsp_From_EOCM_CAN_8_connect: 64 EOCM

BO_ 2497376876 USDT_Rsp_From_EOCM_CAN_8_conne01: 64 EOCM

BO_ 2497377132 USDT_Rsp_From_EOCM_CAN_8_conne02: 8 EOCM

BO_ 2497377388 USDT_Rsp_From_EOCM_CAN_8_conne03: 64 EOCM

BO_ 2497377644 USDT_Rsp_From_EOCM_CAN_8_conne04: 64 EOCM

BO_ 2497377900 USDT_Rsp_From_EOCM_CAN_8_conne05: 8 EOCM

BO_ 2497376612 USDT_Rsp_From_EOCM_HCP1_CAN_8_co: 64 EOCM_HCP1

BO_ 2497376868 USDT_Rsp_From_EOCM_HCP1_CAN_8_01: 64 EOCM_HCP1

BO_ 2497377124 USDT_Rsp_From_EOCM_HCP1_CAN_8_02: 8 EOCM_HCP1

BO_ 2497377380 USDT_Rsp_From_EOCM_HCP1_CAN_8_03: 64 EOCM_HCP1

BO_ 2497377636 USDT_Rsp_From_EOCM_HCP1_CAN_8_04: 64 EOCM_HCP1

BO_ 2497377892 USDT_Rsp_From_EOCM_HCP1_CAN_8_05: 8 EOCM_HCP1

BO_ 2497376731 USDT_Rsp_From_EOCM_HCP2_CAN_8_co: 64 EOCM_HCP2

BO_ 2497376987 USDT_Rsp_From_EOCM_HCP2_CAN_8_01: 64 EOCM_HCP2

BO_ 2497377243 USDT_Rsp_From_EOCM_HCP2_CAN_8_02: 8 EOCM_HCP2

BO_ 2497377499 USDT_Rsp_From_EOCM_HCP2_CAN_8_03: 64 EOCM_HCP2

BO_ 2497377755 USDT_Rsp_From_EOCM_HCP2_CAN_8_04: 64 EOCM_HCP2

BO_ 2497378011 USDT_Rsp_From_EOCM_HCP2_CAN_8_05: 8 EOCM_HCP2

BO_ 2565861740 USDT_Rsp_From_EOCM_XCP_CAN_8_con: 64 EOCM

BO_ 2497376700 USDT_Rsp_From_FCM_LC_CAN_8_conne: 64 FCM_LC

BO_ 2497376956 USDT_Rsp_From_FCM_LC_CAN_8_con01: 64 FCM_LC

BO_ 2497377212 USDT_Rsp_From_FCM_LC_CAN_8_con02: 8 FCM_LC

BO_ 2497377468 USDT_Rsp_From_FCM_LC_CAN_8_con03: 64 FCM_LC

BO_ 2497377724 USDT_Rsp_From_FCM_LC_CAN_8_con04: 64 FCM_LC

BO_ 2497377980 USDT_Rsp_From_FCM_LC_CAN_8_con05: 8 FCM_LC

BO_ 2497376622 USDT_Rsp_From_HDLM_CAN_8_connect: 64 HDLM

BO_ 2497377134 USDT_Rsp_From_HDLM_CAN_8_conne01: 8 HDLM

BO_ 2497377390 USDT_Rsp_From_HDLM_CAN_8_conne02: 64 HDLM

BO_ 2497377646 USDT_Rsp_From_HDLM_CAN_8_conne03: 64 HDLM

BO_ 2497377902 USDT_Rsp_From_HDLM_CAN_8_conne04: 8 HDLM

BO_ 2497376722 USDT_Rsp_From_LRR_CAN_8_connecto: 64 LRR

BO_ 2497376978 USDT_Rsp_From_LRR_CAN_8_connec01: 64 LRR

BO_ 2497377234 USDT_Rsp_From_LRR_CAN_8_connec02: 8 LRR

BO_ 2497377490 USDT_Rsp_From_LRR_CAN_8_connec03: 64 LRR

BO_ 2497377746 USDT_Rsp_From_LRR_CAN_8_connec04: 64 LRR

BO_ 2497378002 USDT_Rsp_From_LRR_CAN_8_connec05: 8 LRR

BO_ 2497376723 USDT_Rsp_From_SRR_LF_CAN_8_conne: 64 SRR_LF

BO_ 2497376979 USDT_Rsp_From_SRR_LF_CAN_8_con01: 64 SRR_LF

BO_ 2497377235 USDT_Rsp_From_SRR_LF_CAN_8_con02: 8 SRR_LF

BO_ 2497377491 USDT_Rsp_From_SRR_LF_CAN_8_con03: 64 SRR_LF

BO_ 2497377747 USDT_Rsp_From_SRR_LF_CAN_8_con04: 64 SRR_LF

BO_ 2497378003 USDT_Rsp_From_SRR_LF_CAN_8_con05: 8 SRR_LF

BO_ 2497376727 USDT_Rsp_From_SRR_LR_CR_CAN_8_co: 64 SRR_LR_CR

BO_ 2497376983 USDT_Rsp_From_SRR_LR_CR_CAN_8_01: 64 SRR_LR_CR

BO_ 2497377239 USDT_Rsp_From_SRR_LR_CR_CAN_8_02: 8 SRR_LR_CR

BO_ 2497377495 USDT_Rsp_From_SRR_LR_CR_CAN_8_03: 64 SRR_LR_CR

BO_ 2497377751 USDT_Rsp_From_SRR_LR_CR_CAN_8_04: 64 SRR_LR_CR

BO_ 2497378007 USDT_Rsp_From_SRR_LR_CR_CAN_8_05: 8 SRR_LR_CR

BO_ 2497376726 USDT_Rsp_From_SRR_RF_CAN_8_conne: 64 SRR_RF

BO_ 2497376982 USDT_Rsp_From_SRR_RF_CAN_8_con01: 64 SRR_RF

BO_ 2497377238 USDT_Rsp_From_SRR_RF_CAN_8_con02: 8 SRR_RF

BO_ 2497377494 USDT_Rsp_From_SRR_RF_CAN_8_con03: 64 SRR_RF

BO_ 2497377750 USDT_Rsp_From_SRR_RF_CAN_8_con04: 64 SRR_RF

BO_ 2497378006 USDT_Rsp_From_SRR_RF_CAN_8_con05: 8 SRR_RF

BO_ 2497376728 USDT_Rsp_From_SRR_RR_CAN_8_conne: 64 SRR_RR

BO_ 2497376984 USDT_Rsp_From_SRR_RR_CAN_8_con01: 64 SRR_RR

BO_ 2497377240 USDT_Rsp_From_SRR_RR_CAN_8_con02: 8 SRR_RR

BO_ 2497377496 USDT_Rsp_From_SRR_RR_CAN_8_con03: 64 SRR_RR

BO_ 2497377752 USDT_Rsp_From_SRR_RR_CAN_8_con04: 64 SRR_RR

BO_ 2497378008 USDT_Rsp_From_SRR_RR_CAN_8_con05: 8 SRR_RR

BO_ 2497376729 USDT_Rsp_From_SRR_SLR_CAN_8_conn: 64 SRR_SLR

BO_ 2497376985 USDT_Rsp_From_SRR_SLR_CAN_8_co01: 64 SRR_SLR

BO_ 2497377241 USDT_Rsp_From_SRR_SLR_CAN_8_co02: 8 SRR_SLR

BO_ 2497377497 USDT_Rsp_From_SRR_SLR_CAN_8_co03: 64 SRR_SLR

BO_ 2497377753 USDT_Rsp_From_SRR_SLR_CAN_8_co04: 64 SRR_SLR

BO_ 2497378009 USDT_Rsp_From_SRR_SLR_CAN_8_co05: 8 SRR_SLR

BO_ 2497376730 USDT_Rsp_From_SRR_SRR_CAN_8_conn: 64 SRR_SRR

BO_ 2497376986 USDT_Rsp_From_SRR_SRR_CAN_8_co01: 64 SRR_SRR

BO_ 2497377242 USDT_Rsp_From_SRR_SRR_CAN_8_co02: 8 SRR_SRR

BO_ 2497377498 USDT_Rsp_From_SRR_SRR_CAN_8_co03: 64 SRR_SRR

BO_ 2497377754 USDT_Rsp_From_SRR_SRR_CAN_8_co04: 64 SRR_SRR

BO_ 2497378010 USDT_Rsp_From_SRR_SRR_CAN_8_co05: 8 SRR_SRR

BO_ 2497507692 UUDT_Rsp_From_EOCM_CAN_8_connect: 64 EOCM

BO_ 2497507948 UUDT_Rsp_From_EOCM_CAN_8_conne01: 64 EOCM

BO_ 2497508204 UUDT_Rsp_From_EOCM_CAN_8_conne02: 8 EOCM

BO_ 2497508460 UUDT_Rsp_From_EOCM_CAN_8_conne03: 64 EOCM

BO_ 2497508716 UUDT_Rsp_From_EOCM_CAN_8_conne04: 64 EOCM

BO_ 2497508972 UUDT_Rsp_From_EOCM_CAN_8_conne05: 8 EOCM

BO_ 2497507684 UUDT_Rsp_From_EOCM_HCP1_CAN_8_co: 64 EOCM_HCP1

BO_ 2497507940 UUDT_Rsp_From_EOCM_HCP1_CAN_8_01: 64 EOCM_HCP1

BO_ 2497508196 UUDT_Rsp_From_EOCM_HCP1_CAN_8_02: 8 EOCM_HCP1

BO_ 2497508452 UUDT_Rsp_From_EOCM_HCP1_CAN_8_03: 64 EOCM_HCP1

BO_ 2497508708 UUDT_Rsp_From_EOCM_HCP1_CAN_8_04: 64 EOCM_HCP1

BO_ 2497508964 UUDT_Rsp_From_EOCM_HCP1_CAN_8_05: 8 EOCM_HCP1

BO_ 2497507803 UUDT_Rsp_From_EOCM_HCP2_CAN_8_co: 64 EOCM_HCP2

BO_ 2497508059 UUDT_Rsp_From_EOCM_HCP2_CAN_8_01: 64 EOCM_HCP2

BO_ 2497508315 UUDT_Rsp_From_EOCM_HCP2_CAN_8_02: 8 EOCM_HCP2

BO_ 2497508571 UUDT_Rsp_From_EOCM_HCP2_CAN_8_03: 64 EOCM_HCP2

BO_ 2497508827 UUDT_Rsp_From_EOCM_HCP2_CAN_8_04: 64 EOCM_HCP2

BO_ 2497509083 UUDT_Rsp_From_EOCM_HCP2_CAN_8_05: 8 EOCM_HCP2

BO_ 2497507772 UUDT_Rsp_From_FCM_LC_CAN_8_conne: 64 FCM_LC

BO_ 2497508028 UUDT_Rsp_From_FCM_LC_CAN_8_con01: 64 FCM_LC

BO_ 2497508284 UUDT_Rsp_From_FCM_LC_CAN_8_con02: 8 FCM_LC

BO_ 2497508540 UUDT_Rsp_From_FCM_LC_CAN_8_con03: 64 FCM_LC

BO_ 2497508796 UUDT_Rsp_From_FCM_LC_CAN_8_con04: 64 FCM_LC

BO_ 2497509052 UUDT_Rsp_From_FCM_LC_CAN_8_con05: 8 FCM_LC

BO_ 2497507694 UUDT_Rsp_From_HDLM_CAN_8_connect: 64 HDLM

BO_ 2497508206 UUDT_Rsp_From_HDLM_CAN_8_conne01: 8 HDLM

BO_ 2497508974 UUDT_Rsp_From_HDLM_CAN_8_conne02: 8 HDLM

BO_ 2497507794 UUDT_Rsp_From_LRR_CAN_8_connecto: 64 LRR

BO_ 2497508050 UUDT_Rsp_From_LRR_CAN_8_connec01: 64 LRR

BO_ 2497508306 UUDT_Rsp_From_LRR_CAN_8_connec02: 8 LRR

BO_ 2497508562 UUDT_Rsp_From_LRR_CAN_8_connec03: 64 LRR

BO_ 2497508818 UUDT_Rsp_From_LRR_CAN_8_connec04: 64 LRR

BO_ 2497509074 UUDT_Rsp_From_LRR_CAN_8_connec05: 8 LRR

BO_ 2497507795 UUDT_Rsp_From_SRR_LF_CAN_8_conne: 64 SRR_LF

BO_ 2497508051 UUDT_Rsp_From_SRR_LF_CAN_8_con01: 64 SRR_LF

BO_ 2497508307 UUDT_Rsp_From_SRR_LF_CAN_8_con02: 8 SRR_LF

BO_ 2497508563 UUDT_Rsp_From_SRR_LF_CAN_8_con03: 64 SRR_LF

BO_ 2497508819 UUDT_Rsp_From_SRR_LF_CAN_8_con04: 64 SRR_LF

BO_ 2497509075 UUDT_Rsp_From_SRR_LF_CAN_8_con05: 8 SRR_LF

BO_ 2497507799 UUDT_Rsp_From_SRR_LR_CR_CAN_8_co: 64 SRR_LR_CR

BO_ 2497508055 UUDT_Rsp_From_SRR_LR_CR_CAN_8_01: 64 SRR_LR_CR

BO_ 2497508311 UUDT_Rsp_From_SRR_LR_CR_CAN_8_02: 8 SRR_LR_CR

BO_ 2497508567 UUDT_Rsp_From_SRR_LR_CR_CAN_8_03: 64 SRR_LR_CR

BO_ 2497508823 UUDT_Rsp_From_SRR_LR_CR_CAN_8_04: 64 SRR_LR_CR

BO_ 2497509079 UUDT_Rsp_From_SRR_LR_CR_CAN_8_05: 8 SRR_LR_CR

BO_ 2497507798 UUDT_Rsp_From_SRR_RF_CAN_8_conne: 64 SRR_RF

BO_ 2497508054 UUDT_Rsp_From_SRR_RF_CAN_8_con01: 64 SRR_RF

BO_ 2497508310 UUDT_Rsp_From_SRR_RF_CAN_8_con02: 8 SRR_RF

BO_ 2497508566 UUDT_Rsp_From_SRR_RF_CAN_8_con03: 64 SRR_RF

BO_ 2497508822 UUDT_Rsp_From_SRR_RF_CAN_8_con04: 64 SRR_RF

BO_ 2497509078 UUDT_Rsp_From_SRR_RF_CAN_8_con05: 8 SRR_RF

BO_ 2497507800 UUDT_Rsp_From_SRR_RR_CAN_8_conne: 64 SRR_RR

BO_ 2497508056 UUDT_Rsp_From_SRR_RR_CAN_8_con01: 64 SRR_RR

BO_ 2497508312 UUDT_Rsp_From_SRR_RR_CAN_8_con02: 8 SRR_RR

BO_ 2497508568 UUDT_Rsp_From_SRR_RR_CAN_8_con03: 64 SRR_RR

BO_ 2497508824 UUDT_Rsp_From_SRR_RR_CAN_8_con04: 64 SRR_RR

BO_ 2497509080 UUDT_Rsp_From_SRR_RR_CAN_8_con05: 8 SRR_RR

BO_ 2497507801 UUDT_Rsp_From_SRR_SLR_CAN_8_conn: 64 SRR_SLR

BO_ 2497508057 UUDT_Rsp_From_SRR_SLR_CAN_8_co01: 64 SRR_SLR

BO_ 2497508313 UUDT_Rsp_From_SRR_SLR_CAN_8_co02: 8 SRR_SLR

BO_ 2497508569 UUDT_Rsp_From_SRR_SLR_CAN_8_co03: 64 SRR_SLR

BO_ 2497508825 UUDT_Rsp_From_SRR_SLR_CAN_8_co04: 64 SRR_SLR

BO_ 2497509081 UUDT_Rsp_From_SRR_SLR_CAN_8_co05: 8 SRR_SLR

BO_ 2497507802 UUDT_Rsp_From_SRR_SRR_CAN_8_conn: 64 SRR_SRR

BO_ 2497508058 UUDT_Rsp_From_SRR_SRR_CAN_8_co01: 64 SRR_SRR

BO_ 2497508314 UUDT_Rsp_From_SRR_SRR_CAN_8_co02: 8 SRR_SRR

BO_ 2497508570 UUDT_Rsp_From_SRR_SRR_CAN_8_co03: 64 SRR_SRR

BO_ 2497508826 UUDT_Rsp_From_SRR_SRR_CAN_8_co04: 64 SRR_SRR

BO_ 2497509082 UUDT_Rsp_From_SRR_SRR_CAN_8_co05: 8 SRR_SRR

BO_ 1157 VehIdNmDig10_17_PDU: 8 CGM
 SG_ VehIdNmDig10_17 : 7|64@0+ (1,0) [0|18446744073709551615] "" HDLM

BO_ 1156 VehIdNmDig2_9_PDU: 8 CGM
 SG_ VehIdNmDig2_9 : 7|64@0+ (1,0) [0|18446744073709551615] "" HDLM

BO_ 570 VehMtnInfo1_PCSM_PDU: 8 CGM
 SG_ VehMtnInfo1_PCSM : 0|64@1+ (1,0) [0|1.84467e+019] "" FCM_LC

BO_ 135 VehMtnInfo1_Prtctd_PDU: 7 CGM
 SG_ VMI1P_MAC : 7|27@0+ (1,0) [0|1.34218e+008] "" FCM_LC
 SG_ VMI1P_FCnt : 28|5@0+ (1,0) [0|31] "" FCM_LC
 SG_ VMI1P_VehTopSpdLimArbdValAuth : 37|8@0+ (2,0) [0|510] "km / h" FCM_LC
 SG_ VMI1P_AccelPedOvrrdActvAuth : 38|1@0+ (1,0) [0|1] "" FCM_LC
 SG_ VMI1P_VehTopSpdLimModeActvAuth : 39|1@0+ (1,0) [0|1] "" FCM_LC
 SG_ VMI1P_AccelActlPstnAuth : 44|8@0+ (0.392157,0) [0|100] "%" FCM_LC,SRR_SLR,SRR_SRR
 SG_ VMI1P_AccelActlPstnAuth_Inv : 45|1@0+ (1,0) [0|1] "" FCM_LC
 SG_ VMI1P_ARC : 52|2@0+ (1,0) [0|3] "" FCM_LC

BO_ 1807 VehSpdAvgDrvn_PCSM_PDU: 8 CGM
 SG_ VehSpdAvgDrvn_PCSM : 0|64@1+ (1,0) [0|1.84467e+019] "" HDLM

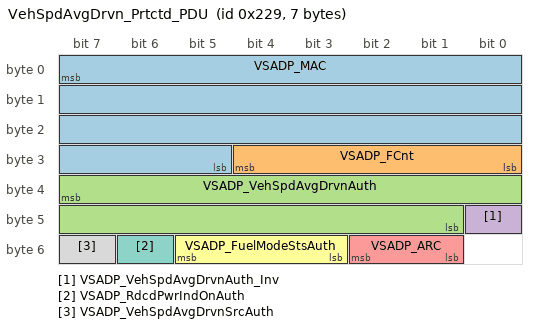
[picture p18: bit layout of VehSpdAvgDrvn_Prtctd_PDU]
BO_ 553 VehSpdAvgDrvn_Prtctd_PDU: 7 CGM
 SG_ VSADP_MAC : 7|27@0+ (1,0) [0|1.34218e+008] "" HDLM
 SG_ VSADP_FCnt : 28|5@0+ (1,0) [0|31] "" HDLM
 SG_ VSADP_VehSpdAvgDrvnAuth : 39|15@0+ (0.015625,0) [0|511.984] "km / h" EOCM_HCP2,FCM_LC,HDLM,LRR,LRR_HC,SRR_LF,SRR_LR_CR,SRR_RF,SRR_RR,SRR_SLR,SRR_SRR
 SG_ VSADP_VehSpdAvgDrvnAuth_Inv : 40|1@0+ (1,0) [0|1] "" FCM_LC,HDLM,SRR_SLR,SRR_SRR
 SG_ VSADP_ARC : 50|2@0+ (1,0) [0|3] "" HDLM
 SG_ VSADP_FuelModeStsAuth : 53|3@0+ (1,0) [0|4] "" HDLM
 SG_ VSADP_RdcdPwrIndOnAuth : 54|1@0+ (1,0) [0|1] "" HDLM
 SG_ VSADP_VehSpdAvgDrvnSrcAuth : 55|1@0+ (1,0) [0|1] "" HDLM

BA_DEF_ SG_  "SignalType" STRING ;
BA_DEF_ SG_  "SignalLongName" STRING ;
BA_DEF_ BO_  "GenMsgCycleTime" INT 0 10000;
BA_DEF_ BO_  "GenMsgSendType" ENUM "cyclicX","spontanX","cyclicIfActiveX","spontanWithDelay","cyclicAndSpontanX","cyclicAndSpontanWithDelay","spontanWithRepetition","cyclicIfActiveAndSpontanWD";
BA_DEF_ BO_  "VFrameFormat" ENUM  "StandardCAN","ExtendedCAN","reserved","reserved","reserved","reserved","reserved","reserved","reserved","reserved","reserved","reserved","reserved","reserved","StandardCAN_FD","ExtendedCAN_FD";
BA_DEF_DEF_  "SignalType" "";
BA_DEF_DEF_  "SignalLongName" "";
BA_DEF_DEF_  "GenMsgCycleTime" 0;
BA_DEF_DEF_  "GenMsgSendType" "cyclicX";
BA_DEF_DEF_  "VFrameFormat" "StandardCAN";
BA_ "GenMsgCycleTime" BO_ 1066 1000;
BA_ "VFrameFormat" BO_ 1066 14;
BA_ "GenMsgCycleTime" BO_ 1123 1000;
BA_ "VFrameFormat" BO_ 1123 14;
BA_ "GenMsgCycleTime" BO_ 1043 1000;
BA_ "VFrameFormat" BO_ 1043 14;
BA_ "GenMsgCycleTime" BO_ 1106 1000;
BA_ "VFrameFormat" BO_ 1106 14;
BA_ "GenMsgCycleTime" BO_ 1132 1000;
BA_ "VFrameFormat" BO_ 1132 14;
BA_ "GenMsgCycleTime" BO_ 1133 1000;
BA_ "VFrameFormat" BO_ 1133 14;
BA_ "GenMsgCycleTime" BO_ 1134 1000;
BA_ "VFrameFormat" BO_ 1134 14;
BA_ "GenMsgCycleTime" BO_ 1139 1000;
BA_ "VFrameFormat" BO_ 1139 14;
BA_ "GenMsgCycleTime" BO_ 1140 1000;
BA_ "VFrameFormat" BO_ 1140 14;
BA_ "GenMsgCycleTime" BO_ 1110 1000;
BA_ "VFrameFormat" BO_ 1110 14;
BA_ "GenMsgCycleTime" BO_ 1111 1000;
BA_ "VFrameFormat" BO_ 1111 14;
BA_ "GenMsgCycleTime" BO_ 1122 1000;
BA_ "VFrameFormat" BO_ 1122 14;
BA_ "GenMsgCycleTime" BO_ 178 50;
BA_ "VFrameFormat" BO_ 178 14;
BA_ "GenMsgCycleTime" BO_ 1108 1000;
BA_ "VFrameFormat" BO_ 1108 14;
BA_ "GenMsgCycleTime" BO_ 1029 500;
BA_ "VFrameFormat" BO_ 1029 14;
BA_ "GenMsgCycleTime" BO_ 1045 100;
BA_ "VFrameFormat" BO_ 1045 14;
BA_ "GenMsgCycleTime" BO_ 1124 1000;
BA_ "VFrameFormat" BO_ 1124 14;
BA_ "GenMsgCycleTime" BO_ 1126 1000;
BA_ "VFrameFormat" BO_ 1126 14;
BA_ "GenMsgCycleTime" BO_ 1129 1000;
BA_ "VFrameFormat" BO_ 1129 14;
BA_ "GenMsgCycleTime" BO_ 1131 1000;
BA_ "VFrameFormat" BO_ 1131 14;
BA_ "VFrameFormat" BO_ 1070 14;
BA_ "VFrameFormat" BO_ 17 14;
BA_ "GenMsgCycleTime" BO_ 518 100;
BA_ "VFrameFormat" BO_ 518 14;
BA_ "GenMsgCycleTime" BO_ 1128 1000;
BA_ "VFrameFormat" BO_ 1128 14;
BA_ "GenMsgCycleTime" BO_ 1119 1000;
BA_ "VFrameFormat" BO_ 1119 14;
BA_ "GenMsgCycleTime" BO_ 1120 1000;
BA_ "VFrameFormat" BO_ 1120 14;
BA_ "GenMsgCycleTime" BO_ 1060 1000;
BA_ "VFrameFormat" BO_ 1060 14;
BA_ "GenMsgCycleTime" BO_ 514 250;
BA_ "VFrameFormat" BO_ 514 14;
BA_ "VFrameFormat" BO_ 577 14;
BA_ "GenMsgCycleTime" BO_ 32 10;
BA_ "VFrameFormat" BO_ 32 14;
BA_ "VFrameFormat" BO_ 1082 14;
BA_ "VFrameFormat" BO_ 593 14;
BA_ "GenMsgCycleTime" BO_ 36 10;
BA_ "VFrameFormat" BO_ 36 14;
BA_ "GenMsgCycleTime" BO_ 1377 1000;
BA_ "VFrameFormat" BO_ 1377 14;
BA_ "GenMsgCycleTime" BO_ 1378 1000;
BA_ "VFrameFormat" BO_ 1378 14;
BA_ "GenMsgCycleTime" BO_ 1441 1000;
BA_ "VFrameFormat" BO_ 1441 14;
BA_ "VFrameFormat" BO_ 566 14;
BA_ "GenMsgCycleTime" BO_ 551 250;
BA_ "VFrameFormat" BO_ 551 14;
BA_ "GenMsgCycleTime" BO_ 1054 1000;
BA_ "VFrameFormat" BO_ 1054 14;
BA_ "GenMsgCycleTime" BO_ 140 30;
BA_ "VFrameFormat" BO_ 140 14;
BA_ "GenMsgCycleTime" BO_ 139 50;
BA_ "VFrameFormat" BO_ 139 14;
BA_ "GenMsgCycleTime" BO_ 1153 1000;
BA_ "VFrameFormat" BO_ 1153 14;
BA_ "GenMsgCycleTime" BO_ 1154 1000;
BA_ "VFrameFormat" BO_ 1154 14;
BA_ "GenMsgCycleTime" BO_ 613 100;
BA_ "VFrameFormat" BO_ 613 14;
BA_ "GenMsgCycleTime" BO_ 1136 1000;
BA_ "VFrameFormat" BO_ 1136 14;
BA_ "GenMsgCycleTime" BO_ 614 100;
BA_ "VFrameFormat" BO_ 614 14;
BA_ "GenMsgCycleTime" BO_ 1137 1000;
BA_ "VFrameFormat" BO_ 1137 14;
BA_ "GenMsgCycleTime" BO_ 1138 1000;
BA_ "VFrameFormat" BO_ 1138 14;
BA_ "VFrameFormat" BO_ 1097 14;
BA_ "VFrameFormat" BO_ 1796 14;
BA_ "GenMsgCycleTime" BO_ 1404 1000;
BA_ "VFrameFormat" BO_ 1404 14;
BA_ "VFrameFormat" BO_ 1098 14;
BA_ "VFrameFormat" BO_ 1099 14;
BA_ "VFrameFormat" BO_ 1799 14;
BA_ "GenMsgCycleTime" BO_ 1430 1000;
BA_ "VFrameFormat" BO_ 1430 14;
BA_ "VFrameFormat" BO_ 1100 14;
BA_ "VFrameFormat" BO_ 1804 14;
BA_ "GenMsgCycleTime" BO_ 1432 1000;
BA_ "VFrameFormat" BO_ 1432 14;
BA_ "VFrameFormat" BO_ 1290 14;
BA_ "VFrameFormat" BO_ 1806 14;
BA_ "GenMsgCycleTime" BO_ 1433 1000;
BA_ "VFrameFormat" BO_ 1433 14;
BA_ "VFrameFormat" BO_ 1291 14;
BA_ "GenMsgCycleTime" BO_ 1135 1000;
BA_ "VFrameFormat" BO_ 1135 14;
BA_ "GenMsgCycleTime" BO_ 1109 1000;
BA_ "VFrameFormat" BO_ 1109 14;
BA_ "GenMsgCycleTime" BO_ 1141 1000;
BA_ "VFrameFormat" BO_ 1141 14;
BA_ "GenMsgCycleTime" BO_ 1142 1000;
BA_ "VFrameFormat" BO_ 1142 14;
BA_ "GenMsgCycleTime" BO_ 1144 1000;
BA_ "VFrameFormat" BO_ 1144 14;
BA_ "GenMsgCycleTime" BO_ 1145 1000;
BA_ "VFrameFormat" BO_ 1145 14;
BA_ "GenMsgCycleTime" BO_ 1147 1000;
BA_ "VFrameFormat" BO_ 1147 14;
BA_ "GenMsgCycleTime" BO_ 1149 1000;
BA_ "VFrameFormat" BO_ 1149 14;
BA_ "GenMsgCycleTime" BO_ 1155 1000;
BA_ "VFrameFormat" BO_ 1155 14;
BA_ "GenMsgCycleTime" BO_ 1146 1000;
BA_ "VFrameFormat" BO_ 1146 14;
BA_ "GenMsgCycleTime" BO_ 1150 1000;
BA_ "VFrameFormat" BO_ 1150 14;
BA_ "GenMsgCycleTime" BO_ 1073 3500;
BA_ "VFrameFormat" BO_ 1073 14;
BA_ "GenMsgCycleTime" BO_ 1068 1000;
BA_ "VFrameFormat" BO_ 1068 14;
BA_ "GenMsgCycleTime" BO_ 1842 3500;
BA_ "VFrameFormat" BO_ 1842 14;
BA_ "GenMsgCycleTime" BO_ 1393 1000;
BA_ "VFrameFormat" BO_ 1393 14;
BA_ "GenMsgCycleTime" BO_ 522 1000;
BA_ "VFrameFormat" BO_ 522 14;
BA_ "GenMsgCycleTime" BO_ 644 250;
BA_ "VFrameFormat" BO_ 644 14;
BA_ "VFrameFormat" BO_ 568 14;
BA_ "GenMsgCycleTime" BO_ 49 12.5;
BA_ "VFrameFormat" BO_ 49 14;
BA_ "VFrameFormat" BO_ 1644 14;
BA_ "VFrameFormat" BO_ 1636 14;
BA_ "VFrameFormat" BO_ 1755 14;
BA_ "VFrameFormat" BO_ 1724 14;
BA_ "VFrameFormat" BO_ 1646 14;
BA_ "VFrameFormat" BO_ 1746 14;
BA_ "VFrameFormat" BO_ 1747 14;
BA_ "VFrameFormat" BO_ 1751 14;
BA_ "VFrameFormat" BO_ 1750 14;
BA_ "VFrameFormat" BO_ 1752 14;
BA_ "VFrameFormat" BO_ 1753 14;
BA_ "VFrameFormat" BO_ 1754 14;
BA_ "VFrameFormat" BO_ 2430336753 15;
BA_ "VFrameFormat" BO_ 2431385329 15;
BA_ "VFrameFormat" BO_ 2497342705 15;
BA_ "VFrameFormat" BO_ 2497340657 15;
BA_ "VFrameFormat" BO_ 2497371121 15;
BA_ "VFrameFormat" BO_ 2565827825 15;
BA_ "VFrameFormat" BO_ 2497363185 15;
BA_ "VFrameFormat" BO_ 2497343217 15;
BA_ "VFrameFormat" BO_ 2497368817 15;
BA_ "VFrameFormat" BO_ 2497369073 15;
BA_ "VFrameFormat" BO_ 2497370097 15;
BA_ "VFrameFormat" BO_ 2497369841 15;
BA_ "VFrameFormat" BO_ 2497370353 15;
BA_ "VFrameFormat" BO_ 2497370609 15;
BA_ "VFrameFormat" BO_ 2497370865 15;
BA_ "VFrameFormat" BO_ 2430336754 15;
BA_ "VFrameFormat" BO_ 2431385330 15;
BA_ "VFrameFormat" BO_ 2497342706 15;
BA_ "VFrameFormat" BO_ 2497340658 15;
BA_ "VFrameFormat" BO_ 2497371122 15;
BA_ "VFrameFormat" BO_ 2497363186 15;
BA_ "VFrameFormat" BO_ 2497368818 15;
BA_ "VFrameFormat" BO_ 2497369074 15;
BA_ "VFrameFormat" BO_ 2497370098 15;
BA_ "VFrameFormat" BO_ 2497369842 15;
BA_ "VFrameFormat" BO_ 2497370354 15;
BA_ "VFrameFormat" BO_ 2497370610 15;
BA_ "VFrameFormat" BO_ 2497370866 15;
BA_ "VFrameFormat" BO_ 2430336756 15;
BA_ "VFrameFormat" BO_ 2431385332 15;
BA_ "VFrameFormat" BO_ 2497342708 15;
BA_ "VFrameFormat" BO_ 2497340660 15;
BA_ "VFrameFormat" BO_ 2497371124 15;
BA_ "VFrameFormat" BO_ 2497363188 15;
BA_ "VFrameFormat" BO_ 2497343220 15;
BA_ "VFrameFormat" BO_ 2497368820 15;
BA_ "VFrameFormat" BO_ 2497369076 15;
BA_ "VFrameFormat" BO_ 2497370100 15;
BA_ "VFrameFormat" BO_ 2497369844 15;
BA_ "VFrameFormat" BO_ 2497370356 15;
BA_ "VFrameFormat" BO_ 2497370612 15;
BA_ "VFrameFormat" BO_ 2497370868 15;
BA_ "VFrameFormat" BO_ 2430336757 15;
BA_ "VFrameFormat" BO_ 2431385333 15;
BA_ "VFrameFormat" BO_ 2497342709 15;
BA_ "VFrameFormat" BO_ 2497340661 15;
BA_ "VFrameFormat" BO_ 2497371125 15;
BA_ "VFrameFormat" BO_ 2497363189 15;
BA_ "VFrameFormat" BO_ 2497343221 15;
BA_ "VFrameFormat" BO_ 2497368821 15;
BA_ "VFrameFormat" BO_ 2497369077 15;
BA_ "VFrameFormat" BO_ 2497370101 15;
BA_ "VFrameFormat" BO_ 2497369845 15;
BA_ "VFrameFormat" BO_ 2497370357 15;
BA_ "VFrameFormat" BO_ 2497370613 15;
BA_ "VFrameFormat" BO_ 2497370869 15;
BA_ "VFrameFormat" BO_ 2497379436 15;
BA_ "VFrameFormat" BO_ 2497379428 15;
BA_ "VFrameFormat" BO_ 2497379547 15;
BA_ "VFrameFormat" BO_ 2497379516 15;
BA_ "VFrameFormat" BO_ 2497379438 15;
BA_ "VFrameFormat" BO_ 2497379538 15;
BA_ "VFrameFormat" BO_ 2497379539 15;
BA_ "VFrameFormat" BO_ 2497379543 15;
BA_ "VFrameFormat" BO_ 2497379542 15;
BA_ "VFrameFormat" BO_ 2497379544 15;
BA_ "VFrameFormat" BO_ 2497379545 15;
BA_ "VFrameFormat" BO_ 2497379546 15;
BA_ "VFrameFormat" BO_ 2497376620 15;
BA_ "VFrameFormat" BO_ 2497376876 15;
BA_ "VFrameFormat" BO_ 2497377388 15;
BA_ "VFrameFormat" BO_ 2497377644 15;
BA_ "VFrameFormat" BO_ 2497376612 15;
BA_ "VFrameFormat" BO_ 2497376868 15;
BA_ "VFrameFormat" BO_ 2497377380 15;
BA_ "VFrameFormat" BO_ 2497377636 15;
BA_ "VFrameFormat" BO_ 2497376731 15;
BA_ "VFrameFormat" BO_ 2497376987 15;
BA_ "VFrameFormat" BO_ 2497377499 15;
BA_ "VFrameFormat" BO_ 2497377755 15;
BA_ "VFrameFormat" BO_ 2565861740 15;
BA_ "VFrameFormat" BO_ 2497376700 15;
BA_ "VFrameFormat" BO_ 2497376956 15;
BA_ "VFrameFormat" BO_ 2497377468 15;
BA_ "VFrameFormat" BO_ 2497377724 15;
BA_ "VFrameFormat" BO_ 2497376622 15;
BA_ "VFrameFormat" BO_ 2497377390 15;
BA_ "VFrameFormat" BO_ 2497377646 15;
BA_ "VFrameFormat" BO_ 2497376722 15;
BA_ "VFrameFormat" BO_ 2497376978 15;
BA_ "VFrameFormat" BO_ 2497377490 15;
BA_ "VFrameFormat" BO_ 2497377746 15;
BA_ "VFrameFormat" BO_ 2497376723 15;
BA_ "VFrameFormat" BO_ 2497376979 15;
BA_ "VFrameFormat" BO_ 2497377491 15;
BA_ "VFrameFormat" BO_ 2497377747 15;
BA_ "VFrameFormat" BO_ 2497376727 15;
BA_ "VFrameFormat" BO_ 2497376983 15;
BA_ "VFrameFormat" BO_ 2497377495 15;
BA_ "VFrameFormat" BO_ 2497377751 15;
BA_ "VFrameFormat" BO_ 2497376726 15;
BA_ "VFrameFormat" BO_ 2497376982 15;
BA_ "VFrameFormat" BO_ 2497377494 15;
BA_ "VFrameFormat" BO_ 2497377750 15;
BA_ "VFrameFormat" BO_ 2497376728 15;
BA_ "VFrameFormat" BO_ 2497376984 15;
BA_ "VFrameFormat" BO_ 2497377496 15;
BA_ "VFrameFormat" BO_ 2497377752 15;
BA_ "VFrameFormat" BO_ 2497376729 15;
BA_ "VFrameFormat" BO_ 2497376985 15;
BA_ "VFrameFormat" BO_ 2497377497 15;
BA_ "VFrameFormat" BO_ 2497377753 15;
BA_ "VFrameFormat" BO_ 2497376730 15;
BA_ "VFrameFormat" BO_ 2497376986 15;
BA_ "VFrameFormat" BO_ 2497377498 15;
BA_ "VFrameFormat" BO_ 2497377754 15;
BA_ "VFrameFormat" BO_ 2497507692 15;
BA_ "VFrameFormat" BO_ 2497507948 15;
BA_ "VFrameFormat" BO_ 2497508460 15;
BA_ "VFrameFormat" BO_ 2497508716 15;
BA_ "VFrameFormat" BO_ 2497507684 15;
BA_ "VFrameFormat" BO_ 2497507940 15;
BA_ "VFrameFormat" BO_ 2497508452 15;
BA_ "VFrameFormat" BO_ 2497508708 15;
BA_ "VFrameFormat" BO_ 2497507803 15;
BA_ "VFrameFormat" BO_ 2497508059 15;
BA_ "VFrameFormat" BO_ 2497508571 15;
BA_ "VFrameFormat" BO_ 2497508827 15;
BA_ "VFrameFormat" BO_ 2497507772 15;
BA_ "VFrameFormat" BO_ 2497508028 15;
BA_ "VFrameFormat" BO_ 2497508540 15;
BA_ "VFrameFormat" BO_ 2497508796 15;
BA_ "VFrameFormat" BO_ 2497507694 15;
BA_ "VFrameFormat" BO_ 2497507794 15;
BA_ "VFrameFormat" BO_ 2497508050 15;
BA_ "VFrameFormat" BO_ 2497508562 15;
BA_ "VFrameFormat" BO_ 2497508818 15;
BA_ "VFrameFormat" BO_ 2497507795 15;
BA_ "VFrameFormat" BO_ 2497508051 15;
BA_ "VFrameFormat" BO_ 2497508563 15;
BA_ "VFrameFormat" BO_ 2497508819 15;
BA_ "VFrameFormat" BO_ 2497507799 15;
BA_ "VFrameFormat" BO_ 2497508055 15;
BA_ "VFrameFormat" BO_ 2497508567 15;
BA_ "VFrameFormat" BO_ 2497508823 15;
BA_ "VFrameFormat" BO_ 2497507798 15;
BA_ "VFrameFormat" BO_ 2497508054 15;
BA_ "VFrameFormat" BO_ 2497508566 15;
BA_ "VFrameFormat" BO_ 2497508822 15;
BA_ "VFrameFormat" BO_ 2497507800 15;
BA_ "VFrameFormat" BO_ 2497508056 15;
BA_ "VFrameFormat" BO_ 2497508568 15;
BA_ "VFrameFormat" BO_ 2497508824 15;
BA_ "VFrameFormat" BO_ 2497507801 15;
BA_ "VFrameFormat" BO_ 2497508057 15;
BA_ "VFrameFormat" BO_ 2497508569 15;
BA_ "VFrameFormat" BO_ 2497508825 15;
BA_ "VFrameFormat" BO_ 2497507802 15;
BA_ "VFrameFormat" BO_ 2497508058 15;
BA_ "VFrameFormat" BO_ 2497508570 15;
BA_ "VFrameFormat" BO_ 2497508826 15;
BA_ "GenMsgCycleTime" BO_ 1157 1000;
BA_ "VFrameFormat" BO_ 1157 14;
BA_ "GenMsgCycleTime" BO_ 1156 1000;
BA_ "VFrameFormat" BO_ 1156 14;
BA_ "VFrameFormat" BO_ 570 14;
BA_ "GenMsgCycleTime" BO_ 135 25;
BA_ "VFrameFormat" BO_ 135 14;
BA_ "VFrameFormat" BO_ 1807 14;
BA_ "GenMsgCycleTime" BO_ 553 100;
BA_ "VFrameFormat" BO_ 553 14;
BA_ "SignalLongName" SG_ 1066 DTCI_EOCM_HCP2_DTCFailType "Diagnostic Trouble Code Information Extended - EOCM_HCP2 : Diagnostic Trouble Code Failure Type";
BA_ "SignalType" SG_ 1066 DTCI_EOCM_HCP2_CnfrmdDTC "ENM";
BA_ "SignalLongName" SG_ 1066 DTCI_EOCM_HCP2_CnfrmdDTC "Diagnostic Trouble Code Information Extended - EOCM_HCP2 : Confirmed DTC";
BA_ "SignalType" SG_ 1066 DTCI_EOCM_HCP2_DTCFaultType "ENM";
BA_ "SignalLongName" SG_ 1066 DTCI_EOCM_HCP2_DTCFaultType "Diagnostic Trouble Code Information Extended - EOCM_HCP2 : Diagnostic Trouble Code Fault Type";
BA_ "SignalLongName" SG_ 1066 DTCI_EOCM_HCP2_DTCNumber "Diagnostic Trouble Code Information Extended - EOCM_HCP2 : Diagnostic Trouble Code Number";
BA_ "SignalLongName" SG_ 1066 DTCI_EOCM_HCP2_DTCSource "Diagnostic Trouble Code Information Extended - EOCM_HCP2 : Diagnostic Trouble Code Source";
BA_ "SignalType" SG_ 1066 DTCI_EOCM_HCP2_TstNCmpltdOpCyc "ENM";
BA_ "SignalLongName" SG_ 1066 DTCI_EOCM_HCP2_TstNCmpltdOpCyc "Diagnostic Trouble Code Information Extended - EOCM_HCP2 : Test Not Completed This Operation Cycle";
BA_ "SignalType" SG_ 1066 DTCI_EOCM_HCP2_TstNCmpltdLstClr "ENM";
BA_ "SignalLongName" SG_ 1066 DTCI_EOCM_HCP2_TstNCmpltdLstClr "Diagnostic Trouble Code Information Extended - EOCM_HCP2 : Test Not Completed Since Last Clear";
BA_ "SignalType" SG_ 1066 DTCI_EOCM_HCP2_TstFldOpCyc "ENM";
BA_ "SignalLongName" SG_ 1066 DTCI_EOCM_HCP2_TstFldOpCyc "Diagnostic Trouble Code Information Extended - EOCM_HCP2 : Test Failed This Operation Cycle";
BA_ "SignalType" SG_ 1066 DTCI_EOCM_HCP2_TstFldLstClr "ENM";
BA_ "SignalLongName" SG_ 1066 DTCI_EOCM_HCP2_TstFldLstClr "Diagnostic Trouble Code Information Extended - EOCM_HCP2 : Test Failed Since Last Clear";
BA_ "SignalType" SG_ 1066 DTCI_EOCM_HCP2_TstFld "ENM";
BA_ "SignalLongName" SG_ 1066 DTCI_EOCM_HCP2_TstFld "Diagnostic Trouble Code Information Extended - EOCM_HCP2 : Test Failed";
BA_ "SignalType" SG_ 1066 DTCI_EOCM_HCP2_PndngDTC "ENM";
BA_ "SignalLongName" SG_ 1066 DTCI_EOCM_HCP2_PndngDTC "Diagnostic Trouble Code Information Extended - EOCM_HCP2 : Pending DTC";
BA_ "SignalType" SG_ 1066 DTCI_EOCM_HCP2_DTCTriggered "ENM";
BA_ "SignalLongName" SG_ 1066 DTCI_EOCM_HCP2_DTCTriggered "Diagnostic Trouble Code Information Extended - EOCM_HCP2 : Diagnostic Trouble Code Triggered";
BA_ "SignalType" SG_ 1066 DTCI_EOCM_HCP2_WrnIndTrggrd "ENM";
BA_ "SignalLongName" SG_ 1066 DTCI_EOCM_HCP2_WrnIndTrggrd "Diagnostic Trouble Code Information Extended - EOCM_HCP2 : Warning Indicator Triggered";
BA_ "SignalType" SG_ 1066 DTCI_EOCM_HCP2_WrnIndRqd "ENM";
BA_ "SignalLongName" SG_ 1066 DTCI_EOCM_HCP2_WrnIndRqd "Diagnostic Trouble Code Information Extended - EOCM_HCP2 : Warning Indicator Requested";
BA_ "SignalLongName" SG_ 1123 DTCI_FCM_LC_DTCFailType "Diagnostic Trouble Code Information Extended - FCM_LC : Diagnostic Trouble Code Failure Type";
BA_ "SignalType" SG_ 1123 DTCI_FCM_LC_CnfrmdDTC "ENM";
BA_ "SignalLongName" SG_ 1123 DTCI_FCM_LC_CnfrmdDTC "Diagnostic Trouble Code Information Extended - FCM_LC : Confirmed DTC";
BA_ "SignalType" SG_ 1123 DTCI_FCM_LC_DTCFaultType "ENM";
BA_ "SignalLongName" SG_ 1123 DTCI_FCM_LC_DTCFaultType "Diagnostic Trouble Code Information Extended - FCM_LC : Diagnostic Trouble Code Fault Type";
BA_ "SignalLongName" SG_ 1123 DTCI_FCM_LC_DTCNumber "Diagnostic Trouble Code Information Extended - FCM_LC : Diagnostic Trouble Code Number";
BA_ "SignalLongName" SG_ 1123 DTCI_FCM_LC_DTCSource "Diagnostic Trouble Code Information Extended - FCM_LC : Diagnostic Trouble Code Source";
BA_ "SignalType" SG_ 1123 DTCI_FCM_LC_TstNCmpltdOpCyc "ENM";
BA_ "SignalLongName" SG_ 1123 DTCI_FCM_LC_TstNCmpltdOpCyc "Diagnostic Trouble Code Information Extended - FCM_LC : Test Not Completed This Operation Cycle";
BA_ "SignalType" SG_ 1123 DTCI_FCM_LC_TstNCmpltdLstClr "ENM";
BA_ "SignalLongName" SG_ 1123 DTCI_FCM_LC_TstNCmpltdLstClr "Diagnostic Trouble Code Information Extended - FCM_LC : Test Not Completed Since Last Clear";
BA_ "SignalType" SG_ 1123 DTCI_FCM_LC_TstFldOpCyc "ENM";
BA_ "SignalLongName" SG_ 1123 DTCI_FCM_LC_TstFldOpCyc "Diagnostic Trouble Code Information Extended - FCM_LC : Test Failed This Operation Cycle";
BA_ "SignalType" SG_ 1123 DTCI_FCM_LC_TstFldLstClr "ENM";
BA_ "SignalLongName" SG_ 1123 DTCI_FCM_LC_TstFldLstClr "Diagnostic Trouble Code Information Extended - FCM_LC : Test Failed Since Last Clear";
BA_ "SignalType" SG_ 1123 DTCI_FCM_LC_TstFld "ENM";
BA_ "SignalLongName" SG_ 1123 DTCI_FCM_LC_TstFld "Diagnostic Trouble Code Information Extended - FCM_LC : Test Failed";
BA_ "SignalType" SG_ 1123 DTCI_FCM_LC_PndngDTC "ENM";
BA_ "SignalLongName" SG_ 1123 DTCI_FCM_LC_PndngDTC "Diagnostic Trouble Code Information Extended - FCM_LC : Pending DTC";
BA_ "SignalType" SG_ 1123 DTCI_FCM_LC_DTCTriggered "ENM";
BA_ "SignalLongName" SG_ 1123 DTCI_FCM_LC_DTCTriggered "Diagnostic Trouble Code Information Extended - FCM_LC : Diagnostic Trouble Code Triggered";
BA_ "SignalType" SG_ 1123 DTCI_FCM_LC_WrnIndTrggrd "ENM";
BA_ "SignalLongName" SG_ 1123 DTCI_FCM_LC_WrnIndTrggrd "Diagnostic Trouble Code Information Extended - FCM_LC : Warning Indicator Triggered";
BA_ "SignalType" SG_ 1123 DTCI_FCM_LC_WrnIndRqd "ENM";
BA_ "SignalLongName" SG_ 1123 DTCI_FCM_LC_WrnIndRqd "Diagnostic Trouble Code Information Extended - FCM_LC : Warning Indicator Requested";
BA_ "SignalLongName" SG_ 1043 DTCI_HDLM_DTCFailType "Diagnostic Trouble Code Information Extended - HDLM : Diagnostic Trouble Code Failure Type";
BA_ "SignalType" SG_ 1043 DTCI_HDLM_CnfrmdDTC "ENM";
BA_ "SignalLongName" SG_ 1043 DTCI_HDLM_CnfrmdDTC "Diagnostic Trouble Code Information Extended - HDLM : Confirmed DTC";
BA_ "SignalType" SG_ 1043 DTCI_HDLM_DTCFaultType "ENM";
BA_ "SignalLongName" SG_ 1043 DTCI_HDLM_DTCFaultType "Diagnostic Trouble Code Information Extended - HDLM : Diagnostic Trouble Code Fault Type";
BA_ "SignalLongName" SG_ 1043 DTCI_HDLM_DTCNumber "Diagnostic Trouble Code Information Extended - HDLM : Diagnostic Trouble Code Number";
BA_ "SignalLongName" SG_ 1043 DTCI_HDLM_DTCSource "Diagnostic Trouble Code Information Extended - HDLM : Diagnostic Trouble Code Source";
BA_ "SignalType" SG_ 1043 DTCI_HDLM_TstNCmpltdOpCyc "ENM";
BA_ "SignalLongName" SG_ 1043 DTCI_HDLM_TstNCmpltdOpCyc "Diagnostic Trouble Code Information Extended - HDLM : Test Not Completed This Operation Cycle";
BA_ "SignalType" SG_ 1043 DTCI_HDLM_TstNCmpltdLstClr "ENM";
BA_ "SignalLongName" SG_ 1043 DTCI_HDLM_TstNCmpltdLstClr "Diagnostic Trouble Code Information Extended - HDLM : Test Not Completed Since Last Clear";
BA_ "SignalType" SG_ 1043 DTCI_HDLM_TstFldOpCyc "ENM";
BA_ "SignalLongName" SG_ 1043 DTCI_HDLM_TstFldOpCyc "Diagnostic Trouble Code Information Extended - HDLM : Test Failed This Operation Cycle";
BA_ "SignalType" SG_ 1043 DTCI_HDLM_TstFldLstClr "ENM";
BA_ "SignalLongName" SG_ 1043 DTCI_HDLM_TstFldLstClr "Diagnostic Trouble Code Information Extended - HDLM : Test Failed Since Last Clear";
BA_ "SignalType" SG_ 1043 DTCI_HDLM_TstFld "ENM";
BA_ "SignalLongName" SG_ 1043 DTCI_HDLM_TstFld "Diagnostic Trouble Code Information Extended - HDLM : Test Failed";
BA_ "SignalType" SG_ 1043 DTCI_HDLM_PndngDTC "ENM";
BA_ "SignalLongName" SG_ 1043 DTCI_HDLM_PndngDTC "Diagnostic Trouble Code Information Extended - HDLM : Pending DTC";
BA_ "SignalType" SG_ 1043 DTCI_HDLM_DTCTriggered "ENM";
BA_ "SignalLongName" SG_ 1043 DTCI_HDLM_DTCTriggered "Diagnostic Trouble Code Information Extended - HDLM : Diagnostic Trouble Code Triggered";
BA_ "SignalType" SG_ 1043 DTCI_HDLM_WrnIndTrggrd "ENM";
BA_ "SignalLongName" SG_ 1043 DTCI_HDLM_WrnIndTrggrd "Diagnostic Trouble Code Information Extended - HDLM : Warning Indicator Triggered";
BA_ "SignalType" SG_ 1043 DTCI_HDLM_WrnIndRqd "ENM";
BA_ "SignalLongName" SG_ 1043 DTCI_HDLM_WrnIndRqd "Diagnostic Trouble Code Information Extended - HDLM : Warning Indicator Requested";
BA_ "SignalLongName" SG_ 1106 DTCI_LRR_HC_DTCFailType "Diagnostic Trouble Code Information Extended - LRR_HC : Diagnostic Trouble Code Failure Type";
BA_ "SignalType" SG_ 1106 DTCI_LRR_HC_CnfrmdDTC "ENM";
BA_ "SignalLongName" SG_ 1106 DTCI_LRR_HC_CnfrmdDTC "Diagnostic Trouble Code Information Extended - LRR_HC : Confirmed DTC";
BA_ "SignalType" SG_ 1106 DTCI_LRR_HC_DTCFaultType "ENM";
BA_ "SignalLongName" SG_ 1106 DTCI_LRR_HC_DTCFaultType "Diagnostic Trouble Code Information Extended - LRR_HC : Diagnostic Trouble Code Fault Type";
BA_ "SignalLongName" SG_ 1106 DTCI_LRR_HC_DTCNumber "Diagnostic Trouble Code Information Extended - LRR_HC : Diagnostic Trouble Code Number";
BA_ "SignalLongName" SG_ 1106 DTCI_LRR_HC_DTCSource "Diagnostic Trouble Code Information Extended - LRR_HC : Diagnostic Trouble Code Source";
BA_ "SignalType" SG_ 1106 DTCI_LRR_HC_TstNCmpltdOpCyc "ENM";
BA_ "SignalLongName" SG_ 1106 DTCI_LRR_HC_TstNCmpltdOpCyc "Diagnostic Trouble Code Information Extended - LRR_HC : Test Not Completed This Operation Cycle";
BA_ "SignalType" SG_ 1106 DTCI_LRR_HC_TstNCmpltdLstClr "ENM";
BA_ "SignalLongName" SG_ 1106 DTCI_LRR_HC_TstNCmpltdLstClr "Diagnostic Trouble Code Information Extended - LRR_HC : Test Not Completed Since Last Clear";
BA_ "SignalType" SG_ 1106 DTCI_LRR_HC_TstFldOpCyc "ENM";
BA_ "SignalLongName" SG_ 1106 DTCI_LRR_HC_TstFldOpCyc "Diagnostic Trouble Code Information Extended - LRR_HC : Test Failed This Operation Cycle";
BA_ "SignalType" SG_ 1106 DTCI_LRR_HC_TstFldLstClr "ENM";
BA_ "SignalLongName" SG_ 1106 DTCI_LRR_HC_TstFldLstClr "Diagnostic Trouble Code Information Extended - LRR_HC : Test Failed Since Last Clear";
BA_ "SignalType" SG_ 1106 DTCI_LRR_HC_TstFld "ENM";
BA_ "SignalLongName" SG_ 1106 DTCI_LRR_HC_TstFld "Diagnostic Trouble Code Information Extended - LRR_HC : Test Failed";
BA_ "SignalType" SG_ 1106 DTCI_LRR_HC_PndngDTC "ENM";
BA_ "SignalLongName" SG_ 1106 DTCI_LRR_HC_PndngDTC "Diagnostic Trouble Code Information Extended - LRR_HC : Pending DTC";
BA_ "SignalType" SG_ 1106 DTCI_LRR_HC_DTCTriggered "ENM";
BA_ "SignalLongName" SG_ 1106 DTCI_LRR_HC_DTCTriggered "Diagnostic Trouble Code Information Extended - LRR_HC : Diagnostic Trouble Code Triggered";
BA_ "SignalType" SG_ 1106 DTCI_LRR_HC_WrnIndTrggrd "ENM";
BA_ "SignalLongName" SG_ 1106 DTCI_LRR_HC_WrnIndTrggrd "Diagnostic Trouble Code Information Extended - LRR_HC : Warning Indicator Triggered";
BA_ "SignalType" SG_ 1106 DTCI_LRR_HC_WrnIndRqd "ENM";
BA_ "SignalLongName" SG_ 1106 DTCI_LRR_HC_WrnIndRqd "Diagnostic Trouble Code Information Extended - LRR_HC : Warning Indicator Requested";
BA_ "SignalLongName" SG_ 1132 DTCI_LRR_DTCFailType "Diagnostic Trouble Code Information Extended - LRR : Diagnostic Trouble Code Failure Type";
BA_ "SignalType" SG_ 1132 DTCI_LRR_CnfrmdDTC "ENM";
BA_ "SignalLongName" SG_ 1132 DTCI_LRR_CnfrmdDTC "Diagnostic Trouble Code Information Extended - LRR : Confirmed DTC";
BA_ "SignalType" SG_ 1132 DTCI_LRR_DTCFaultType "ENM";
BA_ "SignalLongName" SG_ 1132 DTCI_LRR_DTCFaultType "Diagnostic Trouble Code Information Extended - LRR : Diagnostic Trouble Code Fault Type";
BA_ "SignalLongName" SG_ 1132 DTCI_LRR_DTCNumber "Diagnostic Trouble Code Information Extended - LRR : Diagnostic Trouble Code Number";
BA_ "SignalLongName" SG_ 1132 DTCI_LRR_DTCSource "Diagnostic Trouble Code Information Extended - LRR : Diagnostic Trouble Code Source";
BA_ "SignalType" SG_ 1132 DTCI_LRR_TstNCmpltdOpCyc "ENM";
BA_ "SignalLongName" SG_ 1132 DTCI_LRR_TstNCmpltdOpCyc "Diagnostic Trouble Code Information Extended - LRR : Test Not Completed This Operation Cycle";
BA_ "SignalType" SG_ 1132 DTCI_LRR_TstNCmpltdLstClr "ENM";
BA_ "SignalLongName" SG_ 1132 DTCI_LRR_TstNCmpltdLstClr "Diagnostic Trouble Code Information Extended - LRR : Test Not Completed Since Last Clear";
BA_ "SignalType" SG_ 1132 DTCI_LRR_TstFldOpCyc "ENM";
BA_ "SignalLongName" SG_ 1132 DTCI_LRR_TstFldOpCyc "Diagnostic Trouble Code Information Extended - LRR : Test Failed This Operation Cycle";
BA_ "SignalType" SG_ 1132 DTCI_LRR_TstFldLstClr "ENM";
BA_ "SignalLongName" SG_ 1132 DTCI_LRR_TstFldLstClr "Diagnostic Trouble Code Information Extended - LRR : Test Failed Since Last Clear";
BA_ "SignalType" SG_ 1132 DTCI_LRR_TstFld "ENM";
BA_ "SignalLongName" SG_ 1132 DTCI_LRR_TstFld "Diagnostic Trouble Code Information Extended - LRR : Test Failed";
BA_ "SignalType" SG_ 1132 DTCI_LRR_PndngDTC "ENM";
BA_ "SignalLongName" SG_ 1132 DTCI_LRR_PndngDTC "Diagnostic Trouble Code Information Extended - LRR : Pending DTC";
BA_ "SignalType" SG_ 1132 DTCI_LRR_DTCTriggered "ENM";
BA_ "SignalLongName" SG_ 1132 DTCI_LRR_DTCTriggered "Diagnostic Trouble Code Information Extended - LRR : Diagnostic Trouble Code Triggered";
BA_ "SignalType" SG_ 1132 DTCI_LRR_WrnIndTrggrd "ENM";
BA_ "SignalLongName" SG_ 1132 DTCI_LRR_WrnIndTrggrd "Diagnostic Trouble Code Information Extended - LRR : Warning Indicator Triggered";
BA_ "SignalType" SG_ 1132 DTCI_LRR_WrnIndRqd "ENM";
BA_ "SignalLongName" SG_ 1132 DTCI_LRR_WrnIndRqd "Diagnostic Trouble Code Information Extended - LRR : Warning Indicator Requested";
BA_ "SignalLongName" SG_ 1133 DTCI_SRR_LF_DTCFailType "Diagnostic Trouble Code Information Extended - SRR_LF : Diagnostic Trouble Code Failure Type";
BA_ "SignalType" SG_ 1133 DTCI_SRR_LF_CnfrmdDTC "ENM";
BA_ "SignalLongName" SG_ 1133 DTCI_SRR_LF_CnfrmdDTC "Diagnostic Trouble Code Information Extended - SRR_LF : Confirmed DTC";
BA_ "SignalType" SG_ 1133 DTCI_SRR_LF_DTCFaultType "ENM";
BA_ "SignalLongName" SG_ 1133 DTCI_SRR_LF_DTCFaultType "Diagnostic Trouble Code Information Extended - SRR_LF : Diagnostic Trouble Code Fault Type";
BA_ "SignalLongName" SG_ 1133 DTCI_SRR_LF_DTCNumber "Diagnostic Trouble Code Information Extended - SRR_LF : Diagnostic Trouble Code Number";
BA_ "SignalLongName" SG_ 1133 DTCI_SRR_LF_DTCSource "Diagnostic Trouble Code Information Extended - SRR_LF : Diagnostic Trouble Code Source";
BA_ "SignalType" SG_ 1133 DTCI_SRR_LF_TstNCmpltdOpCyc "ENM";
BA_ "SignalLongName" SG_ 1133 DTCI_SRR_LF_TstNCmpltdOpCyc "Diagnostic Trouble Code Information Extended - SRR_LF : Test Not Completed This Operation Cycle";
BA_ "SignalType" SG_ 1133 DTCI_SRR_LF_TstNCmpltdLstClr "ENM";
BA_ "SignalLongName" SG_ 1133 DTCI_SRR_LF_TstNCmpltdLstClr "Diagnostic Trouble Code Information Extended - SRR_LF : Test Not Completed Since Last Clear";
BA_ "SignalType" SG_ 1133 DTCI_SRR_LF_TstFldOpCyc "ENM";
BA_ "SignalLongName" SG_ 1133 DTCI_SRR_LF_TstFldOpCyc "Diagnostic Trouble Code Information Extended - SRR_LF : Test Failed This Operation Cycle";
BA_ "SignalType" SG_ 1133 DTCI_SRR_LF_TstFldLstClr "ENM";
BA_ "SignalLongName" SG_ 1133 DTCI_SRR_LF_TstFldLstClr "Diagnostic Trouble Code Information Extended - SRR_LF : Test Failed Since Last Clear";
BA_ "SignalType" SG_ 1133 DTCI_SRR_LF_TstFld "ENM";
BA_ "SignalLongName" SG_ 1133 DTCI_SRR_LF_TstFld "Diagnostic Trouble Code Information Extended - SRR_LF : Test Failed";
BA_ "SignalType" SG_ 1133 DTCI_SRR_LF_PndngDTC "ENM";
BA_ "SignalLongName" SG_ 1133 DTCI_SRR_LF_PndngDTC "Diagnostic Trouble Code Information Extended - SRR_LF : Pending DTC";
BA_ "SignalType" SG_ 1133 DTCI_SRR_LF_DTCTriggered "ENM";
BA_ "SignalLongName" SG_ 1133 DTCI_SRR_LF_DTCTriggered "Diagnostic Trouble Code Information Extended - SRR_LF : Diagnostic Trouble Code Triggered";
BA_ "SignalType" SG_ 1133 DTCI_SRR_LF_WrnIndTrggrd "ENM";
BA_ "SignalLongName" SG_ 1133 DTCI_SRR_LF_WrnIndTrggrd "Diagnostic Trouble Code Information Extended - SRR_LF : Warning Indicator Triggered";
BA_ "SignalType" SG_ 1133 DTCI_SRR_LF_WrnIndRqd "ENM";
BA_ "SignalLongName" SG_ 1133 DTCI_SRR_LF_WrnIndRqd "Diagnostic Trouble Code Information Extended - SRR_LF : Warning Indicator Requested";
BA_ "SignalLongName" SG_ 1134 DTCI_SRR_LR_CR_DTCFailType "Diagnostic Trouble Code Information Extended - SRR_LR_CR : Diagnostic Trouble Code Failure Type";
BA_ "SignalType" SG_ 1134 DTCI_SRR_LR_CR_CnfrmdDTC "ENM";
BA_ "SignalLongName" SG_ 1134 DTCI_SRR_LR_CR_CnfrmdDTC "Diagnostic Trouble Code Information Extended - SRR_LR_CR : Confirmed DTC";
BA_ "SignalType" SG_ 1134 DTCI_SRR_LR_CR_DTCFaultType "ENM";
BA_ "SignalLongName" SG_ 1134 DTCI_SRR_LR_CR_DTCFaultType "Diagnostic Trouble Code Information Extended - SRR_LR_CR : Diagnostic Trouble Code Fault Type";
BA_ "SignalLongName" SG_ 1134 DTCI_SRR_LR_CR_DTCNumber "Diagnostic Trouble Code Information Extended - SRR_LR_CR : Diagnostic Trouble Code Number";
BA_ "SignalLongName" SG_ 1134 DTCI_SRR_LR_CR_DTCSource "Diagnostic Trouble Code Information Extended - SRR_LR_CR : Diagnostic Trouble Code Source";
BA_ "SignalType" SG_ 1134 DTCI_SRR_LR_CR_TstNCmpltdOpCyc "ENM";
BA_ "SignalLongName" SG_ 1134 DTCI_SRR_LR_CR_TstNCmpltdOpCyc "Diagnostic Trouble Code Information Extended - SRR_LR_CR : Test Not Completed This Operation Cycle";
BA_ "SignalType" SG_ 1134 DTCI_SRR_LR_CR_TstNCmpltdLstClr "ENM";
BA_ "SignalLongName" SG_ 1134 DTCI_SRR_LR_CR_TstNCmpltdLstClr "Diagnostic Trouble Code Information Extended - SRR_LR_CR : Test Not Completed Since Last Clear";
BA_ "SignalType" SG_ 1134 DTCI_SRR_LR_CR_TstFldOpCyc "ENM";
BA_ "SignalLongName" SG_ 1134 DTCI_SRR_LR_CR_TstFldOpCyc "Diagnostic Trouble Code Information Extended - SRR_LR_CR : Test Failed This Operation Cycle";
BA_ "SignalType" SG_ 1134 DTCI_SRR_LR_CR_TstFldLstClr "ENM";
BA_ "SignalLongName" SG_ 1134 DTCI_SRR_LR_CR_TstFldLstClr "Diagnostic Trouble Code Information Extended - SRR_LR_CR : Test Failed Since Last Clear";
BA_ "SignalType" SG_ 1134 DTCI_SRR_LR_CR_TstFld "ENM";
BA_ "SignalLongName" SG_ 1134 DTCI_SRR_LR_CR_TstFld "Diagnostic Trouble Code Information Extended - SRR_LR_CR : Test Failed";
BA_ "SignalType" SG_ 1134 DTCI_SRR_LR_CR_PndngDTC "ENM";
BA_ "SignalLongName" SG_ 1134 DTCI_SRR_LR_CR_PndngDTC "Diagnostic Trouble Code Information Extended - SRR_LR_CR : Pending DTC";
BA_ "SignalType" SG_ 1134 DTCI_SRR_LR_CR_DTCTriggered "ENM";
BA_ "SignalLongName" SG_ 1134 DTCI_SRR_LR_CR_DTCTriggered "Diagnostic Trouble Code Information Extended - SRR_LR_CR : Diagnostic Trouble Code Triggered";
BA_ "SignalType" SG_ 1134 DTCI_SRR_LR_CR_WrnIndTrggrd "ENM";
BA_ "SignalLongName" SG_ 1134 DTCI_SRR_LR_CR_WrnIndTrggrd "Diagnostic Trouble Code Information Extended - SRR_LR_CR : Warning Indicator Triggered";
BA_ "SignalType" SG_ 1134 DTCI_SRR_LR_CR_WrnIndRqd "ENM";
BA_ "SignalLongName" SG_ 1134 DTCI_SRR_LR_CR_WrnIndRqd "Diagnostic Trouble Code Information Extended - SRR_LR_CR : Warning Indicator Requested";
BA_ "SignalLongName" SG_ 1139 DTCI_SRR_RF_DTCFailType "Diagnostic Trouble Code Information Extended - SRR_RF : Diagnostic Trouble Code Failure Type";
BA_ "SignalType" SG_ 1139 DTCI_SRR_RF_CnfrmdDTC "ENM";
BA_ "SignalLongName" SG_ 1139 DTCI_SRR_RF_CnfrmdDTC "Diagnostic Trouble Code Information Extended - SRR_RF : Confirmed DTC";
BA_ "SignalType" SG_ 1139 DTCI_SRR_RF_DTCFaultType "ENM";
BA_ "SignalLongName" SG_ 1139 DTCI_SRR_RF_DTCFaultType "Diagnostic Trouble Code Information Extended - SRR_RF : Diagnostic Trouble Code Fault Type";
BA_ "SignalLongName" SG_ 1139 DTCI_SRR_RF_DTCNumber "Diagnostic Trouble Code Information Extended - SRR_RF : Diagnostic Trouble Code Number";
BA_ "SignalLongName" SG_ 1139 DTCI_SRR_RF_DTCSource "Diagnostic Trouble Code Information Extended - SRR_RF : Diagnostic Trouble Code Source";
BA_ "SignalType" SG_ 1139 DTCI_SRR_RF_TstNCmpltdOpCyc "ENM";
BA_ "SignalLongName" SG_ 1139 DTCI_SRR_RF_TstNCmpltdOpCyc "Diagnostic Trouble Code Information Extended - SRR_RF : Test Not Completed This Operation Cycle";
BA_ "SignalType" SG_ 1139 DTCI_SRR_RF_TstNCmpltdLstClr "ENM";
BA_ "SignalLongName" SG_ 1139 DTCI_SRR_RF_TstNCmpltdLstClr "Diagnostic Trouble Code Information Extended - SRR_RF : Test Not Completed Since Last Clear";
BA_ "SignalType" SG_ 1139 DTCI_SRR_RF_TstFldOpCyc "ENM";
BA_ "SignalLongName" SG_ 1139 DTCI_SRR_RF_TstFldOpCyc "Diagnostic Trouble Code Information Extended - SRR_RF : Test Failed This Operation Cycle";
BA_ "SignalType" SG_ 1139 DTCI_SRR_RF_TstFldLstClr "ENM";
BA_ "SignalLongName" SG_ 1139 DTCI_SRR_RF_TstFldLstClr "Diagnostic Trouble Code Information Extended - SRR_RF : Test Failed Since Last Clear";
BA_ "SignalType" SG_ 1139 DTCI_SRR_RF_TstFld "ENM";
BA_ "SignalLongName" SG_ 1139 DTCI_SRR_RF_TstFld "Diagnostic Trouble Code Information Extended - SRR_RF : Test Failed";
BA_ "SignalType" SG_ 1139 DTCI_SRR_RF_PndngDTC "ENM";
BA_ "SignalLongName" SG_ 1139 DTCI_SRR_RF_PndngDTC "Diagnostic Trouble Code Information Extended - SRR_RF : Pending DTC";
BA_ "SignalType" SG_ 1139 DTCI_SRR_RF_DTCTriggered "ENM";
BA_ "SignalLongName" SG_ 1139 DTCI_SRR_RF_DTCTriggered "Diagnostic Trouble Code Information Extended - SRR_RF : Diagnostic Trouble Code Triggered";
BA_ "SignalType" SG_ 1139 DTCI_SRR_RF_WrnIndTrggrd "ENM";
BA_ "SignalLongName" SG_ 1139 DTCI_SRR_RF_WrnIndTrggrd "Diagnostic Trouble Code Information Extended - SRR_RF : Warning Indicator Triggered";
BA_ "SignalType" SG_ 1139 DTCI_SRR_RF_WrnIndRqd "ENM";
BA_ "SignalLongName" SG_ 1139 DTCI_SRR_RF_WrnIndRqd "Diagnostic Trouble Code Information Extended - SRR_RF : Warning Indicator Requested";
BA_ "SignalLongName" SG_ 1140 DTCI_SRR_RR_DTCFailType "Diagnostic Trouble Code Information Extended - SRR_RR : Diagnostic Trouble Code Failure Type";
BA_ "SignalType" SG_ 1140 DTCI_SRR_RR_CnfrmdDTC "ENM";
BA_ "SignalLongName" SG_ 1140 DTCI_SRR_RR_CnfrmdDTC "Diagnostic Trouble Code Information Extended - SRR_RR : Confirmed DTC";
BA_ "SignalType" SG_ 1140 DTCI_SRR_RR_DTCFaultType "ENM";
BA_ "SignalLongName" SG_ 1140 DTCI_SRR_RR_DTCFaultType "Diagnostic Trouble Code Information Extended - SRR_RR : Diagnostic Trouble Code Fault Type";
BA_ "SignalLongName" SG_ 1140 DTCI_SRR_RR_DTCNumber "Diagnostic Trouble Code Information Extended - SRR_RR : Diagnostic Trouble Code Number";
BA_ "SignalLongName" SG_ 1140 DTCI_SRR_RR_DTCSource "Diagnostic Trouble Code Information Extended - SRR_RR : Diagnostic Trouble Code Source";
BA_ "SignalType" SG_ 1140 DTCI_SRR_RR_TstNCmpltdOpCyc "ENM";
BA_ "SignalLongName" SG_ 1140 DTCI_SRR_RR_TstNCmpltdOpCyc "Diagnostic Trouble Code Information Extended - SRR_RR : Test Not Completed This Operation Cycle";
BA_ "SignalType" SG_ 1140 DTCI_SRR_RR_TstNCmpltdLstClr "ENM";
BA_ "SignalLongName" SG_ 1140 DTCI_SRR_RR_TstNCmpltdLstClr "Diagnostic Trouble Code Information Extended - SRR_RR : Test Not Completed Since Last Clear";
BA_ "SignalType" SG_ 1140 DTCI_SRR_RR_TstFldOpCyc "ENM";
BA_ "SignalLongName" SG_ 1140 DTCI_SRR_RR_TstFldOpCyc "Diagnostic Trouble Code Information Extended - SRR_RR : Test Failed This Operation Cycle";
BA_ "SignalType" SG_ 1140 DTCI_SRR_RR_TstFldLstClr "ENM";
BA_ "SignalLongName" SG_ 1140 DTCI_SRR_RR_TstFldLstClr "Diagnostic Trouble Code Information Extended - SRR_RR : Test Failed Since Last Clear";
BA_ "SignalType" SG_ 1140 DTCI_SRR_RR_TstFld "ENM";
BA_ "SignalLongName" SG_ 1140 DTCI_SRR_RR_TstFld "Diagnostic Trouble Code Information Extended - SRR_RR : Test Failed";
BA_ "SignalType" SG_ 1140 DTCI_SRR_RR_PndngDTC "ENM";
BA_ "SignalLongName" SG_ 1140 DTCI_SRR_RR_PndngDTC "Diagnostic Trouble Code Information Extended - SRR_RR : Pending DTC";
BA_ "SignalType" SG_ 1140 DTCI_SRR_RR_DTCTriggered "ENM";
BA_ "SignalLongName" SG_ 1140 DTCI_SRR_RR_DTCTriggered "Diagnostic Trouble Code Information Extended - SRR_RR : Diagnostic Trouble Code Triggered";
BA_ "SignalType" SG_ 1140 DTCI_SRR_RR_WrnIndTrggrd "ENM";
BA_ "SignalLongName" SG_ 1140 DTCI_SRR_RR_WrnIndTrggrd "Diagnostic Trouble Code Information Extended - SRR_RR : Warning Indicator Triggered";
BA_ "SignalType" SG_ 1140 DTCI_SRR_RR_WrnIndRqd "ENM";
BA_ "SignalLongName" SG_ 1140 DTCI_SRR_RR_WrnIndRqd "Diagnostic Trouble Code Information Extended - SRR_RR : Warning Indicator Requested";
BA_ "SignalLongName" SG_ 1110 DTCI_SRR_SLR_DTCFailType "Diagnostic Trouble Code Information Extended - SRR_SLR : Diagnostic Trouble Code Failure Type";
BA_ "SignalType" SG_ 1110 DTCI_SRR_SLR_CnfrmdDTC "ENM";
BA_ "SignalLongName" SG_ 1110 DTCI_SRR_SLR_CnfrmdDTC "Diagnostic Trouble Code Information Extended - SRR_SLR : Confirmed DTC";
BA_ "SignalType" SG_ 1110 DTCI_SRR_SLR_DTCFaultType "ENM";
BA_ "SignalLongName" SG_ 1110 DTCI_SRR_SLR_DTCFaultType "Diagnostic Trouble Code Information Extended - SRR_SLR : Diagnostic Trouble Code Fault Type";
BA_ "SignalLongName" SG_ 1110 DTCI_SRR_SLR_DTCNumber "Diagnostic Trouble Code Information Extended - SRR_SLR : Diagnostic Trouble Code Number";
BA_ "SignalLongName" SG_ 1110 DTCI_SRR_SLR_DTCSource "Diagnostic Trouble Code Information Extended - SRR_SLR : Diagnostic Trouble Code Source";
BA_ "SignalType" SG_ 1110 DTCI_SRR_SLR_TstNCmpltdOpCyc "ENM";
BA_ "SignalLongName" SG_ 1110 DTCI_SRR_SLR_TstNCmpltdOpCyc "Diagnostic Trouble Code Information Extended - SRR_SLR : Test Not Completed This Operation Cycle";
BA_ "SignalType" SG_ 1110 DTCI_SRR_SLR_TstNCmpltdLstClr "ENM";
BA_ "SignalLongName" SG_ 1110 DTCI_SRR_SLR_TstNCmpltdLstClr "Diagnostic Trouble Code Information Extended - SRR_SLR : Test Not Completed Since Last Clear";
BA_ "SignalType" SG_ 1110 DTCI_SRR_SLR_TstFldOpCyc "ENM";
BA_ "SignalLongName" SG_ 1110 DTCI_SRR_SLR_TstFldOpCyc "Diagnostic Trouble Code Information Extended - SRR_SLR : Test Failed This Operation Cycle";
BA_ "SignalType" SG_ 1110 DTCI_SRR_SLR_TstFldLstClr "ENM";
BA_ "SignalLongName" SG_ 1110 DTCI_SRR_SLR_TstFldLstClr "Diagnostic Trouble Code Information Extended - SRR_SLR : Test Failed Since Last Clear";
BA_ "SignalType" SG_ 1110 DTCI_SRR_SLR_TstFld "ENM";
BA_ "SignalLongName" SG_ 1110 DTCI_SRR_SLR_TstFld "Diagnostic Trouble Code Information Extended - SRR_SLR : Test Failed";
BA_ "SignalType" SG_ 1110 DTCI_SRR_SLR_PndngDTC "ENM";
BA_ "SignalLongName" SG_ 1110 DTCI_SRR_SLR_PndngDTC "Diagnostic Trouble Code Information Extended - SRR_SLR : Pending DTC";
BA_ "SignalType" SG_ 1110 DTCI_SRR_SLR_DTCTriggered "ENM";
BA_ "SignalLongName" SG_ 1110 DTCI_SRR_SLR_DTCTriggered "Diagnostic Trouble Code Information Extended - SRR_SLR : Diagnostic Trouble Code Triggered";
BA_ "SignalType" SG_ 1110 DTCI_SRR_SLR_WrnIndTrggrd "ENM";
BA_ "SignalLongName" SG_ 1110 DTCI_SRR_SLR_WrnIndTrggrd "Diagnostic Trouble Code Information Extended - SRR_SLR : Warning Indicator Triggered";
BA_ "SignalType" SG_ 1110 DTCI_SRR_SLR_WrnIndRqd "ENM";
BA_ "SignalLongName" SG_ 1110 DTCI_SRR_SLR_WrnIndRqd "Diagnostic Trouble Code Information Extended - SRR_SLR : Warning Indicator Requested";
BA_ "SignalLongName" SG_ 1111 DTCI_SRR_SRR_DTCFailType "Diagnostic Trouble Code Information Extended - SRR_SRR : Diagnostic Trouble Code Failure Type";
BA_ "SignalType" SG_ 1111 DTCI_SRR_SRR_CnfrmdDTC "ENM";
BA_ "SignalLongName" SG_ 1111 DTCI_SRR_SRR_CnfrmdDTC "Diagnostic Trouble Code Information Extended - SRR_SRR : Confirmed DTC";
BA_ "SignalType" SG_ 1111 DTCI_SRR_SRR_DTCFaultType "ENM";
BA_ "SignalLongName" SG_ 1111 DTCI_SRR_SRR_DTCFaultType "Diagnostic Trouble Code Information Extended - SRR_SRR : Diagnostic Trouble Code Fault Type";
BA_ "SignalLongName" SG_ 1111 DTCI_SRR_SRR_DTCNumber "Diagnostic Trouble Code Information Extended - SRR_SRR : Diagnostic Trouble Code Number";
BA_ "SignalLongName" SG_ 1111 DTCI_SRR_SRR_DTCSource "Diagnostic Trouble Code Information Extended - SRR_SRR : Diagnostic Trouble Code Source";
BA_ "SignalType" SG_ 1111 DTCI_SRR_SRR_TstNCmpltdOpCyc "ENM";
BA_ "SignalLongName" SG_ 1111 DTCI_SRR_SRR_TstNCmpltdOpCyc "Diagnostic Trouble Code Information Extended - SRR_SRR : Test Not Completed This Operation Cycle";
BA_ "SignalType" SG_ 1111 DTCI_SRR_SRR_TstNCmpltdLstClr "ENM";
BA_ "SignalLongName" SG_ 1111 DTCI_SRR_SRR_TstNCmpltdLstClr "Diagnostic Trouble Code Information Extended - SRR_SRR : Test Not Completed Since Last Clear";
BA_ "SignalType" SG_ 1111 DTCI_SRR_SRR_TstFldOpCyc "ENM";
BA_ "SignalLongName" SG_ 1111 DTCI_SRR_SRR_TstFldOpCyc "Diagnostic Trouble Code Information Extended - SRR_SRR : Test Failed This Operation Cycle";
BA_ "SignalType" SG_ 1111 DTCI_SRR_SRR_TstFldLstClr "ENM";
BA_ "SignalLongName" SG_ 1111 DTCI_SRR_SRR_TstFldLstClr "Diagnostic Trouble Code Information Extended - SRR_SRR : Test Failed Since Last Clear";
BA_ "SignalType" SG_ 1111 DTCI_SRR_SRR_TstFld "ENM";
BA_ "SignalLongName" SG_ 1111 DTCI_SRR_SRR_TstFld "Diagnostic Trouble Code Information Extended - SRR_SRR : Test Failed";
BA_ "SignalType" SG_ 1111 DTCI_SRR_SRR_PndngDTC "ENM";
BA_ "SignalLongName" SG_ 1111 DTCI_SRR_SRR_PndngDTC "Diagnostic Trouble Code Information Extended - SRR_SRR : Pending DTC";
BA_ "SignalType" SG_ 1111 DTCI_SRR_SRR_DTCTriggered "ENM";
BA_ "SignalLongName" SG_ 1111 DTCI_SRR_SRR_DTCTriggered "Diagnostic Trouble Code Information Extended - SRR_SRR : Diagnostic Trouble Code Triggered";
BA_ "SignalType" SG_ 1111 DTCI_SRR_SRR_WrnIndTrggrd "ENM";
BA_ "SignalLongName" SG_ 1111 DTCI_SRR_SRR_WrnIndTrggrd "Diagnostic Trouble Code Information Extended - SRR_SRR : Warning Indicator Triggered";
BA_ "SignalType" SG_ 1111 DTCI_SRR_SRR_WrnIndRqd "ENM";
BA_ "SignalLongName" SG_ 1111 DTCI_SRR_SRR_WrnIndRqd "Diagnostic Trouble Code Information Extended - SRR_SRR : Warning Indicator Requested";
BA_ "SignalLongName" SG_ 1122 ASDREvntTrgrPrty "Active Safety Data Recording Event Trigger Priority";
BA_ "SignalType" SG_ 1122 ACCAutoStSpStat "ENM";
BA_ "SignalLongName" SG_ 1122 ACCAutoStSpStat "Adaptive Cruise Control Auto Set Speed Status";
BA_ "SignalType" SG_ 178 ACCBRP_ACCActvAuth "ENM";
BA_ "SignalLongName" SG_ 178 ACCBRP_ACCActvAuth "Adaptive Cruise Control General Information 1 Protected : Adaptive Cruise Control Active Authenticated";
BA_ "SignalType" SG_ 1108 LnDprtrWrnCtlSdThrtRtMirIndReq "ENM";
BA_ "SignalLongName" SG_ 1108 LnDprtrWrnCtlSdThrtRtMirIndReq "Lane Departure Warning and Control Side Threat Right Mirror Indication Request";
BA_ "SignalType" SG_ 1108 LnDprtrWrnCtlSdThrtLtMirIndReq "ENM";
BA_ "SignalLongName" SG_ 1108 LnDprtrWrnCtlSdThrtLtMirIndReq "Lane Departure Warning and Control Side Threat Left Mirror Indication Request";
BA_ "SignalLongName" SG_ 1029 LnFllwgTgtTrjctryLnCoef2 "Lane Following Target Trajectory Lane Coefficient 2";
BA_ "SignalLongName" SG_ 1029 LnFllwgTgtTrjctryLnCoef3 "Lane Following Target Trajectory Lane Coefficient 3";
BA_ "SignalLongName" SG_ 1029 LnFllwgTgtTrjctryLnCoef1 "Lane Following Target Trajectory Lane Coefficient 1";
BA_ "SignalLongName" SG_ 1029 LnFllwgTgtTrjctryLnCoef0 "Lane Following Target Trajectory Lane Coefficient 0";
BA_ "SignalType" SG_ 1045 EPBSP_ElecPrkBrkApplStsAuth "ENM";
BA_ "SignalLongName" SG_ 1045 EPBSP_ElecPrkBrkApplStsAuth "Electric Park Brake Status Protected : Electric Park Brake Application Status Authenticated";
BA_ "SignalType" SG_ 1124 TrffcLgtAsstCstAvlFlg1 "ENM";
BA_ "SignalLongName" SG_ 1124 TrffcLgtAsstCstAvlFlg1 "Traffic Light Assist Customization Availability Flag 1";
BA_ "SignalType" SG_ 1124 GlrFrHgBmRspTypCstAvlFlg7 "ENM";
BA_ "SignalLongName" SG_ 1124 GlrFrHgBmRspTypCstAvlFlg7 "Glare Free High Beam Response Type Customization Availability Flag7";
BA_ "SignalType" SG_ 1124 GlrFrHgBmRspTypCstAvlFlg6 "ENM";
BA_ "SignalLongName" SG_ 1124 GlrFrHgBmRspTypCstAvlFlg6 "Glare Free High Beam Response Type Customization Availability Flag6";
BA_ "SignalType" SG_ 1124 GlrFrHgBmRspTypCstAvlFlg5 "ENM";
BA_ "SignalLongName" SG_ 1124 GlrFrHgBmRspTypCstAvlFlg5 "Glare Free High Beam Response Type Customization Availability Flag5";
BA_ "SignalType" SG_ 1124 GlrFrHgBmRspTypCstAvlFlg4 "ENM";
BA_ "SignalLongName" SG_ 1124 GlrFrHgBmRspTypCstAvlFlg4 "Glare Free High Beam Response Type Customization Availability Flag4";
BA_ "SignalType" SG_ 1124 GlrFrHgBmRspTypCstAvlFlg3 "ENM";
BA_ "SignalLongName" SG_ 1124 GlrFrHgBmRspTypCstAvlFlg3 "Glare Free High Beam Response Type Customization Availability Flag3";
BA_ "SignalType" SG_ 1124 GlrFrHgBmRspTypCstAvlFlg2 "ENM";
BA_ "SignalLongName" SG_ 1124 GlrFrHgBmRspTypCstAvlFlg2 "Glare Free High Beam Response Type Customization Availability Flag2";
BA_ "SignalType" SG_ 1124 GlrFrHgBmRspTypCstAvlFlg1 "ENM";
BA_ "SignalLongName" SG_ 1124 GlrFrHgBmRspTypCstAvlFlg1 "Glare Free High Beam Response Type Customization Availability Flag1";
BA_ "SignalType" SG_ 1124 TrffcLgtAsstCstAvlFlg7 "ENM";
BA_ "SignalLongName" SG_ 1124 TrffcLgtAsstCstAvlFlg7 "Traffic Light Assist Customization Availability Flag 7";
BA_ "SignalType" SG_ 1124 TrffcLgtAsstCstAvlFlg6 "ENM";
BA_ "SignalLongName" SG_ 1124 TrffcLgtAsstCstAvlFlg6 "Traffic Light Assist Customization Availability Flag 6";
BA_ "SignalType" SG_ 1124 TrffcLgtAsstCstAvlFlg5 "ENM";
BA_ "SignalLongName" SG_ 1124 TrffcLgtAsstCstAvlFlg5 "Traffic Light Assist Customization Availability Flag 5";
BA_ "SignalType" SG_ 1124 TrffcLgtAsstCstAvlFlg4 "ENM";
BA_ "SignalLongName" SG_ 1124 TrffcLgtAsstCstAvlFlg4 "Traffic Light Assist Customization Availability Flag 4";
BA_ "SignalType" SG_ 1124 TrffcLgtAsstCstAvlFlg3 "ENM";
BA_ "SignalLongName" SG_ 1124 TrffcLgtAsstCstAvlFlg3 "Traffic Light Assist Customization Availability Flag 3";
BA_ "SignalType" SG_ 1124 TrffcLgtAsstCstAvlFlg2 "ENM";
BA_ "SignalLongName" SG_ 1124 TrffcLgtAsstCstAvlFlg2 "Traffic Light Assist Customization Availability Flag 2";
BA_ "SignalType" SG_ 1126 TrffcLgtAsstWrnChmEvntStat "ENM";
BA_ "SignalLongName" SG_ 1126 TrffcLgtAsstWrnChmEvntStat "Traffic Light Assist Warning Chime Event State";
BA_ "SignalType" SG_ 1129 AutoHgBmCtrlIO "ENM";
BA_ "SignalLongName" SG_ 1129 AutoHgBmCtrlIO "Auto High Beam Control Indication On";
BA_ "SignalType" SG_ 1131 TrffcLgtAsstCstSetAval "ENM";
BA_ "SignalLongName" SG_ 1131 TrffcLgtAsstCstSetAval "Traffic Light Assist Customization Setting Available";
BA_ "SignalType" SG_ 1131 GlrFrHgBmRspTypCstStAvl "ENM";
BA_ "SignalLongName" SG_ 1131 GlrFrHgBmRspTypCstStAvl "Glare Free High Beam Response Type Customization Setting Available";
BA_ "SignalType" SG_ 1131 TrffcLgtAsstCstCurrSetVal "ENM";
BA_ "SignalLongName" SG_ 1131 TrffcLgtAsstCstCurrSetVal "Traffic Light Assist Customization Current Setting Value";
BA_ "SignalType" SG_ 1131 GlrFrHgBmRspTypCstCurSetVal "ENM";
BA_ "SignalLongName" SG_ 1131 GlrFrHgBmRspTypCstCurSetVal "Glare Free High Beam Response Type Customization Current Setting Value";
BA_ "SignalLongName" SG_ 1070 FCODP_Brst1_PCSM "Front Camera Object Detection and Processing Burst 1 Protected Counter Sync Message";
BA_ "SignalType" SG_ 17 FsdLoclzdRdTyp "ENM";
BA_ "SignalLongName" SG_ 17 FsdLoclzdRdTyp "Fused Localized Road Type";
BA_ "SignalLongName" SG_ 518 GPSC_PPSLat "Global Positioning System Coordinates : Precise Positioning System Latitude";
BA_ "SignalLongName" SG_ 518 GPSC_PPSLong "Global Positioning System Coordinates : Precise Positioning System Longitude";
BA_ "SignalType" SG_ 518 GPSC_PPSLat_Inv "ENM";
BA_ "SignalLongName" SG_ 518 GPSC_PPSLat_Inv "Global Positioning System Coordinates : Precise Positioning System Latitude Invalid";
BA_ "SignalType" SG_ 518 GPSC_PPSLong_Inv "ENM";
BA_ "SignalLongName" SG_ 518 GPSC_PPSLong_Inv "Global Positioning System Coordinates : Precise Positioning System Longitude Invalid";
BA_ "SignalLongName" SG_ 1128 TSMCurrSpdLim "Traffic Sign Memory Current Speed Limit";
BA_ "SignalType" SG_ 1128 TSMEurDispSgn2Mn "ENM";
BA_ "SignalLongName" SG_ 1128 TSMEurDispSgn2Mn "Traffic Sign Memory Europe Display Europe Sign 2 Main";
BA_ "SignalType" SG_ 1128 TSMEurDispSgn1Mn "ENM";
BA_ "SignalLongName" SG_ 1128 TSMEurDispSgn1Mn "Traffic Sign Memory Europe Display Sign 1 Main";
BA_ "SignalType" SG_ 1128 TSMUSAndCADispSgn1Mn "ENM";
BA_ "SignalLongName" SG_ 1128 TSMUSAndCADispSgn1Mn "Traffic Sign Memory US and Canada Display Sign 1 Main";
BA_ "SignalType" SG_ 1128 TSMUSAndCADispSgn2Mn "ENM";
BA_ "SignalLongName" SG_ 1128 TSMUSAndCADispSgn2Mn "Traffic Sign Memory US and Canada Display Sign 2 Main";
BA_ "SignalType" SG_ 1128 TSMEurDispSgn2AddOn "ENM";
BA_ "SignalLongName" SG_ 1128 TSMEurDispSgn2AddOn "Traffic Sign Memory Display Sign 2 Add-On";
BA_ "SignalType" SG_ 1128 TSMEurDispSgn1AddOn "ENM";
BA_ "SignalLongName" SG_ 1128 TSMEurDispSgn1AddOn "Traffic Sign Memory Europe Display Sign 1 Add-On";
BA_ "SignalType" SG_ 1128 FrwdVsFlDtcnIndOn "ENM";
BA_ "SignalLongName" SG_ 1128 FrwdVsFlDtcnIndOn "Front Vision Failure Detection Indication On";
BA_ "SignalType" SG_ 1128 FrwdVsAdvWthrIndOn "ENM";
BA_ "SignalLongName" SG_ 1128 FrwdVsAdvWthrIndOn "Front Vision Adverse Weather Indication On";
BA_ "SignalType" SG_ 1128 TSMUSAndCADispSgn2AddOn "ENM";
BA_ "SignalLongName" SG_ 1128 TSMUSAndCADispSgn2AddOn "Traffic Sign Memory US and Canada Display Sign 2 Add On";
BA_ "SignalType" SG_ 1128 TSMUSAndCADispSgn1AddOn "ENM";
BA_ "SignalLongName" SG_ 1128 TSMUSAndCADispSgn1AddOn "Traffic Sign Memory US and Canada Display Sign 1 Add On";
BA_ "SignalType" SG_ 1128 TrffcLgtAsstHUDWrnIndOn "ENM";
BA_ "SignalLongName" SG_ 1128 TrffcLgtAsstHUDWrnIndOn "Traffic Light Assist Heads up Display Warning Indication On";
BA_ "SignalType" SG_ 1128 TrffcLgtAsstClstrWrnIndOn "ENM";
BA_ "SignalLongName" SG_ 1128 TrffcLgtAsstClstrWrnIndOn "Traffic Light Assist Cluster Warning Indication On";
BA_ "SignalType" SG_ 1128 TSMSgnNtfnIndOn "ENM";
BA_ "SignalLongName" SG_ 1128 TSMSgnNtfnIndOn "Traffic Sign Memory Sign Notification Indication On";
BA_ "SignalType" SG_ 1128 TSMPDAMnSgnFlshgReq "ENM";
BA_ "SignalLongName" SG_ 1128 TSMPDAMnSgnFlshgReq "Traffic Sign Memory PDA Main Sign Flashing Request";
BA_ "SignalType" SG_ 1128 TSMNoEntryIndOn "ENM";
BA_ "SignalLongName" SG_ 1128 TSMNoEntryIndOn "Traffic Sign Memory No Entry Indication On";
BA_ "SignalType" SG_ 1128 TSMIcePsblIndOn "ENM";
BA_ "SignalLongName" SG_ 1128 TSMIcePsblIndOn "Traffic Sign Memory Ice Possible Indication On";
BA_ "SignalType" SG_ 1128 TSMAddTrfSgnAvIndOn "ENM";
BA_ "SignalLongName" SG_ 1128 TSMAddTrfSgnAvIndOn "Traffic Sign Memory Additional Traffic Signs Available Indication On";
BA_ "SignalType" SG_ 1128 FrwdVsFllBlckIndOn "ENM";
BA_ "SignalLongName" SG_ 1128 FrwdVsFllBlckIndOn "Front Vision Full Blockage Indication On";
BA_ "SignalType" SG_ 1128 TrffcLgtAsstRLADWrnIndOn "ENM";
BA_ "SignalLongName" SG_ 1128 TrffcLgtAsstRLADWrnIndOn "Traffic Light Assist Reflective Light Auxiliary Display Warning Indication On";
BA_ "SignalType" SG_ 1119 ADASIS_NAVILINK_DgtlMpEfSpdLm "ENM";
BA_ "SignalLongName" SG_ 1119 ADASIS_NAVILINK_DgtlMpEfSpdLm "ADASIS NAVILINK Digital Map Effective Speed Limit";
BA_ "SignalType" SG_ 1119 ADASIS_NAVILINK_CntryCd "ENM";
BA_ "SignalLongName" SG_ 1119 ADASIS_NAVILINK_CntryCd "ADASIS NAVILINK Country Code";
BA_ "SignalType" SG_ 1119 ADASIS_NAVILINK_DigMpCndlSpdLmt "ENM";
BA_ "SignalLongName" SG_ 1119 ADASIS_NAVILINK_DigMpCndlSpdLmt "ADASIS NAVILINK Digital Map Conditional Speed Limit";
BA_ "SignalType" SG_ 1119 ADASIS_NAVILINK_DgtlMpSpdCtgry "ENM";
BA_ "SignalLongName" SG_ 1119 ADASIS_NAVILINK_DgtlMpSpdCtgry "ADASIS NAVILINK Digital Map Speed Category";
BA_ "SignalType" SG_ 1119 ADASIS_NAVILINK_DgtlMpPsngRst "ENM";
BA_ "SignalLongName" SG_ 1119 ADASIS_NAVILINK_DgtlMpPsngRst "ADASIS NAVILINK Digital Map Passing Restriction";
BA_ "SignalType" SG_ 1119 ADASIS_NAVILINK_DigMpEfSpdLmTyp "ENM";
BA_ "SignalLongName" SG_ 1119 ADASIS_NAVILINK_DigMpEfSpdLmTyp "ADASIS NAVILINK Digital Map Effective Speed Limit Type";
BA_ "SignalType" SG_ 1119 ADASIS_NAVILINK_DgMpCnSpdLmTyp "ENM";
BA_ "SignalLongName" SG_ 1119 ADASIS_NAVILINK_DgMpCnSpdLmTyp "ADASIS NAVILINK Digital Map Conditional Speed Limit Type";
BA_ "SignalType" SG_ 1119 ADASIS_NAVILINK_DigMpPstSpdLmAs "ENM";
BA_ "SignalLongName" SG_ 1119 ADASIS_NAVILINK_DigMpPstSpdLmAs "ADASIS NAVILINK Digital Map Posted Speed Limit Assured";
BA_ "SignalType" SG_ 1119 ADASIS_NAVILINK_DigMpDrvngSd "ENM";
BA_ "SignalLongName" SG_ 1119 ADASIS_NAVILINK_DigMpDrvngSd "ADASIS NAVILINK Digital Map Driving Side";
BA_ "SignalType" SG_ 1119 ADASIS_NAVILINK_CntrldAccssRd "ENM";
BA_ "SignalLongName" SG_ 1119 ADASIS_NAVILINK_CntrldAccssRd "ADASIS NAVILINK Controlled Access Road";
BA_ "SignalType" SG_ 1119 ADASIS_NAVILINK_BldUpFlg "ENM";
BA_ "SignalLongName" SG_ 1119 ADASIS_NAVILINK_BldUpFlg "ADASIS NAVILINK Build Up Flag";
BA_ "SignalLongName" SG_ 1120 ADASIS_NAVILINK_SpdLmtPstdSpd "ADASIS NAVILINK Speed Limit Posted Speed";
BA_ "SignalLongName" SG_ 1120 ADASIS_NAVILINK_SpdLmtRcmdSpd "ADASIS NAVILINK Speed Limit Recommended Speed";
BA_ "SignalType" SG_ 1120 ADASIS_NAVILINK_FncRdClss "ENM";
BA_ "SignalLongName" SG_ 1120 ADASIS_NAVILINK_FncRdClss "ADASIS NAVILINK Functional Road Class";
BA_ "SignalType" SG_ 1120 ADASIS_NAVILINK_DigMpVerYr "ENM";
BA_ "SignalLongName" SG_ 1120 ADASIS_NAVILINK_DigMpVerYr "ADASIS NAVILINK Digital Map Version Year";
BA_ "SignalType" SG_ 1120 ADASIS_NAVILINK_SpdLmtUnt "ENM";
BA_ "SignalLongName" SG_ 1120 ADASIS_NAVILINK_SpdLmtUnt "ADASIS NAVILINK Speed Limit Unit";
BA_ "SignalType" SG_ 1120 ADASIS_NAVILINK_SpdLmtPsdSpd_DuD "ENM";
BA_ "SignalLongName" SG_ 1120 ADASIS_NAVILINK_SpdLmtPsdSpd_DuD "ADASIS NAVILINK Speed Limit Posted Speed Don't Use Data";
BA_ "SignalType" SG_ 1120 ADASIS_NAVILINK_MpDtAv "ENM";
BA_ "SignalLongName" SG_ 1120 ADASIS_NAVILINK_MpDtAv "ADASIS NAVILINK Map data availability";
BA_ "SignalType" SG_ 1120 ADASIS_NAVILINK_LnCtgry "ENM";
BA_ "SignalLongName" SG_ 1120 ADASIS_NAVILINK_LnCtgry "ADASIS NAVILINK Lane Category";
BA_ "SignalType" SG_ 1120 ADASIS_NAVILINK_DigMpVerQtr "ENM";
BA_ "SignalLongName" SG_ 1120 ADASIS_NAVILINK_DigMpVerQtr "ADASIS NAVILINK Digital Map Version Quarter";
BA_ "SignalType" SG_ 1120 ADASIS_NAVILINK_SprtdLnRd "ENM";
BA_ "SignalLongName" SG_ 1120 ADASIS_NAVILINK_SprtdLnRd "ADASIS NAVILINK Separated Lane Road";
BA_ "SignalLongName" SG_ 1060 VehIdNmDig1 "Vehicle Identification Number Digit 1";
BA_ "SignalType" SG_ 514 EASSI_StrtStpSt "ENM";
BA_ "SignalLongName" SG_ 514 EASSI_StrtStpSt "Engine Auto Start Stop Information : Start Stop State";
BA_ "SignalLongName" SG_ 577 HstVehPathParms_PCSM "Host Vehicle Path Parameters Protected Counter Sync Message";
BA_ "SignalLongName" SG_ 32 HVPPP_MAC "Host Vehicle Path Parameters Protected : MAC";
BA_ "SignalLongName" SG_ 32 HVPPP_FCnt "Host Vehicle Path Parameters Protected : Freshness Counter";
BA_ "SignalLongName" SG_ 32 HVPPP_HstVehTrnCntrLatOfstAuth "Host Vehicle Path Parameters Protected : Host Vehicle Turn Center Lateral Offset Authenticated";
BA_ "SignalType" SG_ 32 HVPPP_ShrtRngRadarModeCmdAuth "ENM";
BA_ "SignalLongName" SG_ 32 HVPPP_ShrtRngRadarModeCmdAuth "Host Vehicle Path Parameters Protected : Short Range Radar Mode Command Authenticated";
BA_ "SignalType" SG_ 32 HVPPP_LngRngRadarModeCmdAuth "ENM";
BA_ "SignalLongName" SG_ 32 HVPPP_LngRngRadarModeCmdAuth "Host Vehicle Path Parameters Protected : Long Range Radar Mode Command Authenticated";
BA_ "SignalType" SG_ 32 HVPPP_HstVehLatVelAuth_Inv "ENM";
BA_ "SignalLongName" SG_ 32 HVPPP_HstVehLatVelAuth_Inv "Host Vehicle Path Parameters Protected : Host Vehicle Lateral Velocity Authenticated Invalid";
BA_ "SignalLongName" SG_ 32 HVPPP_HstVehYawRateAuth "Host Vehicle Path Parameters Protected : Host Vehicle Yaw Rate Authenticated";
BA_ "SignalLongName" SG_ 32 HVPPP_ObjSnsrTmSyncMstrClckAuth "Host Vehicle Path Parameters Protected : Object Sensor Time Sync Master Clock Authenticated";
BA_ "SignalType" SG_ 32 HVPPP_HstVehVelAuth_Inv "ENM";
BA_ "SignalLongName" SG_ 32 HVPPP_HstVehVelAuth_Inv "Host Vehicle Path Parameters Protected : Host Vehicle Velocity Authenticated Invalid";
BA_ "SignalLongName" SG_ 32 HVPPP_HstVehPathCrvDrvtAuth "Host Vehicle Path Parameters Protected : Host Vehicle Path Curvature Derivative Authenticated";
BA_ "SignalLongName" SG_ 32 HVPPP_HstVehLatVelAuth "Host Vehicle Path Parameters Protected : Host Vehicle Lateral Velocity Authenticated";
BA_ "SignalType" SG_ 32 HVPPP_ObjsRetndRrwdSnsrsAuth "ENM";
BA_ "SignalLongName" SG_ 32 HVPPP_ObjsRetndRrwdSnsrsAuth "Host Vehicle Path Parameters Protected : Objects Returned from Rearward Sensors Authenticated";
BA_ "SignalLongName" SG_ 32 HVPPP_HstVehLngVelAuth "Host Vehicle Path Parameters Protected : Host Vehicle Longitudinal Velocity Authenticated";
BA_ "SignalLongName" SG_ 32 HVPPP_HstVehTrnCntrLngOfstAuth "Host Vehicle Path Parameters Protected : Host Vehicle Turn Center Longitudinal Offset Authenticated";
BA_ "SignalType" SG_ 32 HVPPP_HstVehLngVelAuth_Inv "ENM";
BA_ "SignalLongName" SG_ 32 HVPPP_HstVehLngVelAuth_Inv "Host Vehicle Path Parameters Protected : Host Vehicle Longitudinal Velocity Authenticated Invalid";
BA_ "SignalLongName" SG_ 32 HVPPP_HstVehPathCrvAuth "Host Vehicle Path Parameters Protected : Host Vehicle Path Curvature Authenticated";
BA_ "SignalLongName" SG_ 32 HVPPP_HstVehVelAuth "Host Vehicle Path Parameters Protected : Host Vehicle Velocity Authenticated";
BA_ "SignalLongName" SG_ 32 HVPPP_HstVehSdslAngAuth "Host Vehicle Path Parameters Protected : Host Vehicle Sideslip Angle Authenticated";
BA_ "SignalType" SG_ 32 HVPPP_ObjsRetndFrwdSnsrsAuth "ENM";
BA_ "SignalLongName" SG_ 32 HVPPP_ObjsRetndFrwdSnsrsAuth "Host Vehicle Path Parameters Protected : Objects Returned from Forward Sensors Authenticated";
BA_ "SignalLongName" SG_ 32 HVPPP_ARC "Host Vehicle Path Parameters Protected : Alive Rolling Count";
BA_ "SignalType" SG_ 32 HVPPP_HstVehPathModeAuth "ENM";
BA_ "SignalLongName" SG_ 32 HVPPP_HstVehPathModeAuth "Host Vehicle Path Parameters Protected : Host Vehicle Path Mode Authenticated";
BA_ "SignalType" SG_ 32 HVPPP_HstVehYawRateAuth_Inv "ENM";
BA_ "SignalLongName" SG_ 32 HVPPP_HstVehYawRateAuth_Inv "Host Vehicle Path Parameters Protected : Host Vehicle Yaw Rate Authenticated Invalid";
BA_ "SignalType" SG_ 32 HVPPP_HstVehTrvlDirAuth "ENM";
BA_ "SignalLongName" SG_ 32 HVPPP_HstVehTrvlDirAuth "Host Vehicle Path Parameters Protected : Host Vehicle Travel Direction Authenticated";
BA_ "SignalType" SG_ 32 HVPPP_FrwdVsnModeCmdAuth "ENM";
BA_ "SignalLongName" SG_ 32 HVPPP_FrwdVsnModeCmdAuth "Host Vehicle Path Parameters Protected : Forward Vision Mode Command Authenticated";
BA_ "SignalLongName" SG_ 1082 LRRODP_Brst1_PCSM "Long Range Radar Object Detection and Processing Burst 1 Protected Counter Sync Message";
BA_ "SignalLongName" SG_ 593 LongLatData_PCSM "Longitudinal Lateral Data Protected Counter Sync Message";
BA_ "SignalLongName" SG_ 36 LLDP_MAC "Longitudinal Lateral Data Protected : MAC";
BA_ "SignalLongName" SG_ 36 LLDP_FCnt "Longitudinal Lateral Data Protected : Freshness Counter";
BA_ "SignalLongName" SG_ 36 LLDP_LatAccelAuth "Longitudinal Lateral Data Protected : Lateral Acceleration Authenticated";
BA_ "SignalLongName" SG_ 36 LLDP_LongAccelAuth "Longitudinal Lateral Data Protected : Longitudinal Acceleration Authenticated";
BA_ "SignalType" SG_ 36 LLDP_LatAccelSnsrCorrStsAuth "ENM";
BA_ "SignalLongName" SG_ 36 LLDP_LatAccelSnsrCorrStsAuth "Longitudinal Lateral Data Protected : Lateral Acceleration Sensor Correlation Status Authenticated";
BA_ "SignalType" SG_ 36 LLDP_LatAccelAuth_Inv "ENM";
BA_ "SignalLongName" SG_ 36 LLDP_LatAccelAuth_Inv "Longitudinal Lateral Data Protected : Lateral Acceleration Authenticated Invalid";
BA_ "SignalType" SG_ 36 LLDP_LongAccelAuth_Inv "ENM";
BA_ "SignalLongName" SG_ 36 LLDP_LongAccelAuth_Inv "Longitudinal Lateral Data Protected : Longitudinal Acceleration Authenticated Invalid";
BA_ "SignalLongName" SG_ 36 LLDP_ARC "Longitudinal Lateral Data Protected : Alive Rolling Count";
BA_ "SignalType" SG_ 36 LLDP_VehAccelCalAuth "ENM";
BA_ "SignalLongName" SG_ 36 LLDP_VehAccelCalAuth "Longitudinal Lateral Data Protected : Vehicle Acceleration Calibrated Authenticated";
BA_ "SignalType" SG_ 36 LLDP_VehAccelAuth_DuD "ENM";
BA_ "SignalLongName" SG_ 36 LLDP_VehAccelAuth_DuD "Longitudinal Lateral Data Protected : Vehicle Acceleration Authenticated Don't Use Data";
BA_ "SignalType" SG_ 36 LLDP_LongAccelSnsrCorrStsAuth "ENM";
BA_ "SignalLongName" SG_ 36 LLDP_LongAccelSnsrCorrStsAuth "Longitudinal Lateral Data Protected : Longitudinal Acceleration Sensor Correlation Status Authenticated";
BA_ "SignalType" SG_ 1377 NodeStsAPA_CAN_2_LcFA "ENM";
BA_ "SignalLongName" SG_ 1377 NodeStsAPA_CAN_2_LcFA "Node Status APA_CAN_2 Loss of Communication Fault Active";
BA_ "SignalType" SG_ 1377 NodeStsAPA_CAN_1_LcFA "ENM";
BA_ "SignalLongName" SG_ 1377 NodeStsAPA_CAN_1_LcFA "Node Status APA_CAN_1 Loss of Communication Fault Active";
BA_ "SignalType" SG_ 1377 NodeStsAOS_LcFA "ENM";
BA_ "SignalLongName" SG_ 1377 NodeStsAOS_LcFA "Node Status AOS Loss of Communication Fault Active";
BA_ "SignalType" SG_ 1377 NodeStsAMP_LcFA "ENM";
BA_ "SignalLongName" SG_ 1377 NodeStsAMP_LcFA "Node Status AMP Loss of Communication Fault Active";
BA_ "SignalType" SG_ 1377 NodeStsALC_LcFA "ENM";
BA_ "SignalLongName" SG_ 1377 NodeStsALC_LcFA "Node Status ALC Loss of Communication Fault Active";
BA_ "SignalType" SG_ 1377 NodeStsAHL_AFL_LcFA "ENM";
BA_ "SignalLongName" SG_ 1377 NodeStsAHL_AFL_LcFA "Node Status AHL_AFL Loss of Communication Fault Active";
BA_ "SignalType" SG_ 1377 NodeStsAGC_LcFA "ENM";
BA_ "SignalLongName" SG_ 1377 NodeStsAGC_LcFA "Node Status AGC Loss of Communication Fault Active";
BA_ "SignalType" SG_ 1377 NodeStsDMS_LcFA "ENM";
BA_ "SignalLongName" SG_ 1377 NodeStsDMS_LcFA "Node Status DMS Loss of Communication Fault Active";
BA_ "SignalType" SG_ 1377 NodeStsDEFC_LcFA "ENM";
BA_ "SignalLongName" SG_ 1377 NodeStsDEFC_LcFA "Node Status DEFC Loss of Communication Fault Active";
BA_ "SignalType" SG_ 1377 NodeStsDCM_LcFA "ENM";
BA_ "SignalLongName" SG_ 1377 NodeStsDCM_LcFA "Node Status DCM Loss of Communication Fault Active";
BA_ "SignalType" SG_ 1377 NodeStsCSM_LcFA "ENM";
BA_ "SignalLongName" SG_ 1377 NodeStsCSM_LcFA "Node Status CSM Loss of Communication Fault Active";
BA_ "SignalType" SG_ 1377 NodeStsBSM_CAN_3_LcFA "ENM";
BA_ "SignalLongName" SG_ 1377 NodeStsBSM_CAN_3_LcFA "Node Status BSM_CAN_3 Loss of Communication Fault Active";
BA_ "SignalType" SG_ 1377 NodeStsBSM_CAN_2_LcFA "ENM";
BA_ "SignalLongName" SG_ 1377 NodeStsBSM_CAN_2_LcFA "Node Status BSM_CAN_2 Loss of Communication Fault Active";
BA_ "SignalType" SG_ 1377 NodeStsBCM_LcFA "ENM";
BA_ "SignalLongName" SG_ 1377 NodeStsBCM_LcFA "Node Status BCM Loss of Communication Fault Active";
BA_ "SignalType" SG_ 1377 NodeStsARB_LcFA "ENM";
BA_ "SignalLongName" SG_ 1377 NodeStsARB_LcFA "Node Status ARB Loss of Communication Fault Active";
BA_ "SignalType" SG_ 1377 NodeStsELM_LcFA "ENM";
BA_ "SignalLongName" SG_ 1377 NodeStsELM_LcFA "Node Status ELM Loss of Communication Fault Active";
BA_ "SignalType" SG_ 1377 NodeStsECP_X1_CAN_3_LcFA "ENM";
BA_ "SignalLongName" SG_ 1377 NodeStsECP_X1_CAN_3_LcFA "Node Status ECP_X1_CAN_3 Loss of Communication Fault Active";
BA_ "SignalType" SG_ 1377 NodeStsECP_X1_CAN_2_LcFA "ENM";
BA_ "SignalLongName" SG_ 1377 NodeStsECP_X1_CAN_2_LcFA "Node Status ECP_X1_CAN_2 Loss of Communication Fault Active";
BA_ "SignalType" SG_ 1377 NodeStsECM_CAN_3_LcFA "ENM";
BA_ "SignalLongName" SG_ 1377 NodeStsECM_CAN_3_LcFA "Node Status ECM_CAN_3 Loss of Communication Fault Active";
BA_ "SignalType" SG_ 1377 NodeStsECM_CAN_2_LcFA "ENM";
BA_ "SignalLongName" SG_ 1377 NodeStsECM_CAN_2_LcFA "Node Status ECM_CAN_2 Loss of Communication Fault Active";
BA_ "SignalType" SG_ 1377 NodeStsEBCM_CAN_2_LcFA "ENM";
BA_ "SignalLongName" SG_ 1377 NodeStsEBCM_CAN_2_LcFA "Node Status EBCM_CAN_2 Loss of Communication Fault Active";
BA_ "SignalType" SG_ 1377 NodeStsEBCM_CAN_1_LcFA "ENM";
BA_ "SignalLongName" SG_ 1377 NodeStsEBCM_CAN_1_LcFA "Node Status EBCM_CAN_1 Loss of Communication Fault Active";
BA_ "SignalType" SG_ 1377 NodeStsEPS_LcFA "ENM";
BA_ "SignalLongName" SG_ 1377 NodeStsEPS_LcFA "Node Status EPS Loss of Communication Fault Active";
BA_ "SignalType" SG_ 1377 NodeStsEOCM_HCP2_LcFA "ENM";
BA_ "SignalLongName" SG_ 1377 NodeStsEOCM_HCP2_LcFA "Node Status EOCM_HCP2 Loss of Communication Fault Active";
BA_ "SignalType" SG_ 1377 NodeStsEOCM_HCP1_CAN_8_LcFA "ENM";
BA_ "SignalLongName" SG_ 1377 NodeStsEOCM_HCP1_CAN_8_LcFA "Node Status EOCM_HCP1_CAN_8 Loss of Communication Fault Active";
BA_ "SignalType" SG_ 1377 NodeStsEOCM_HCP1_CAN_2_LcFA "ENM";
BA_ "SignalLongName" SG_ 1377 NodeStsEOCM_HCP1_CAN_2_LcFA "Node Status EOCM_HCP1_CAN_2 Loss of Communication Fault Active";
BA_ "SignalType" SG_ 1377 NodeStsEOCM_HCP1_CAN_1_LcFA "ENM";
BA_ "SignalLongName" SG_ 1377 NodeStsEOCM_HCP1_CAN_1_LcFA "Node Status EOCM_HCP1_CAN_1 Loss of Communication Fault Active";
BA_ "SignalType" SG_ 1377 NodeStsEOCM_CAN_8_LcFA "ENM";
BA_ "SignalLongName" SG_ 1377 NodeStsEOCM_CAN_8_LcFA "Node Status EOCM_CAN_8 Loss of Communication Fault Active";
BA_ "SignalType" SG_ 1377 NodeStsEOCM_CAN_2_LcFA "ENM";
BA_ "SignalLongName" SG_ 1377 NodeStsEOCM_CAN_2_LcFA "Node Status EOCM_CAN_2 Loss of Communication Fault Active";
BA_ "SignalType" SG_ 1377 NodeStsEOCM_CAN_1_LcFA "ENM";
BA_ "SignalLongName" SG_ 1377 NodeStsEOCM_CAN_1_LcFA "Node Status EOCM_CAN_1 Loss of Communication Fault Active";
BA_ "SignalType" SG_ 1377 NodeStsIPC_LcFA "ENM";
BA_ "SignalLongName" SG_ 1377 NodeStsIPC_LcFA "Node Status IPC Loss of Communication Fault Active";
BA_ "SignalType" SG_ 1377 NodeStsICS_Info_LcFA "ENM";
BA_ "SignalLongName" SG_ 1377 NodeStsICS_Info_LcFA "Node Status ICS_Info Loss of Communication Fault Active";
BA_ "SignalType" SG_ 1377 NodeStsICCM_LcFA "ENM";
BA_ "SignalLongName" SG_ 1377 NodeStsICCM_LcFA "Node Status ICCM Loss of Communication Fault Active";
BA_ "SignalType" SG_ 1377 NodeStsHVAC_FP_R_LcFA "ENM";
BA_ "SignalLongName" SG_ 1377 NodeStsHVAC_FP_R_LcFA "Node Status HVAC_FP_R Loss of Communication Fault Active";
BA_ "SignalType" SG_ 1377 NodeStsHVAC_FP_F_LcFA "ENM";
BA_ "SignalLongName" SG_ 1377 NodeStsHVAC_FP_F_LcFA "Node Status HVAC_FP_F Loss of Communication Fault Active";
BA_ "SignalType" SG_ 1377 NodeStsHUD_CAN_LcFA "ENM";
BA_ "SignalLongName" SG_ 1377 NodeStsHUD_CAN_LcFA "Node Status HUD_CAN Loss of Communication Fault Active";
BA_ "SignalType" SG_ 1377 NodeStsFCM_LcFA "ENM";
BA_ "SignalLongName" SG_ 1377 NodeStsFCM_LcFA "Node Status FCM Loss of Communication Fault Active";
BA_ "SignalType" SG_ 1377 NodeStsFCM_LC_LcFA "ENM";
BA_ "SignalLongName" SG_ 1377 NodeStsFCM_LC_LcFA "Node Status FCM LC Loss of Communication Fault Active";
BA_ "SignalType" SG_ 1377 NodeStsMSM_D_LcFA "ENM";
BA_ "SignalLongName" SG_ 1377 NodeStsMSM_D_LcFA "Node Status MSM_D Loss of Communication Fault Active";
BA_ "SignalType" SG_ 1377 NodeStsMSB2_LcFA "ENM";
BA_ "SignalLongName" SG_ 1377 NodeStsMSB2_LcFA "Node Status MSB2 Loss of Communication Fault Active";
BA_ "SignalType" SG_ 1377 NodeStsMSB1_LcFA "ENM";
BA_ "SignalLongName" SG_ 1377 NodeStsMSB1_LcFA "Node Status MSB1 Loss of Communication Fault Active";
BA_ "SignalType" SG_ 1377 NodeStsMRCM_R_LcFA "ENM";
BA_ "SignalLongName" SG_ 1377 NodeStsMRCM_R_LcFA "Node Status MRCM_R Loss of Communication Fault Active";
BA_ "SignalType" SG_ 1377 NodeStsMRCM_L_LcFA "ENM";
BA_ "SignalLongName" SG_ 1377 NodeStsMRCM_L_LcFA "Node Status MRCM_L Loss of Communication Fault Active";
BA_ "SignalType" SG_ 1377 NodeStsMFC_LcFA "ENM";
BA_ "SignalLongName" SG_ 1377 NodeStsMFC_LcFA "Node Status MFC Loss of Communication Fault Active";
BA_ "SignalType" SG_ 1377 NodeStsLRR_LcFA "ENM";
BA_ "SignalLongName" SG_ 1377 NodeStsLRR_LcFA "Node Status LRR Loss of Communication Fault Active";
BA_ "SignalType" SG_ 1377 NodeStsLRR_HC_LcFA "ENM";
BA_ "SignalLongName" SG_ 1377 NodeStsLRR_HC_LcFA "Node StatusLRR_HC Loss of Communication Fault Active";
BA_ "SignalType" SG_ 1377 NodeStsPDR_LcFA "ENM";
BA_ "SignalLongName" SG_ 1377 NodeStsPDR_LcFA "Node Status PDR Loss of Communication Fault Active";
BA_ "SignalType" SG_ 1377 NodeStsPA_LcFA "ENM";
BA_ "SignalLongName" SG_ 1377 NodeStsPA_LcFA "Node Status PA Loss of Communication Fault Active";
BA_ "SignalType" SG_ 1377 NodeStsNVM_LcFA "ENM";
BA_ "SignalLongName" SG_ 1377 NodeStsNVM_LcFA "Node Status NVM Loss of Communication Fault Active";
BA_ "SignalType" SG_ 1377 NodeStsMTCM_R_LcFA "ENM";
BA_ "SignalLongName" SG_ 1377 NodeStsMTCM_R_LcFA "Node Status MTCM_R Loss of Communication Fault Active";
BA_ "SignalType" SG_ 1377 NodeStsMTCM_L_LcFA "ENM";
BA_ "SignalLongName" SG_ 1377 NodeStsMTCM_L_LcFA "Node Status MTCM_L Loss of Communication Fault Active";
BA_ "SignalType" SG_ 1377 NodeStsMSM_RR_LcFA "ENM";
BA_ "SignalLongName" SG_ 1377 NodeStsMSM_RR_LcFA "Node Status MSM_RR Loss of Communication Fault Active";
BA_ "SignalType" SG_ 1377 NodeStsMSM_P_LcFA "ENM";
BA_ "SignalLongName" SG_ 1377 NodeStsMSM_P_LcFA "Node Status MSM_P Loss of Communication Fault Active";
BA_ "SignalType" SG_ 1377 NodeStsMSM_LR_LcFA "ENM";
BA_ "SignalLongName" SG_ 1377 NodeStsMSM_LR_LcFA "Node Status MSM_LR Loss of Communication Fault Active";
BA_ "SignalType" SG_ 1377 NodeStsSBZA_R_LcFA "ENM";
BA_ "SignalLongName" SG_ 1377 NodeStsSBZA_R_LcFA "Node Status SBZA_R Loss of Communication Fault Active";
BA_ "SignalType" SG_ 1377 NodeStsSBZA_L_LcFA "ENM";
BA_ "SignalLongName" SG_ 1377 NodeStsSBZA_L_LcFA "Node Status SBZA_L Loss of Communication Fault Active";
BA_ "SignalType" SG_ 1377 NodeStsSADS_LcFA "ENM";
BA_ "SignalLongName" SG_ 1377 NodeStsSADS_LcFA "Node Status SADS Loss of Communication Fault Active";
BA_ "SignalType" SG_ 1377 NodeStsAHS_LcFA "ENM";
BA_ "SignalLongName" SG_ 1377 NodeStsAHS_LcFA "Node Status AHS Loss of Communication Fault Active";
BA_ "SignalType" SG_ 1377 NodeStsRSC_LcFA "ENM";
BA_ "SignalLongName" SG_ 1377 NodeStsRSC_LcFA "Node Status RSC Loss of Communication Fault Active";
BA_ "SignalType" SG_ 1377 NodeStsRDCM_LcFA "ENM";
BA_ "SignalLongName" SG_ 1377 NodeStsRDCM_LcFA "Node Status RDCM Loss of Communication Fault Active";
BA_ "SignalType" SG_ 1377 NodeStsRadioLow_LcFA "ENM";
BA_ "SignalLongName" SG_ 1377 NodeStsRadioLow_LcFA "Node Status RadioLow Loss of Communication Fault Active";
BA_ "SignalType" SG_ 1377 NodeStsPTM_LcFA "ENM";
BA_ "SignalLongName" SG_ 1377 NodeStsPTM_LcFA "Node Status PTM Loss of Communication Fault Active";
BA_ "SignalType" SG_ 1378 NodeStsSRR_SLR_LcFA "ENM";
BA_ "SignalLongName" SG_ 1378 NodeStsSRR_SLR_LcFA "Node Status SRR_SLR Loss of Communication Fault Active";
BA_ "SignalType" SG_ 1378 NodeStsSRR_RR_LcFA "ENM";
BA_ "SignalLongName" SG_ 1378 NodeStsSRR_RR_LcFA "Node Status SRR_RR Loss of Communication Fault Active";
BA_ "SignalType" SG_ 1378 NodeStsSRR_RF_LcFA "ENM";
BA_ "SignalLongName" SG_ 1378 NodeStsSRR_RF_LcFA "Node Status SRR_RF Loss of Communication Fault Active";
BA_ "SignalType" SG_ 1378 NodeStsSRR_LR_CR_LcFA "ENM";
BA_ "SignalLongName" SG_ 1378 NodeStsSRR_LR_CR_LcFA "Node Status SRR_LR_CR Loss of Communication Fault Active";
BA_ "SignalType" SG_ 1378 NodeStsSRR_LF_LcFA "ENM";
BA_ "SignalLongName" SG_ 1378 NodeStsSRR_LF_LcFA "Node Status SRR_LF Loss of Communication Fault Active";
BA_ "SignalType" SG_ 1378 NodeStsSIB_LcFA "ENM";
BA_ "SignalLongName" SG_ 1378 NodeStsSIB_LcFA "Node Status SIB Loss of Communication Fault Active";
BA_ "SignalType" SG_ 1378 NodeStsSDM_LcFA "ENM";
BA_ "SignalLongName" SG_ 1378 NodeStsSDM_LcFA "Node Status SDM Loss of Communication Fault Active";
BA_ "SignalType" SG_ 1378 NodeStsSCL_LcFA "ENM";
BA_ "SignalLongName" SG_ 1378 NodeStsSCL_LcFA "Node Status SCL Loss of Communication Fault Active";
BA_ "SignalType" SG_ 1378 NodeStsTIM_LcFA "ENM";
BA_ "SignalLongName" SG_ 1378 NodeStsTIM_LcFA "Node Status TIM Loss of Communication Fault Active";
BA_ "SignalType" SG_ 1378 NodeStsTCP_LcFA "ENM";
BA_ "SignalLongName" SG_ 1378 NodeStsTCP_LcFA "Node Status TCP Loss of Communication Fault Active";
BA_ "SignalType" SG_ 1378 NodeStsTCM_LcFA "ENM";
BA_ "SignalLongName" SG_ 1378 NodeStsTCM_LcFA "Node Status TCM Loss of Communication Fault Active";
BA_ "SignalType" SG_ 1378 NodeStsTCCM3_LcFA "ENM";
BA_ "SignalLongName" SG_ 1378 NodeStsTCCM3_LcFA "Node Status TCCM3 Loss of Communication Fault Active";
BA_ "SignalType" SG_ 1378 NodeStsTCCM_LcFA "ENM";
BA_ "SignalLongName" SG_ 1378 NodeStsTCCM_LcFA "Node Status TCCM Loss of Communication Fault Active";
BA_ "SignalType" SG_ 1378 NodeStsSTC_LcFA "ENM";
BA_ "SignalLongName" SG_ 1378 NodeStsSTC_LcFA "Node Status STC Loss of Communication Fault Active";
BA_ "SignalType" SG_ 1378 NodeStsSRR_SRR_LcFA "ENM";
BA_ "SignalLongName" SG_ 1378 NodeStsSRR_SRR_LcFA "Node Status SRR_SRR Loss of Communication Fault Active";
BA_ "SignalType" SG_ 1378 NodeStsECP_E_CAN_9_LcFA "ENM";
BA_ "SignalLongName" SG_ 1378 NodeStsECP_E_CAN_9_LcFA "Node Status ECP_E CAN 9 Loss of Communication Fault Active";
BA_ "SignalType" SG_ 1378 NodeStsCMMb_CAN_2_LcFA "ENM";
BA_ "SignalLongName" SG_ 1378 NodeStsCMMb_CAN_2_LcFA "Node Status CMMb CAN 2 Loss of Communication Fault Active";
BA_ "SignalType" SG_ 1378 NodeStsCMMa_CAN_2_LcFA "ENM";
BA_ "SignalLongName" SG_ 1378 NodeStsCMMa_CAN_2_LcFA "Node Status CMMa CAN 2 Loss of Communication Fault Active";
BA_ "SignalType" SG_ 1378 NodeStsARS_LcFA "ENM";
BA_ "SignalLongName" SG_ 1378 NodeStsARS_LcFA "Node Status ARS Loss of Communication Fault Active";
BA_ "SignalType" SG_ 1378 NodeStsVLM_LcFA "ENM";
BA_ "SignalLongName" SG_ 1378 NodeStsVLM_LcFA "Node Status VLM Loss of Communication Fault Active";
BA_ "SignalType" SG_ 1378 NodeStsWCM_LcFA "ENM";
BA_ "SignalLongName" SG_ 1378 NodeStsWCM_LcFA "Node Status WCM Loss of Communication Fault Active";
BA_ "SignalType" SG_ 1378 NodeStsVPM_LcFA "ENM";
BA_ "SignalLongName" SG_ 1378 NodeStsVPM_LcFA "Node Status VPM Loss of Communication Fault Active";
BA_ "SignalType" SG_ 1378 NodeStsVKM_LcFA "ENM";
BA_ "SignalLongName" SG_ 1378 NodeStsVKM_LcFA "Node StatusVKM Loss of Communication Fault Active";
BA_ "SignalType" SG_ 1378 NodeStsECP_E_CAN_2_LcFA "ENM";
BA_ "SignalLongName" SG_ 1378 NodeStsECP_E_CAN_2_LcFA "Node Status ECP_E_CAN_2 Loss of Communication Fault Active";
BA_ "SignalType" SG_ 1441 NodeStsECP_MC_LcFA "ENM";
BA_ "SignalLongName" SG_ 1441 NodeStsECP_MC_LcFA "Node Status ECP_MC Loss of Communication Fault Active";
BA_ "SignalType" SG_ 1441 NodeStsCMMb_CAN_9_LcFA "ENM";
BA_ "SignalLongName" SG_ 1441 NodeStsCMMb_CAN_9_LcFA "Node Status CMMb_CAN_9 Loss of Communication Fault Active";
BA_ "SignalType" SG_ 1441 NodeStsCMMa_CAN_9_LcFA "ENM";
BA_ "SignalLongName" SG_ 1441 NodeStsCMMa_CAN_9_LcFA "Node Status CMMa_CAN_9 Loss of Communication Fault Active";
BA_ "SignalType" SG_ 1441 NodeStsBSM_MH_LcFA "ENM";
BA_ "SignalLongName" SG_ 1441 NodeStsBSM_MH_LcFA "Node Status BSM_MH Loss of Communication Fault Active";
BA_ "SignalType" SG_ 1441 NodeStsSBM_CAN_9_LcFA "ENM";
BA_ "SignalLongName" SG_ 1441 NodeStsSBM_CAN_9_LcFA "Node Status SBM_CAN_9 Loss of Communication Fault Active";
BA_ "SignalType" SG_ 1441 NodeStsSBM_CAN_10_LcFA "ENM";
BA_ "SignalLongName" SG_ 1441 NodeStsSBM_CAN_10_LcFA "Node Status SBM CAN 10 Loss of Communication Fault Active";
BA_ "SignalType" SG_ 1441 NodeStsLIB1_LcFA "ENM";
BA_ "SignalLongName" SG_ 1441 NodeStsLIB1_LcFA "Node Status LIB1 Loss of Communication Fault Active";
BA_ "SignalType" SG_ 1441 NodeStsHDLM_LcFA "ENM";
BA_ "SignalLongName" SG_ 1441 NodeStsHDLM_LcFA "Node Status HDLM Loss of Communication Fault Active";
BA_ "SignalLongName" SG_ 566 PrplStat_PCSM "Propulsion State Protected Counter Sync Message";
BA_ "SignalLongName" SG_ 551 PSP_MAC "Propulsion State Protected : MAC";
BA_ "SignalLongName" SG_ 551 PSP_FCnt "Propulsion State Protected : Freshness Counter";
BA_ "SignalType" SG_ 551 PSP_VehTheftImbChlgRespStsAuth "ENM";
BA_ "SignalLongName" SG_ 551 PSP_VehTheftImbChlgRespStsAuth "Propulsion State Protected : Vehicle Theft Immobilizer Challenge Response Status Authenticated";
BA_ "SignalType" SG_ 551 PSP_RmtVehStrtEngRnngAuth "ENM";
BA_ "SignalLongName" SG_ 551 PSP_RmtVehStrtEngRnngAuth "Propulsion State Protected : Remote Vehicle Start Engine Running Authenticated";
BA_ "SignalType" SG_ 551 PSP_PwrtrnCrnkAbrtdAuth "ENM";
BA_ "SignalLongName" SG_ 551 PSP_PwrtrnCrnkAbrtdAuth "Propulsion State Protected : Powertrain Crank Aborted Authenticated";
BA_ "SignalType" SG_ 551 PSP_PrplSysStlActvAuth "ENM";
BA_ "SignalLongName" SG_ 551 PSP_PrplSysStlActvAuth "Propulsion State Protected : Propulsion System Stall Active Authenticated";
BA_ "SignalType" SG_ 551 PSP_PrplSysActvAuth "ENM";
BA_ "SignalLongName" SG_ 551 PSP_PrplSysActvAuth "Propulsion State Protected : Propulsion System Active Authenticated";
BA_ "SignalType" SG_ 551 PSP_EngRnngAuth "ENM";
BA_ "SignalLongName" SG_ 551 PSP_EngRnngAuth "Propulsion State Protected : Engine Running Authenticated";
BA_ "SignalType" SG_ 551 PSP_ClchBtmTrvlAchvdAuth_Inv "ENM";
BA_ "SignalLongName" SG_ 551 PSP_ClchBtmTrvlAchvdAuth_Inv "Propulsion State Protected : Clutch Bottom of Travel Achieved Authenticated Invalid";
BA_ "SignalType" SG_ 551 PSP_ClchBtmTrvlAchvdAuth "ENM";
BA_ "SignalLongName" SG_ 551 PSP_ClchBtmTrvlAchvdAuth "Propulsion State Protected : Clutch Bottom of Travel Achieved Authenticated";
BA_ "SignalLongName" SG_ 551 PSP_ARC "Propulsion State Protected : Alive Rolling Count";
BA_ "SignalType" SG_ 551 PSP_PrkNeutSwStatAuth_Inv "ENM";
BA_ "SignalLongName" SG_ 551 PSP_PrkNeutSwStatAuth_Inv "Propulsion State Protected : Park Neutral Switch State Authenticated Invalid";
BA_ "SignalType" SG_ 551 PSP_PrkNeutSwStatAuth "ENM";
BA_ "SignalLongName" SG_ 551 PSP_PrkNeutSwStatAuth "Propulsion State Protected : Park Neutral Switch State Authenticated";
BA_ "SignalType" SG_ 1054 RrCrsTrfcBrkgAutoBrkgRelIndOn "ENM";
BA_ "SignalLongName" SG_ 1054 RrCrsTrfcBrkgAutoBrkgRelIndOn "Rear Cross Traffic Braking Autonomous Braking Release Indication On";
BA_ "SignalType" SG_ 140 RrCrsTrfcBrkgAutoBrkgReqdRt "ENM";
BA_ "SignalLongName" SG_ 140 RrCrsTrfcBrkgAutoBrkgReqdRt "Rear Cross Traffic Braking Automatic Braking Requested Right";
BA_ "SignalLongName" SG_ 139 RCTBAD_BrkgCtlAccel "Rear Cross Traffic Braking Automatic Data : Braking Control Acceleration";
BA_ "SignalType" SG_ 139 RCTBAD_BrkgReqd "ENM";
BA_ "SignalLongName" SG_ 139 RCTBAD_BrkgReqd "Rear Cross Traffic Braking Automatic Data : Braking Requested";
BA_ "SignalType" SG_ 139 RCTBAD_BrkgReqTyp "ENM";
BA_ "SignalLongName" SG_ 139 RCTBAD_BrkgReqTyp "Rear Cross Traffic Braking Automatic Data : Braking Request Type";
BA_ "SignalLongName" SG_ 1153 RCTALSHSR_HptcStReqPuls "Rear Cross Traffic Alert Left Side Haptic Seat Request : Haptic Seat Request Pulses";
BA_ "SignalLongName" SG_ 1153 RCTALSHSR_HptcStReqSeqNum "Rear Cross Traffic Alert Left Side Haptic Seat Request : Haptic Seat Request Sequence Number";
BA_ "SignalLongName" SG_ 1154 RCTARSHSR_HptcStReqPuls "Rear Cross Traffic Alert Right Side Haptic Seat Request : Rear Cross Traffic Alert Right Side Haptic Seat Request Pulses";
BA_ "SignalLongName" SG_ 1154 RCTARSHSR_HptcStReqSeqNum "Rear Cross Traffic Alert Right Side Haptic Seat Request : Rear Cross Traffic Alert Right Side Haptic Seat Request Sequence Number";
BA_ "SignalLongName" SG_ 613 LtLnChgThrtAprchSpd "Left Lane Change Threat Approach Speed";
BA_ "SignalType" SG_ 1136 LtFstAprchgVehObjDtd "ENM";
BA_ "SignalLongName" SG_ 1136 LtFstAprchgVehObjDtd "Left Fast Approaching Vehicle Object Detected";
BA_ "SignalLongName" SG_ 614 RtLnChgThrtAprchSpd "Right Lane Change Threat Approach Speed";
BA_ "SignalType" SG_ 1137 RtFstAprchgVehObjDtd "ENM";
BA_ "SignalLongName" SG_ 1137 RtFstAprchgVehObjDtd "Right Fast Approaching Vehicle Object Detected";
BA_ "SignalType" SG_ 1138 RtSdObjDtdAdjTrlr "ENM";
BA_ "SignalLongName" SG_ 1138 RtSdObjDtdAdjTrlr "Right Side Object Detected Adjacent Trailer";
BA_ "SignalLongName" SG_ 1097 SRRLFODP_Brst1_PCSM "Short Range Radar Left Front Object Detection and Processing Burst 1 Protected Counter Sync Message";
BA_ "SignalLongName" SG_ 1796 SRRLRCODPGenInfo1_PCSM "Short Range Radar Left Rear / Center Object Detection and Processing General Information 1 Protected Counter Sync Message";
BA_ "SignalLongName" SG_ 1404 SRRLRCODPGI1P_MAC "Short Range Radar Left Rear / Center Object Detection and Processing General Information 1 Protected : MAC";
BA_ "SignalLongName" SG_ 1404 SRRLRCODPGI1P_FCnt "Short Range Radar Left Rear / Center Object Detection and Processing General Information 1 Protected : Freshness Counter";
BA_ "SignalLongName" SG_ 1404 SRRLRCODPGI1P_ARC "Short Range Radar Left Rear / Center Object Detection and Processing General Information 1 Protected : Alive Rolling Count";
BA_ "SignalType" SG_ 1404 SRRLRCODPGI1P_TrlrDtdAuth "ENM";
BA_ "SignalLongName" SG_ 1404 SRRLRCODPGI1P_TrlrDtdAuth "Short Range Radar Left Rear / Center Object Detection and Processing General Information 1 Protected : Trailer Detected Authenticated";
BA_ "SignalLongName" SG_ 1098 SRRLRCODP_Brst1_PCSM "Short Range Radar Left Rear / Center Object Detection and Processing Burst 1 Protected Counter Sync Message";
BA_ "SignalLongName" SG_ 1099 SRRRFODP_Brst1_PCSM "Short Range Radar Right Front Object Detection and Processing Burst 1 Protected Counter Sync Message";
BA_ "SignalLongName" SG_ 1799 SRRRRODPGenInfo1_PCSM "Short Range Radar Right Rear Object Detection and Processing General Information 1 Protected Counter Sync Message";
BA_ "SignalLongName" SG_ 1430 SRRRRODPGI1P_MAC "Short Range Radar Right Rear Object Detection and Processing General Information 1 Protected : MAC";
BA_ "SignalLongName" SG_ 1430 SRRRRODPGI1P_FCnt "Short Range Radar Right Rear Object Detection and Processing General Information 1 Protected : Freshness Counter";
BA_ "SignalLongName" SG_ 1430 SRRRRODPGI1P_ARC "Short Range Radar Right Rear Object Detection and Processing General Information 1 Protected : Alive Rolling Count";
BA_ "SignalType" SG_ 1430 SRRRRODPGI1P_TrlrDtdAuth "ENM";
BA_ "SignalLongName" SG_ 1430 SRRRRODPGI1P_TrlrDtdAuth "Short Range Radar Right Rear Object Detection and Processing General Information 1 Protected : Trailer Detected Authenticated";
BA_ "SignalLongName" SG_ 1100 SRRRRODP_Brst1_PCSM "Short Range Radar Right Rear Object Detection and Processing Burst 1 Protected Counter Sync Message";
BA_ "SignalLongName" SG_ 1804 SRRSLRODPGenInfo1_PCSM "Short Range Radar Side Left Rear Object Detection and Processing General Information 1 Protected Counter Sync Message";
BA_ "SignalLongName" SG_ 1432 SRRSLRODPGI1P_MAC "Short Range Radar Side Left Rear Object Detection and Processing General Information 1 Protected : MAC";
BA_ "SignalLongName" SG_ 1432 SRRSLRODPGI1P_FCnt "Short Range Radar Side Left Rear Object Detection and Processing General Information 1 Protected : Freshness Counter";
BA_ "SignalLongName" SG_ 1432 SRRSLRODPGI1P_ARC "Short Range Radar Side Left Rear Object Detection and Processing General Information 1 Protected : Alive Rolling Count";
BA_ "SignalType" SG_ 1432 SRRSLRODPGI1P_TrlrDtdAuth "ENM";
BA_ "SignalLongName" SG_ 1432 SRRSLRODPGI1P_TrlrDtdAuth "Short Range Radar Side Left Rear Object Detection and Processing General Information 1 Protected : Trailer Detected Authenticated";
BA_ "SignalLongName" SG_ 1290 SRRSLRODP_Brst1_PCSM "Short Range Radar Side Left Rear Object Detection and Processing Burst 1 Protected Counter Sync Message";
BA_ "SignalLongName" SG_ 1806 SRRSRRODPGenInfo1_PCSM "Short Range Radar Side Right Rear Object Detection and Processing General Information 1 Protected Counter Sync Message";
BA_ "SignalLongName" SG_ 1433 SRRSRRODPGI1P_MAC "Short Range Radar Side Right Rear Object Detection and Processing General Information 1 Protected : MAC";
BA_ "SignalLongName" SG_ 1433 SRRSRRODPGI1P_FCnt "Short Range Radar Side Right Rear Object Detection and Processing General Information 1 Protected : Freshness Counter";
BA_ "SignalLongName" SG_ 1433 SRRSRRODPGI1P_ARC "Short Range Radar Side Right Rear Object Detection and Processing General Information 1 Protected : Alive Rolling Count";
BA_ "SignalType" SG_ 1433 SRRSRRODPGI1P_TrlrDtdAuth "ENM";
BA_ "SignalLongName" SG_ 1433 SRRSRRODPGI1P_TrlrDtdAuth "Short Range Radar Side Right Rear Object Detection and Processing General Information 1 Protected : Trailer Detected Authenticated";
BA_ "SignalLongName" SG_ 1291 SRRSRRODP_Brst1_PCSM "Short Range Radar Side Right Rear Object Detection and Processing Burst 1 Protected Counter Sync Message";
BA_ "SignalType" SG_ 1135 SBZALCACRrActv "ENM";
BA_ "SignalLongName" SG_ 1135 SBZALCACRrActv "Side Blind Zone Alert - Lane Change Alert Center Rear Active";
BA_ "SignalType" SG_ 1135 SBZALCACRrOprtlSts "ENM";
BA_ "SignalLongName" SG_ 1135 SBZALCACRrOprtlSts "Side Blind Zone Alert - Lane Change Alert Center Rear Operational Status";
BA_ "SignalType" SG_ 1135 LtSdObjDtdAdjTrlr "ENM";
BA_ "SignalLongName" SG_ 1135 LtSdObjDtdAdjTrlr "Left Side Object Detected Adjacent Trailer";
BA_ "SignalType" SG_ 1109 SBZALCARRActv "ENM";
BA_ "SignalLongName" SG_ 1109 SBZALCARRActv "Side Blind Zone Alert - Lane Change Alert Right Rear Active";
BA_ "SignalType" SG_ 1109 SBZALCARROprtlSts "ENM";
BA_ "SignalLongName" SG_ 1109 SBZALCARROprtlSts "Side Blind Zone Alert - Lane Change Alert Right Rear Operational Status";
BA_ "SignalType" SG_ 1141 RrCrsTrfcAlrtCstAvlFlg1 "ENM";
BA_ "SignalLongName" SG_ 1141 RrCrsTrfcAlrtCstAvlFlg1 "RearCrossTrafficAlertCustomizationAvailabilityFlag1";
BA_ "SignalType" SG_ 1141 LnChgAlrtCstAvlFlg7 "ENM";
BA_ "SignalLongName" SG_ 1141 LnChgAlrtCstAvlFlg7 "LaneChangeAlertCustomizationAvailabilityFlag7";
BA_ "SignalType" SG_ 1141 LnChgAlrtCstAvlFlg6 "ENM";
BA_ "SignalLongName" SG_ 1141 LnChgAlrtCstAvlFlg6 "LaneChangeAlertCustomizationAvailabilityFlag6";
BA_ "SignalType" SG_ 1141 LnChgAlrtCstAvlFlg5 "ENM";
BA_ "SignalLongName" SG_ 1141 LnChgAlrtCstAvlFlg5 "LaneChangeAlertCustomizationAvailabilityFlag5";
BA_ "SignalType" SG_ 1141 LnChgAlrtCstAvlFlg4 "ENM";
BA_ "SignalLongName" SG_ 1141 LnChgAlrtCstAvlFlg4 "LaneChangeAlertCustomizationAvailabilityFlag4";
BA_ "SignalType" SG_ 1141 LnChgAlrtCstAvlFlg3 "ENM";
BA_ "SignalLongName" SG_ 1141 LnChgAlrtCstAvlFlg3 "LaneChangeAlertCustomizationAvailabilityFlag3";
BA_ "SignalType" SG_ 1141 LnChgAlrtCstAvlFlg2 "ENM";
BA_ "SignalLongName" SG_ 1141 LnChgAlrtCstAvlFlg2 "LaneChangeAlertCustomizationAvailabilityFlag2";
BA_ "SignalType" SG_ 1141 LnChgAlrtCstAvlFlg1 "ENM";
BA_ "SignalLongName" SG_ 1141 LnChgAlrtCstAvlFlg1 "LaneChangeAlertCustomizationAvailabilityFlag1";
BA_ "SignalType" SG_ 1141 RrCrsTrfcAlrtCstAvlFlg7 "ENM";
BA_ "SignalLongName" SG_ 1141 RrCrsTrfcAlrtCstAvlFlg7 "RearCrossTrafficAlertCustomizationAvailabilityFlag7";
BA_ "SignalType" SG_ 1141 RrCrsTrfcAlrtCstAvlFlg6 "ENM";
BA_ "SignalLongName" SG_ 1141 RrCrsTrfcAlrtCstAvlFlg6 "RearCrossTrafficAlertCustomizationAvailabilityFlag6";
BA_ "SignalType" SG_ 1141 RrCrsTrfcAlrtCstAvlFlg5 "ENM";
BA_ "SignalLongName" SG_ 1141 RrCrsTrfcAlrtCstAvlFlg5 "RearCrossTrafficAlertCustomizationAvailabilityFlag5";
BA_ "SignalType" SG_ 1141 RrCrsTrfcAlrtCstAvlFlg4 "ENM";
BA_ "SignalLongName" SG_ 1141 RrCrsTrfcAlrtCstAvlFlg4 "RearCrossTrafficAlertCustomizationAvailabilityFlag4";
BA_ "SignalType" SG_ 1141 RrCrsTrfcAlrtCstAvlFlg3 "ENM";
BA_ "SignalLongName" SG_ 1141 RrCrsTrfcAlrtCstAvlFlg3 "RearCrossTrafficAlertCustomizationAvailabilityFlag3";
BA_ "SignalType" SG_ 1141 RrCrsTrfcAlrtCstAvlFlg2 "ENM";
BA_ "SignalLongName" SG_ 1141 RrCrsTrfcAlrtCstAvlFlg2 "RearCrossTrafficAlertCustomizationAvailabilityFlag2";
BA_ "SignalType" SG_ 1142 RrCrsTrfcAlrtLtSdChmEvntStat "ENM";
BA_ "SignalLongName" SG_ 1142 RrCrsTrfcAlrtLtSdChmEvntStat "Rear Cross Traffic Alert Left Side Chime Event State";
BA_ "SignalType" SG_ 1142 RrCrsTrfcAlrtLftIndCtrl "ENM";
BA_ "SignalLongName" SG_ 1142 RrCrsTrfcAlrtLftIndCtrl "Rear Cross Traffic Alert Left Indication Control";
BA_ "SignalType" SG_ 1144 RrCrsTrfcAutoBrkgOffIndOn "ENM";
BA_ "SignalLongName" SG_ 1144 RrCrsTrfcAutoBrkgOffIndOn "Rear Cross Traffic Auto Braking Off Indication On";
BA_ "SignalType" SG_ 1144 SBZALCAOvrllSts "ENM";
BA_ "SignalLongName" SG_ 1144 SBZALCAOvrllSts "Side Detection Systems SBZA-LCA Overall Status";
BA_ "SignalType" SG_ 1144 RrCrsTrfcAlrtOffIndOn "ENM";
BA_ "SignalLongName" SG_ 1144 RrCrsTrfcAlrtOffIndOn "Rear Cross Traffic Alert System Off Indication On";
BA_ "SignalType" SG_ 1144 RCTAOvrllSts "ENM";
BA_ "SignalLongName" SG_ 1144 RCTAOvrllSts "Side Detection Systems RCTA Overall Status";
BA_ "SignalType" SG_ 1144 LtSdVehObjDtd "ENM";
BA_ "SignalLongName" SG_ 1144 LtSdVehObjDtd "Left Side Vehicle Object Detected";
BA_ "SignalType" SG_ 1145 RrCrsTrfcAlrtCstStAvl "ENM";
BA_ "SignalLongName" SG_ 1145 RrCrsTrfcAlrtCstStAvl "RearCrossTrafficAlertCustomizationSettingAvailable";
BA_ "SignalType" SG_ 1145 LnChgAlrtCstStAvl "ENM";
BA_ "SignalLongName" SG_ 1145 LnChgAlrtCstStAvl "LaneChangeAlertCustomizationSettingAvailable";
BA_ "SignalType" SG_ 1145 RrCrsTrfcAlrtCstCrStVal "ENM";
BA_ "SignalLongName" SG_ 1145 RrCrsTrfcAlrtCstCrStVal "RearCrossTrafficAlertCustomizationCurrentSettingValue";
BA_ "SignalType" SG_ 1145 LnChgAlrtCstCrStVal "ENM";
BA_ "SignalLongName" SG_ 1145 LnChgAlrtCstCrStVal "LaneChangeAlertCustomizationCurrentSettingValue";
BA_ "SignalType" SG_ 1147 RrCrsTrfcAlrtRtSdChmEvntStat "ENM";
BA_ "SignalLongName" SG_ 1147 RrCrsTrfcAlrtRtSdChmEvntStat "Rear Cross Traffic Alert Right Side Chime Event State";
BA_ "SignalType" SG_ 1147 RrCrsTrfcAlrtRgIndCtrl "ENM";
BA_ "SignalLongName" SG_ 1147 RrCrsTrfcAlrtRgIndCtrl "Rear Cross Traffic Alert Right Indication Control";
BA_ "SignalType" SG_ 1149 SBZALCARtSts "ENM";
BA_ "SignalLongName" SG_ 1149 SBZALCARtSts "Side Detection Systems SBZA-LCA Right Status";
BA_ "SignalType" SG_ 1149 RtSdVehObjDtd "ENM";
BA_ "SignalLongName" SG_ 1149 RtSdVehObjDtd "Right Side Vehicle Object Detected";
BA_ "SignalType" SG_ 1149 RCTARtSts "ENM";
BA_ "SignalLongName" SG_ 1149 RCTARtSts "Side Detection Systems RCTA Right Status";
BA_ "SignalType" SG_ 1149 SBZALCAROpStat "ENM";
BA_ "SignalLongName" SG_ 1149 SBZALCAROpStat "DetermineSBZA-LCAROperationalStatus";
BA_ "SignalType" SG_ 1155 SBZALCAOvrllOplSts "ENM";
BA_ "SignalLongName" SG_ 1155 SBZALCAOvrllOplSts "Side Detection Systems SBZA-LCA Overall Operational Status";
BA_ "SignalType" SG_ 1146 SBZAlrtCstAvlFlg1 "ENM";
BA_ "SignalLongName" SG_ 1146 SBZAlrtCstAvlFlg1 "SideBlindZoneAlertCustomizationAvailabilityFlag1";
BA_ "SignalType" SG_ 1146 LnChgAlrtSysOffIndOn "ENM";
BA_ "SignalLongName" SG_ 1146 LnChgAlrtSysOffIndOn "Lane Change Alert System Off Indication On";
BA_ "SignalType" SG_ 1146 LnChgAlrtLmtdTrlrIndOn "ENM";
BA_ "SignalLongName" SG_ 1146 LnChgAlrtLmtdTrlrIndOn "Lane Change Alert Limited by Trailer Indication On";
BA_ "SignalType" SG_ 1146 SBZALCAVisIndStatLt "ENM";
BA_ "SignalLongName" SG_ 1146 SBZALCAVisIndStatLt "SBZA - LCA Visual Indication State Left";
BA_ "SignalType" SG_ 1146 SBZAlrtCstCrStVal "ENM";
BA_ "SignalLongName" SG_ 1146 SBZAlrtCstCrStVal "SideBlindZoneAlertCustomizationCurrentSettingValue";
BA_ "SignalType" SG_ 1146 SBZAlrtOffIndOn "ENM";
BA_ "SignalLongName" SG_ 1146 SBZAlrtOffIndOn "Side Blind Zone Alert Off Indication On";
BA_ "SignalType" SG_ 1146 SBZAlrtCstStAvl "ENM";
BA_ "SignalLongName" SG_ 1146 SBZAlrtCstStAvl "SideBlindZoneAlertCustomizationSettingAvailable";
BA_ "SignalType" SG_ 1146 SBZAlrtCstAvlFlg7 "ENM";
BA_ "SignalLongName" SG_ 1146 SBZAlrtCstAvlFlg7 "SideBlindZoneAlertCustomizationAvailabilityFlag7";
BA_ "SignalType" SG_ 1146 SBZAlrtCstAvlFlg6 "ENM";
BA_ "SignalLongName" SG_ 1146 SBZAlrtCstAvlFlg6 "SideBlindZoneAlertCustomizationAvailabilityFlag6";
BA_ "SignalType" SG_ 1146 SBZAlrtCstAvlFlg5 "ENM";
BA_ "SignalLongName" SG_ 1146 SBZAlrtCstAvlFlg5 "SideBlindZoneAlertCustomizationAvailabilityFlag5";
BA_ "SignalType" SG_ 1146 SBZAlrtCstAvlFlg4 "ENM";
BA_ "SignalLongName" SG_ 1146 SBZAlrtCstAvlFlg4 "SideBlindZoneAlertCustomizationAvailabilityFlag4";
BA_ "SignalType" SG_ 1146 SBZAlrtCstAvlFlg3 "ENM";
BA_ "SignalLongName" SG_ 1146 SBZAlrtCstAvlFlg3 "SideBlindZoneAlertCustomizationAvailabilityFlag3";
BA_ "SignalType" SG_ 1146 SBZAlrtCstAvlFlg2 "ENM";
BA_ "SignalLongName" SG_ 1146 SBZAlrtCstAvlFlg2 "SideBlindZoneAlertCustomizationAvailabilityFlag2";
BA_ "SignalType" SG_ 1146 ServSdDtcSysIndOn "ENM";
BA_ "SignalLongName" SG_ 1146 ServSdDtcSysIndOn "Service Side Detection System Indication On";
BA_ "SignalType" SG_ 1146 SdDtcTempUnvIndOn "ENM";
BA_ "SignalLongName" SG_ 1146 SdDtcTempUnvIndOn "Side Detection Temporarily Unavailable Indication On";
BA_ "SignalType" SG_ 1150 SBZALCAVisIndStatRt "ENM";
BA_ "SignalLongName" SG_ 1150 SBZALCAVisIndStatRt "SBZA - LCA Visual Indication State Right";
BA_ "SignalLongName" SG_ 1073 SpdLimVsnFsdSpd_PCSM "Speed Limit Vision Fused Speed Protected Counter Sync Message";
BA_ "SignalLongName" SG_ 1068 SLVFSP_MAC "Speed Limit Vision Fused Speed Protected : MAC";
BA_ "SignalLongName" SG_ 1068 SLVFSP_FCnt "Speed Limit Vision Fused Speed Protected : Freshness Counter";
BA_ "SignalLongName" SG_ 1068 SLVFSP_SpdLimVsnFsdSpdAuth "Speed Limit Vision Fused Speed Protected : Speed Limit Vision Fused Speed Authenticated";
BA_ "SignalType" SG_ 1068 SLVFSP_SpdLimVsnFsdSpdUntAuth "ENM";
BA_ "SignalLongName" SG_ 1068 SLVFSP_SpdLimVsnFsdSpdUntAuth "Speed Limit Vision Fused Speed Protected : Speed Limit Vision Fused Speed Unit Authenticated";
BA_ "SignalType" SG_ 1068 SLVFSP_SpdLimVsnFsdSpdNwDtdAuth "ENM";
BA_ "SignalLongName" SG_ 1068 SLVFSP_SpdLimVsnFsdSpdNwDtdAuth "Speed Limit Vision Fused Speed Protected : Speed Limit Vision Fused Speed New Detected Authenticated";
BA_ "SignalType" SG_ 1068 SLVFSP_SpdLimVsnFsdSpdAuth_DuD "ENM";
BA_ "SignalLongName" SG_ 1068 SLVFSP_SpdLimVsnFsdSpdAuth_DuD "Speed Limit Vision Fused Speed Protected : Speed Limit Vision Fused Speed Authenticated Don't Use Data";
BA_ "SignalLongName" SG_ 1068 SLVFSP_ARC "Speed Limit Vision Fused Speed Protected : Alive Rolling Count";
BA_ "SignalLongName" SG_ 1842 SpnsnGenInfo2_PCSM "Suspension General Information 2 Protected Counter Sync Message";
BA_ "SignalLongName" SG_ 1393 SGI2P_MAC "Suspension General Information 2 Protected : MAC";
BA_ "SignalLongName" SG_ 1393 SGI2P_FCnt "Suspension General Information 2 Protected : Freshness Counter";
BA_ "SignalType" SG_ 1393 SGI2P_AirSpnsnRdHghtLwrActnAuth "ENM";
BA_ "SignalLongName" SG_ 1393 SGI2P_AirSpnsnRdHghtLwrActnAuth "Suspension General Information 2 Protected : Air Suspension Ride Height Lower Action Authenticated";
BA_ "SignalType" SG_ 1393 SGI2P_AirSpnsnRdHghtActvAxlAuth "ENM";
BA_ "SignalLongName" SG_ 1393 SGI2P_AirSpnsnRdHghtActvAxlAuth "Suspension General Information 2 Protected : Air Suspension Ride Height Active Axle Authenticated";
BA_ "SignalType" SG_ 1393 SGI2P_AirSpnsnRdHghtActlStsAuth "ENM";
BA_ "SignalLongName" SG_ 1393 SGI2P_AirSpnsnRdHghtActlStsAuth "Suspension General Information 2 Protected : Air Suspension Ride Height Actual Status Authenticated";
BA_ "SignalLongName" SG_ 1393 SGI2P_ARC "Suspension General Information 2 Protected : Alive Rolling Count";
BA_ "SignalType" SG_ 1393 SGI2P_AirSpnsnRdHghtTgtStsAuth "ENM";
BA_ "SignalLongName" SG_ 1393 SGI2P_AirSpnsnRdHghtTgtStsAuth "Suspension General Information 2 Protected : Air Suspension Ride Height Target Status Authenticated";
BA_ "SignalType" SG_ 1393 SGI2P_AirSpnsnRdHghtRseActnAuth "ENM";
BA_ "SignalLongName" SG_ 1393 SGI2P_AirSpnsnRdHghtRseActnAuth "Suspension General Information 2 Protected : Air Suspension Ride Height Raise Action Authenticated";
BA_ "SignalLongName" SG_ 522 SysPwrMode_PCSM "System Power Mode Protected Counter Sync Message";
BA_ "SignalLongName" SG_ 644 SPMP_MAC "System Power Mode Protected : MAC";
BA_ "SignalLongName" SG_ 644 SPMP_FCnt "System Power Mode Protected : Freshness Counter";
BA_ "SignalLongName" SG_ 644 SPMP_ARC "System Power Mode Protected : Alive Rolling Count";
BA_ "SignalType" SG_ 644 SPMP_SysPwrModeAuth_Inv "ENM";
BA_ "SignalLongName" SG_ 644 SPMP_SysPwrModeAuth_Inv "System Power Mode Protected : System Power Mode Authenticated Invalid";
BA_ "SignalType" SG_ 644 SPMP_SysPwrModeAuth "ENM";
BA_ "SignalLongName" SG_ 644 SPMP_SysPwrModeAuth "System Power Mode Protected : System Power Mode Authenticated";
BA_ "SignalType" SG_ 644 SPMP_PriRunCrnkCmdActvAuth_Inv "ENM";
BA_ "SignalLongName" SG_ 644 SPMP_PriRunCrnkCmdActvAuth_Inv "System Power Mode Protected : Primary Run Crank Command Active Authenticated Invalid";
BA_ "SignalType" SG_ 644 SPMP_PriRunCrnkCmdActvAuth "ENM";
BA_ "SignalLongName" SG_ 644 SPMP_PriRunCrnkCmdActvAuth "System Power Mode Protected : Primary Run Crank Command Active Authenticated";
BA_ "SignalLongName" SG_ 644 SPMP_PV "System Power Mode Protected : Protection Value";
BA_ "SignalLongName" SG_ 568 TrnsEstGr_PCSM "Transmission Estimated Gear Protected Counter Sync Message";
BA_ "SignalLongName" SG_ 49 TEGP_MAC "Transmission Estimated Gear Protected : MAC";
BA_ "SignalLongName" SG_ 49 TEGP_FCnt "Transmission Estimated Gear Protected : Freshness Counter";
BA_ "SignalType" SG_ 49 TEGP_TrnsEstGrAuth "ENM";
BA_ "SignalLongName" SG_ 49 TEGP_TrnsEstGrAuth "Transmission Estimated Gear Protected : Transmission Estimated Gear Authenticated";
BA_ "SignalType" SG_ 49 TEGP_TransCmndGrAuth "ENM";
BA_ "SignalLongName" SG_ 49 TEGP_TransCmndGrAuth "Transmission Estimated Gear Protected : Transmission Commanded Gear Authenticated";
BA_ "SignalType" SG_ 49 TEGP_TrnsEngdStAuth_Inv "ENM";
BA_ "SignalLongName" SG_ 49 TEGP_TrnsEngdStAuth_Inv "Transmission Estimated Gear Protected : Transmission Engaged State Authenticated Invalid";
BA_ "SignalType" SG_ 49 TEGP_TrnsShftLvrPstnAuth "ENM";
BA_ "SignalLongName" SG_ 49 TEGP_TrnsShftLvrPstnAuth "Transmission Estimated Gear Protected : Transmission Shift Lever Position Authenticated";
BA_ "SignalLongName" SG_ 49 TEGP_ARC "Transmission Estimated Gear Protected : Alive Rolling Count";
BA_ "SignalType" SG_ 49 TEGP_TrnsEngdStAuth "ENM";
BA_ "SignalLongName" SG_ 49 TEGP_TrnsEngdStAuth "Transmission Estimated Gear Protected : Transmission Engaged State Authenticated";
BA_ "SignalType" SG_ 49 TEGP_TrnsEstGrAuth_Inv "ENM";
BA_ "SignalLongName" SG_ 49 TEGP_TrnsEstGrAuth_Inv "Transmission Estimated Gear Protected : Transmission Estimated Gear Authenticated Invalid";
BA_ "SignalType" SG_ 49 TEGP_TrnsShftLvrPstnAuth_Inv "ENM";
BA_ "SignalLongName" SG_ 49 TEGP_TrnsShftLvrPstnAuth_Inv "Transmission Estimated Gear Protected : Transmission Shift Lever Position Authenticated Invalid";
BA_ "SignalLongName" SG_ 1157 VehIdNmDig10_17 "Vehicle Identification Number Digits 10-17";
BA_ "SignalLongName" SG_ 1156 VehIdNmDig2_9 "Vehicle Identification Number Digits 2-9";
BA_ "SignalLongName" SG_ 570 VehMtnInfo1_PCSM "Vehicle Motion Information 1 Protected Counter Sync Message";
BA_ "SignalLongName" SG_ 135 VMI1P_MAC "Vehicle Motion Information 1 Protected : MAC";
BA_ "SignalLongName" SG_ 135 VMI1P_FCnt "Vehicle Motion Information 1 Protected : Freshness Counter";
BA_ "SignalLongName" SG_ 135 VMI1P_VehTopSpdLimArbdValAuth "Vehicle Motion Information 1 Protected : Vehicle Top Speed Limit Arbitrated Value Authenticated";
BA_ "SignalType" SG_ 135 VMI1P_AccelPedOvrrdActvAuth "ENM";
BA_ "SignalLongName" SG_ 135 VMI1P_AccelPedOvrrdActvAuth "Vehicle Motion Information 1 Protected : Accelerator Pedal Override Active Authenticated";
BA_ "SignalType" SG_ 135 VMI1P_VehTopSpdLimModeActvAuth "ENM";
BA_ "SignalLongName" SG_ 135 VMI1P_VehTopSpdLimModeActvAuth "Vehicle Motion Information 1 Protected : Vehicle Top Speed Limit Mode Active Authenticated";
BA_ "SignalLongName" SG_ 135 VMI1P_AccelActlPstnAuth "Vehicle Motion Information 1 Protected : Accelerator Actual Position Authenticated";
BA_ "SignalType" SG_ 135 VMI1P_AccelActlPstnAuth_Inv "ENM";
BA_ "SignalLongName" SG_ 135 VMI1P_AccelActlPstnAuth_Inv "Vehicle Motion Information 1 Protected : Accelerator Actual Position Authenticated Invalid";
BA_ "SignalLongName" SG_ 135 VMI1P_ARC "Vehicle Motion Information 1 Protected : Alive Rolling Count";
BA_ "SignalLongName" SG_ 1807 VehSpdAvgDrvn_PCSM "Vehicle Speed Average Driven Protected Counter Sync Message";
BA_ "SignalLongName" SG_ 553 VSADP_MAC "Vehicle Speed Average Driven Protected : MAC";
BA_ "SignalLongName" SG_ 553 VSADP_FCnt "Vehicle Speed Average Driven Protected : Freshness Counter";
BA_ "SignalLongName" SG_ 553 VSADP_VehSpdAvgDrvnAuth "Vehicle Speed Average Driven Protected : Vehicle Speed Average Driven Authenticated";
BA_ "SignalType" SG_ 553 VSADP_VehSpdAvgDrvnAuth_Inv "ENM";
BA_ "SignalLongName" SG_ 553 VSADP_VehSpdAvgDrvnAuth_Inv "Vehicle Speed Average Driven Protected : Vehicle Speed Average Driven Authenticated Invalid";
BA_ "SignalLongName" SG_ 553 VSADP_ARC "Vehicle Speed Average Driven Protected : Alive Rolling Count";
BA_ "SignalType" SG_ 553 VSADP_FuelModeStsAuth "ENM";
BA_ "SignalLongName" SG_ 553 VSADP_FuelModeStsAuth "Vehicle Speed Average Driven Protected : Fuel Mode Status Authenticated";
BA_ "SignalType" SG_ 553 VSADP_RdcdPwrIndOnAuth "ENM";
BA_ "SignalLongName" SG_ 553 VSADP_RdcdPwrIndOnAuth "Vehicle Speed Average Driven Protected : Reduced Power Indication On Authenticated";
BA_ "SignalType" SG_ 553 VSADP_VehSpdAvgDrvnSrcAuth "ENM";
BA_ "SignalLongName" SG_ 553 VSADP_VehSpdAvgDrvnSrcAuth "Vehicle Speed Average Driven Protected : Vehicle Speed Average Driven Source Authenticated";
VAL_ 1066 DTCI_EOCM_HCP2_CnfrmdDTC 0 "FALSE" 1 "TRUE" ;
VAL_ 1066 DTCI_EOCM_HCP2_DTCFaultType 0 "Not Supported" 1 "Type A" 2 "Type B" 3 "Type C" ;
VAL_ 1066 DTCI_EOCM_HCP2_TstNCmpltdOpCyc 0 "FALSE" 1 "TRUE" ;
VAL_ 1066 DTCI_EOCM_HCP2_TstNCmpltdLstClr 0 "FALSE" 1 "TRUE" ;
VAL_ 1066 DTCI_EOCM_HCP2_TstFldOpCyc 0 "FALSE" 1 "TRUE" ;
VAL_ 1066 DTCI_EOCM_HCP2_TstFldLstClr 0 "FALSE" 1 "TRUE" ;
VAL_ 1066 DTCI_EOCM_HCP2_TstFld 0 "FALSE" 1 "TRUE" ;
VAL_ 1066 DTCI_EOCM_HCP2_PndngDTC 0 "FALSE" 1 "TRUE" ;
VAL_ 1066 DTCI_EOCM_HCP2_DTCTriggered 0 "FALSE" 1 "TRUE" ;
VAL_ 1066 DTCI_EOCM_HCP2_WrnIndTrggrd 0 "FALSE" 1 "TRUE" ;
VAL_ 1066 DTCI_EOCM_HCP2_WrnIndRqd 0 "FALSE" 1 "TRUE" ;
VAL_ 1123 DTCI_FCM_LC_CnfrmdDTC 0 "FALSE" 1 "TRUE" ;
VAL_ 1123 DTCI_FCM_LC_DTCFaultType 0 "Not Supported" 1 "Type A" 2 "Type B" 3 "Type C" ;
VAL_ 1123 DTCI_FCM_LC_TstNCmpltdOpCyc 0 "FALSE" 1 "TRUE" ;
VAL_ 1123 DTCI_FCM_LC_TstNCmpltdLstClr 0 "FALSE" 1 "TRUE" ;
VAL_ 1123 DTCI_FCM_LC_TstFldOpCyc 0 "FALSE" 1 "TRUE" ;
VAL_ 1123 DTCI_FCM_LC_TstFldLstClr 0 "FALSE" 1 "TRUE" ;
VAL_ 1123 DTCI_FCM_LC_TstFld 0 "FALSE" 1 "TRUE" ;
VAL_ 1123 DTCI_FCM_LC_PndngDTC 0 "FALSE" 1 "TRUE" ;
VAL_ 1123 DTCI_FCM_LC_DTCTriggered 0 "FALSE" 1 "TRUE" ;
VAL_ 1123 DTCI_FCM_LC_WrnIndTrggrd 0 "FALSE" 1 "TRUE" ;
VAL_ 1123 DTCI_FCM_LC_WrnIndRqd 0 "FALSE" 1 "TRUE" ;
VAL_ 1043 DTCI_HDLM_CnfrmdDTC 0 "FALSE" 1 "TRUE" ;
VAL_ 1043 DTCI_HDLM_DTCFaultType 0 "Not Supported" 1 "Type A" 2 "Type B" 3 "Type C" ;
VAL_ 1043 DTCI_HDLM_TstNCmpltdOpCyc 0 "FALSE" 1 "TRUE" ;
VAL_ 1043 DTCI_HDLM_TstNCmpltdLstClr 0 "FALSE" 1 "TRUE" ;
VAL_ 1043 DTCI_HDLM_TstFldOpCyc 0 "FALSE" 1 "TRUE" ;
VAL_ 1043 DTCI_HDLM_TstFldLstClr 0 "FALSE" 1 "TRUE" ;
VAL_ 1043 DTCI_HDLM_TstFld 0 "FALSE" 1 "TRUE" ;
VAL_ 1043 DTCI_HDLM_PndngDTC 0 "FALSE" 1 "TRUE" ;
VAL_ 1043 DTCI_HDLM_DTCTriggered 0 "FALSE" 1 "TRUE" ;
VAL_ 1043 DTCI_HDLM_WrnIndTrggrd 0 "FALSE" 1 "TRUE" ;
VAL_ 1043 DTCI_HDLM_WrnIndRqd 0 "FALSE" 1 "TRUE" ;
VAL_ 1106 DTCI_LRR_HC_CnfrmdDTC 0 "FALSE" 1 "TRUE" ;
VAL_ 1106 DTCI_LRR_HC_DTCFaultType 0 "Not Supported" 1 "Type A" 2 "Type B" 3 "Type C" ;
VAL_ 1106 DTCI_LRR_HC_TstNCmpltdOpCyc 0 "FALSE" 1 "TRUE" ;
VAL_ 1106 DTCI_LRR_HC_TstNCmpltdLstClr 0 "FALSE" 1 "TRUE" ;
VAL_ 1106 DTCI_LRR_HC_TstFldOpCyc 0 "FALSE" 1 "TRUE" ;
VAL_ 1106 DTCI_LRR_HC_TstFldLstClr 0 "FALSE" 1 "TRUE" ;
VAL_ 1106 DTCI_LRR_HC_TstFld 0 "FALSE" 1 "TRUE" ;
VAL_ 1106 DTCI_LRR_HC_PndngDTC 0 "FALSE" 1 "TRUE" ;
VAL_ 1106 DTCI_LRR_HC_DTCTriggered 0 "FALSE" 1 "TRUE" ;
VAL_ 1106 DTCI_LRR_HC_WrnIndTrggrd 0 "FALSE" 1 "TRUE" ;
VAL_ 1106 DTCI_LRR_HC_WrnIndRqd 0 "FALSE" 1 "TRUE" ;
VAL_ 1132 DTCI_LRR_CnfrmdDTC 0 "FALSE" 1 "TRUE" ;
VAL_ 1132 DTCI_LRR_DTCFaultType 0 "Not Supported" 1 "Type A" 2 "Type B" 3 "Type C" ;
VAL_ 1132 DTCI_LRR_TstNCmpltdOpCyc 0 "FALSE" 1 "TRUE" ;
VAL_ 1132 DTCI_LRR_TstNCmpltdLstClr 0 "FALSE" 1 "TRUE" ;
VAL_ 1132 DTCI_LRR_TstFldOpCyc 0 "FALSE" 1 "TRUE" ;
VAL_ 1132 DTCI_LRR_TstFldLstClr 0 "FALSE" 1 "TRUE" ;
VAL_ 1132 DTCI_LRR_TstFld 0 "FALSE" 1 "TRUE" ;
VAL_ 1132 DTCI_LRR_PndngDTC 0 "FALSE" 1 "TRUE" ;
VAL_ 1132 DTCI_LRR_DTCTriggered 0 "FALSE" 1 "TRUE" ;
VAL_ 1132 DTCI_LRR_WrnIndTrggrd 0 "FALSE" 1 "TRUE" ;
VAL_ 1132 DTCI_LRR_WrnIndRqd 0 "FALSE" 1 "TRUE" ;
VAL_ 1133 DTCI_SRR_LF_CnfrmdDTC 0 "FALSE" 1 "TRUE" ;
VAL_ 1133 DTCI_SRR_LF_DTCFaultType 0 "Not Supported" 1 "Type A" 2 "Type B" 3 "Type C" ;
VAL_ 1133 DTCI_SRR_LF_TstNCmpltdOpCyc 0 "FALSE" 1 "TRUE" ;
VAL_ 1133 DTCI_SRR_LF_TstNCmpltdLstClr 0 "FALSE" 1 "TRUE" ;
VAL_ 1133 DTCI_SRR_LF_TstFldOpCyc 0 "FALSE" 1 "TRUE" ;
VAL_ 1133 DTCI_SRR_LF_TstFldLstClr 0 "FALSE" 1 "TRUE" ;
VAL_ 1133 DTCI_SRR_LF_TstFld 0 "FALSE" 1 "TRUE" ;
VAL_ 1133 DTCI_SRR_LF_PndngDTC 0 "FALSE" 1 "TRUE" ;
VAL_ 1133 DTCI_SRR_LF_DTCTriggered 0 "FALSE" 1 "TRUE" ;
VAL_ 1133 DTCI_SRR_LF_WrnIndTrggrd 0 "FALSE" 1 "TRUE" ;
VAL_ 1133 DTCI_SRR_LF_WrnIndRqd 0 "FALSE" 1 "TRUE" ;
VAL_ 1134 DTCI_SRR_LR_CR_CnfrmdDTC 0 "FALSE" 1 "TRUE" ;
VAL_ 1134 DTCI_SRR_LR_CR_DTCFaultType 0 "Not Supported" 1 "Type A" 2 "Type B" 3 "Type C" ;
VAL_ 1134 DTCI_SRR_LR_CR_TstNCmpltdOpCyc 0 "FALSE" 1 "TRUE" ;
VAL_ 1134 DTCI_SRR_LR_CR_TstNCmpltdLstClr 0 "FALSE" 1 "TRUE" ;
VAL_ 1134 DTCI_SRR_LR_CR_TstFldOpCyc 0 "FALSE" 1 "TRUE" ;
VAL_ 1134 DTCI_SRR_LR_CR_TstFldLstClr 0 "FALSE" 1 "TRUE" ;
VAL_ 1134 DTCI_SRR_LR_CR_TstFld 0 "FALSE" 1 "TRUE" ;
VAL_ 1134 DTCI_SRR_LR_CR_PndngDTC 0 "FALSE" 1 "TRUE" ;
VAL_ 1134 DTCI_SRR_LR_CR_DTCTriggered 0 "FALSE" 1 "TRUE" ;
VAL_ 1134 DTCI_SRR_LR_CR_WrnIndTrggrd 0 "FALSE" 1 "TRUE" ;
VAL_ 1134 DTCI_SRR_LR_CR_WrnIndRqd 0 "FALSE" 1 "TRUE" ;
VAL_ 1139 DTCI_SRR_RF_CnfrmdDTC 0 "FALSE" 1 "TRUE" ;
VAL_ 1139 DTCI_SRR_RF_DTCFaultType 0 "Not Supported" 1 "Type A" 2 "Type B" 3 "Type C" ;
VAL_ 1139 DTCI_SRR_RF_TstNCmpltdOpCyc 0 "FALSE" 1 "TRUE" ;
VAL_ 1139 DTCI_SRR_RF_TstNCmpltdLstClr 0 "FALSE" 1 "TRUE" ;
VAL_ 1139 DTCI_SRR_RF_TstFldOpCyc 0 "FALSE" 1 "TRUE" ;
VAL_ 1139 DTCI_SRR_RF_TstFldLstClr 0 "FALSE" 1 "TRUE" ;
VAL_ 1139 DTCI_SRR_RF_TstFld 0 "FALSE" 1 "TRUE" ;
VAL_ 1139 DTCI_SRR_RF_PndngDTC 0 "FALSE" 1 "TRUE" ;
VAL_ 1139 DTCI_SRR_RF_DTCTriggered 0 "FALSE" 1 "TRUE" ;
VAL_ 1139 DTCI_SRR_RF_WrnIndTrggrd 0 "FALSE" 1 "TRUE" ;
VAL_ 1139 DTCI_SRR_RF_WrnIndRqd 0 "FALSE" 1 "TRUE" ;
VAL_ 1140 DTCI_SRR_RR_CnfrmdDTC 0 "FALSE" 1 "TRUE" ;
VAL_ 1140 DTCI_SRR_RR_DTCFaultType 0 "Not Supported" 1 "Type A" 2 "Type B" 3 "Type C" ;
VAL_ 1140 DTCI_SRR_RR_TstNCmpltdOpCyc 0 "FALSE" 1 "TRUE" ;
VAL_ 1140 DTCI_SRR_RR_TstNCmpltdLstClr 0 "FALSE" 1 "TRUE" ;
VAL_ 1140 DTCI_SRR_RR_TstFldOpCyc 0 "FALSE" 1 "TRUE" ;
VAL_ 1140 DTCI_SRR_RR_TstFldLstClr 0 "FALSE" 1 "TRUE" ;
VAL_ 1140 DTCI_SRR_RR_TstFld 0 "FALSE" 1 "TRUE" ;
VAL_ 1140 DTCI_SRR_RR_PndngDTC 0 "FALSE" 1 "TRUE" ;
VAL_ 1140 DTCI_SRR_RR_DTCTriggered 0 "FALSE" 1 "TRUE" ;
VAL_ 1140 DTCI_SRR_RR_WrnIndTrggrd 0 "FALSE" 1 "TRUE" ;
VAL_ 1140 DTCI_SRR_RR_WrnIndRqd 0 "FALSE" 1 "TRUE" ;
VAL_ 1110 DTCI_SRR_SLR_CnfrmdDTC 0 "FALSE" 1 "TRUE" ;
VAL_ 1110 DTCI_SRR_SLR_DTCFaultType 0 "Not Supported" 1 "Type A" 2 "Type B" 3 "Type C" ;
VAL_ 1110 DTCI_SRR_SLR_TstNCmpltdOpCyc 0 "FALSE" 1 "TRUE" ;
VAL_ 1110 DTCI_SRR_SLR_TstNCmpltdLstClr 0 "FALSE" 1 "TRUE" ;
VAL_ 1110 DTCI_SRR_SLR_TstFldOpCyc 0 "FALSE" 1 "TRUE" ;
VAL_ 1110 DTCI_SRR_SLR_TstFldLstClr 0 "FALSE" 1 "TRUE" ;
VAL_ 1110 DTCI_SRR_SLR_TstFld 0 "FALSE" 1 "TRUE" ;
VAL_ 1110 DTCI_SRR_SLR_PndngDTC 0 "FALSE" 1 "TRUE" ;
VAL_ 1110 DTCI_SRR_SLR_DTCTriggered 0 "FALSE" 1 "TRUE" ;
VAL_ 1110 DTCI_SRR_SLR_WrnIndTrggrd 0 "FALSE" 1 "TRUE" ;
VAL_ 1110 DTCI_SRR_SLR_WrnIndRqd 0 "FALSE" 1 "TRUE" ;
VAL_ 1111 DTCI_SRR_SRR_CnfrmdDTC 0 "FALSE" 1 "TRUE" ;
VAL_ 1111 DTCI_SRR_SRR_DTCFaultType 0 "Not Supported" 1 "Type A" 2 "Type B" 3 "Type C" ;
VAL_ 1111 DTCI_SRR_SRR_TstNCmpltdOpCyc 0 "FALSE" 1 "TRUE" ;
VAL_ 1111 DTCI_SRR_SRR_TstNCmpltdLstClr 0 "FALSE" 1 "TRUE" ;
VAL_ 1111 DTCI_SRR_SRR_TstFldOpCyc 0 "FALSE" 1 "TRUE" ;
VAL_ 1111 DTCI_SRR_SRR_TstFldLstClr 0 "FALSE" 1 "TRUE" ;
VAL_ 1111 DTCI_SRR_SRR_TstFld 0 "FALSE" 1 "TRUE" ;
VAL_ 1111 DTCI_SRR_SRR_PndngDTC 0 "FALSE" 1 "TRUE" ;
VAL_ 1111 DTCI_SRR_SRR_DTCTriggered 0 "FALSE" 1 "TRUE" ;
VAL_ 1111 DTCI_SRR_SRR_WrnIndTrggrd 0 "FALSE" 1 "TRUE" ;
VAL_ 1111 DTCI_SRR_SRR_WrnIndRqd 0 "FALSE" 1 "TRUE" ;
VAL_ 1122 ACCAutoStSpStat 0 "No_Set_Speed_Change" 1 "Proposed_Speed_Limit_Change" 2 "Accepted_Speed_Limit_Change" 3 "Declined_Speed_Limit_Change" ;
VAL_ 178 ACCBRP_ACCActvAuth 0 "FALSE" 1 "TRUE" ;
VAL_ 1108 LnDprtrWrnCtlSdThrtRtMirIndReq 0 "Off" 1 "Solid" 2 "Flashing" 3 "No Action" ;
VAL_ 1108 LnDprtrWrnCtlSdThrtLtMirIndReq 0 "Off" 1 "Solid" 2 "Flashing" 3 "No Action" ;
VAL_ 1045 EPBSP_ElecPrkBrkApplStsAuth 0 "Unknown" 1 "Applied" 2 "Released" 3 "Dynamic Apply" 4 "In-Progress" ;
VAL_ 1124 TrffcLgtAsstCstAvlFlg1 0 "FALSE" 1 "TRUE" ;
VAL_ 1124 GlrFrHgBmRspTypCstAvlFlg7 0 "FALSE" 1 "TRUE" ;
VAL_ 1124 GlrFrHgBmRspTypCstAvlFlg6 0 "FALSE" 1 "TRUE" ;
VAL_ 1124 GlrFrHgBmRspTypCstAvlFlg5 0 "FALSE" 1 "TRUE" ;
VAL_ 1124 GlrFrHgBmRspTypCstAvlFlg4 0 "FALSE" 1 "TRUE" ;
VAL_ 1124 GlrFrHgBmRspTypCstAvlFlg3 0 "FALSE" 1 "TRUE" ;
VAL_ 1124 GlrFrHgBmRspTypCstAvlFlg2 0 "FALSE" 1 "TRUE" ;
VAL_ 1124 GlrFrHgBmRspTypCstAvlFlg1 0 "FALSE" 1 "TRUE" ;
VAL_ 1124 TrffcLgtAsstCstAvlFlg7 0 "FALSE" 1 "TRUE" ;
VAL_ 1124 TrffcLgtAsstCstAvlFlg6 0 "FALSE" 1 "TRUE" ;
VAL_ 1124 TrffcLgtAsstCstAvlFlg5 0 "FALSE" 1 "TRUE" ;
VAL_ 1124 TrffcLgtAsstCstAvlFlg4 0 "FALSE" 1 "TRUE" ;
VAL_ 1124 TrffcLgtAsstCstAvlFlg3 0 "FALSE" 1 "TRUE" ;
VAL_ 1124 TrffcLgtAsstCstAvlFlg2 0 "FALSE" 1 "TRUE" ;
VAL_ 1126 TrffcLgtAsstWrnChmEvntStat 0 "NO_ACTION" 1 "ACTIVE" 2 "CANCEL_CHIME" 3 "RESERVED_1" ;
VAL_ 1129 AutoHgBmCtrlIO 0 "FALSE" 1 "TRUE" ;
VAL_ 1131 TrffcLgtAsstCstSetAval 0 "FALSE" 1 "TRUE" ;
VAL_ 1131 GlrFrHgBmRspTypCstStAvl 0 "FALSE" 1 "TRUE" ;
VAL_ 1131 TrffcLgtAsstCstCurrSetVal 0 "SETTING_UNKNOWN" 1 "OFF" 2 "ALERT" 3 "RESERVED_3" 4 "RESERVED_4" 5 "RESERVED_5" 6 "RESERVED_6" 7 "RESERVED_7" ;
VAL_ 1131 GlrFrHgBmRspTypCstCurSetVal 0 "SETTING_UNKNOWN" 1 "AUTOMATIC_HIGH_BEAM" 2 "GLARE_FREE_HIGH_BEAM" 3 "RESERVED_3" 4 "\?? RESERVED_4" 5 "RESERVED_5" 6 "RESERVED_6" 7 "RESERVED_7" ;
VAL_ 17 FsdLoclzdRdTyp 0 "Unknown" 1 "Limited Access Road" 2 "Not Limited Access Road" ;
VAL_ 518 GPSC_PPSLat_Inv 0 "FALSE" 1 "TRUE" ;
VAL_ 518 GPSC_PPSLong_Inv 0 "FALSE" 1 "TRUE" ;
VAL_ 1128 TSMEurDispSgn2Mn 0 "UnKnown" 1 "No Sign Detected" 2 "End of Speed Limit" 3 "End of All Restrictions" 4 "Begin of Motorway" 5 "End of Motorway" 6 "Begin of Expressway" 7 "End of Expressway" 8 "Begin of Play Street Zone" 9 "End of Play Street Zone" 10 "Begin of Passing Restriction" 11 "End of Passing Restriction" 12 "No Entry" 13 "Begin of City Limits" 14 "End of City Limits" 15 "Speed Limit 5" 16 "Speed Limit 10" 17 "Speed Limit 15" 18 "Speed Limit 20" 19 "Speed Limit 25" 20 "Speed Limit 30" 21 "Speed Limit 35" 22 "Speed Limit 40" 23 "Speed Limit 45" 24 "Speed Limit 50" 25 "Speed Limit 55" 26 "Speed Limit 60" 27 "Speed Limit 65" 28 "Speed Limit 70" 29 "Speed Limit 75" 30 "Speed Limit 80" 31 "Speed Limit 85" 32 "Speed Limit 90" 33 "Speed Limit 95" 34 "Speed Limit 100" 35 "Speed Limit 105" 36 "Speed Limit 110" 37 "Speed Limit 115" 38 "Speed Limit 120" 39 "Speed Limit 125" 40 "Speed Limit 130" 41 "Speed Limit 135" 42 "Speed Limit 140" 43 "Speed Limit 145" 44 "Speed Limit 150" 45 "Speed Limit 155" 46 "Speed Limit 160" 47 "Speed Limit 165" 48 "Speed Limit 170" 49 "Speed Limit 175" 50 "Speed Limit 180" 51 "Speed Limit 185" 52 "Speed Limit 190" 53 "Speed Limit 195" 54 "Speed Limit 200" ;
VAL_ 1128 TSMEurDispSgn1Mn 0 "UnKnown" 1 "No Sign Detected" 2 "End of Speed Limit" 3 "End of All Restrictions" 4 "Begin of Motorway" 5 "End of Motorway" 6 "Begin of Expressway" 7 "End of Expressway" 8 "Begin of Play Street Zone" 9 "End of Play Street Zone" 10 "Begin of Passing Restriction" 11 "End of Passing Restriction" 12 "No Entry" 13 "Begin of City Limits" 14 "End of City Limits" 15 "Speed Limit 5" 16 "Speed Limit 10" 17 "Speed Limit 15" 18 "Speed Limit 20" 19 "Speed Limit 25" 20 "Speed Limit 30" 21 "Speed Limit 35" 22 "Speed Limit 40" 23 "Speed Limit 45" 24 "Speed Limit 50" 25 "Speed Limit 55" 26 "Speed Limit 60" 27 "Speed Limit 65" 28 "Speed Limit 70" 29 "Speed Limit 75" 30 "Speed Limit 80" 31 "Speed Limit 85" 32 "Speed Limit 90" 33 "Speed Limit 95" 34 "Speed Limit 100" 35 "Speed Limit 105" 36 "Speed Limit 110" 37 "Speed Limit 115" 38 "Speed Limit 120" 39 "Speed Limit 125" 40 "Speed Limit 130" 41 "Speed Limit 135" 42 "Speed Limit 140" 43 "Speed Limit 145" 44 "Speed Limit 150" 45 "Speed Limit 155" 46 "Speed Limit 160" 47 "Speed Limit 165" 48 "Speed Limit 170" 49 "Speed Limit 175" 50 "Speed Limit 180" 51 "Speed Limit 185" 52 "Speed Limit 190" 53 "Speed Limit 195" 54 "Speed Limit 200" ;
VAL_ 1128 TSMUSAndCADispSgn1Mn 0 "UnKnown" 1 "No Sign Detected" 2 "Begin of Passing Restriction US" 3 "End of Passing Restriction US" 4 "Begin of Passing Restriction Canada" 5 "End of Passing Restriction Canada" 6 "Speed Limit 5" 7 "Speed Limit 10" 8 "Speed Limit 15" 9 "Speed Limit 20" 10 "Speed Limit 25" 11 "Speed Limit 30" 12 "Speed Limit 35" 13 "Speed Limit 40" 14 "Speed Limit 45" 15 "Speed Limit 50" 16 "Speed Limit 55" 17 "Speed Limit 60" 18 "Speed Limit 65" 19 "Speed Limit 70" 20 "Speed Limit 75" 21 "Speed Limit 80" 22 "Speed Limit 85" 23 "Speed Limit 90" 24 "Speed Limit 95" 25 "Speed Limit 100" 26 "Speed Limit 105" 27 "Speed Limit 110" 28 "Speed Limit 115" 29 "Speed Limit 120" 30 "Speed Limit 125" 31 "Speed Limit 130" 32 "Speed Limit 135" 33 "Speed Limit 140" 34 "Speed Limit 145" 35 "Speed Limit 150" 36 "Speed Limit 155" 37 "Speed Limit 160" 38 "Speed Limit 165" 39 "Speed Limit 170" 40 "Speed Limit 175" 41 "Speed Limit 180" 42 "Speed Limit 185" 43 "Speed Limit 190" 44 "Speed Limit 195" 45 "Speed Limit 200" ;
VAL_ 1128 TSMUSAndCADispSgn2Mn 0 "UnKnown" 1 "No Sign Detected" 2 "Begin of Passing Restriction US" 3 "End of Passing Restriction US" 4 "Begin of Passing Restriction Canada" 5 "End of Passing Restriction Canada" 6 "Speed Limit 5" 7 "Speed Limit 10" 8 "Speed Limit 15" 9 "Speed Limit 20" 10 "Speed Limit 25" 11 "Speed Limit 30" 12 "Speed Limit 35" 13 "Speed Limit 40" 14 "Speed Limit 45" 15 "Speed Limit 50" 16 "Speed Limit 55" 17 "Speed Limit 60" 18 "Speed Limit 65" 19 "Speed Limit 70" 20 "Speed Limit 75" 21 "Speed Limit 80" 22 "Speed Limit 85" 23 "Speed Limit 90" 24 "Speed Limit 95" 25 "Speed Limit 100" 26 "Speed Limit 105" 27 "Speed Limit 110" 28 "Speed Limit 115" 29 "Speed Limit 120" 30 "Speed Limit 125" 31 "Speed Limit 130" 32 "Speed Limit 135" 33 "Speed Limit 140" 34 "Speed Limit 145" 35 "Speed Limit 150" 36 "Speed Limit 155" 37 "Speed Limit 160" 38 "Speed Limit 165" 39 "Speed Limit 170" 40 "Speed Limit 175" 41 "Speed Limit 180" 42 "Speed Limit 185" 43 "Speed Limit 190" 44 "Speed Limit 195" 45 "Speed Limit 200" ;
VAL_ 1128 TSMEurDispSgn2AddOn 0 "UnKnown" 1 "None" 2 "Supp Sign Generic" 3 "Rain" 4 "Snow" 5 "Snow Rain" 6 "Rain Cloud" 7 "Fog" 8 "Time" 9 "Wet Conditions" 10 "Trailer" 11 "Tractor Passable" 12 "Arrow Left" 13 "Arrow Right" 14 "Distance Arrow" 15 "School" ;
VAL_ 1128 TSMEurDispSgn1AddOn 0 "UnKnown" 1 "None" 2 "Supp Sign Generic" 3 "Rain" 4 "Snow" 5 "Snow Rain" 6 "Rain Cloud" 7 "Fog" 8 "Time" 9 "Wet Conditions" 10 "Trailer" 11 "Tractor Passable" 12 "Arrow Left" 13 "Arrow Right" 14 "Distance Arrow" 15 "School" ;
VAL_ 1128 FrwdVsFlDtcnIndOn 0 "FALSE" 1 "TRUE" ;
VAL_ 1128 FrwdVsAdvWthrIndOn 0 "FALSE" 1 "TRUE" ;
VAL_ 1128 TSMUSAndCADispSgn2AddOn 0 "None" 1 "Supp Sign Generic" 2 "School" 3 "School When Flashing" 4 "End of Speed Limit" 5 "Where Workers Present" ;
VAL_ 1128 TSMUSAndCADispSgn1AddOn 0 "None" 1 "Supp Sign Generic" 2 "School" 3 "School When Flashing" 4 "End of Speed Limit" 5 "Where Workers Present" ;
VAL_ 1128 TrffcLgtAsstHUDWrnIndOn 0 "FALSE" 1 "TRUE" ;
VAL_ 1128 TrffcLgtAsstClstrWrnIndOn 0 "FALSE" 1 "TRUE" ;
VAL_ 1128 TSMSgnNtfnIndOn 0 "FALSE" 1 "TRUE" ;
VAL_ 1128 TSMPDAMnSgnFlshgReq 0 "FALSE" 1 "TRUE" ;
VAL_ 1128 TSMNoEntryIndOn 0 "FALSE" 1 "TRUE" ;
VAL_ 1128 TSMIcePsblIndOn 0 "FALSE" 1 "TRUE" ;
VAL_ 1128 TSMAddTrfSgnAvIndOn 0 "FALSE" 1 "TRUE" ;
VAL_ 1128 FrwdVsFllBlckIndOn 0 "FALSE" 1 "TRUE" ;
VAL_ 1128 TrffcLgtAsstRLADWrnIndOn 0 "FALSE" 1 "TRUE" ;
VAL_ 1119 ADASIS_NAVILINK_DgtlMpEfSpdLm 0 "UNKNOWN" 1 "<= 5 KM/H [MPH]" 2 "7 KM/H [MPH]" 3 "10 KM/H [MPH]" 4 "15 KM/H [MPH]" 5 "20 KM/H [MPH]" 6 "25 KM/H [MPH]" 7 "30 KM/H [MPH]" 8 "35 KM/H [MPH]" 9 "40 KM/H [MPH]" 10 "45 KM/H [MPH]" 11 "50 KM/H [MPH]" 12 "55 KM/H [MPH]" 13 "60 KM/H" 14 "MPH]65 KM/H [MPH]" 15 "70 KM/H [MPH]" 16 "75 KM/H [MPH]" 17 "80 KM/H [MPH]" 18 "85 KM/H [MPH]" 19 "90 KM/H [MPH]" 20 "95 KM/H [MPH]" 21 "100 KM/H [MPH]" 22 "105 KM/H [MPH]" 23 "110 KM/H [MPH]" 24 "115 KM/H [MPH]" 25 "120 KM/H[MPH]" 26 "130 KM/H [MPH]" 27 "140 KM/H [MPH]" 28 "150 KM/H [MPH]" 29 "160 KM/H [MPH]" 30 "UNLIMITED" 31 "NOT AVAILABLE" ;
VAL_ 1119 ADASIS_NAVILINK_CntryCd 0 "AD" 1 "AT" 2 "BE" 3 "CZ" 4 "DK" 5 "EE" 6 "FR" 7 "DE" 8 "GR" 9 "HU" 10 "IE" 11 "IT" 12 "BY" 13 "BG" 14 "CY" 15 "MT" 16 "HR" 17 "TR" 18 "RS" 19 "ME" 20 "LV" 21 "LT" 22 "LU" 23 "NL" 24 "NO" 25 "PL" 26 "PT" 27 "UK" 28 "SK" 29 "SI" 30 "ES" 31 "SE" 32 "CH" 33 "RO" 34 "RU" 35 "UA" 36 "BA" 37 "AL" 38 "MD" 39 "IS" 40 "MK" 41 "US" 42 "ZA" 43 "AU" 44 "NZ" 45 "KR" 46 "CN" ;
VAL_ 1119 ADASIS_NAVILINK_DigMpCndlSpdLmt 0 "UNKNOWN" 1 "<= 5 KM/H [MPH]" 2 "7 KM/H [MPH]" 3 "10 KM/H [MPH]" 4 "15 KM/H [MPH]" 5 "20 KM/H [MPH]" 6 "25 KM/H [MPH]" 7 "30 KM/H [MPH]" 8 "35 KM/H [MPH]" 9 "40 KM/H [MPH]" 10 "45 KM/H [MPH]" 11 "50 KM/H [MPH]" 12 "55 KM/H [MPH]" 13 "60 KM/H" 14 "MPH]65 KM/H [MPH]" 15 "70 KM/H [MPH]" 16 "75 KM/H [MPH]" 17 "80 KM/H [MPH]" 18 "85 KM/H [MPH]" 19 "90 KM/H [MPH]" 20 "95 KM/H [MPH]" 21 "100 KM/H [MPH]" 22 "105 KM/H [MPH]" 23 "110 KM/H [MPH]" 24 "115 KM/H [MPH]" 25 "120 KM/H[MPH]" 26 "130 KM/H [MPH]" 27 "140 KM/H [MPH]" 28 "150 KM/H [MPH]" 29 "160 KM/H [MPH]" 30 "UNLIMITED" 31 "NOT AVAILABLE" ;
VAL_ 1119 ADASIS_NAVILINK_DgtlMpSpdCtgry 0 "> 130 KPH OR > 80 MPH" 1 "101-130 KPH OR 65\???80 MPH" 2 "91-100 KPH OR 55\???64 MPH" 3 "71-90 KPH OR 41\???54 MPH" 4 "51-70 KPH OR 31\???40 MPH" 5 "31-50 KPH OR 21\???30 MPH" 6 "11-30 KPH OR 6 \???20 MPH" 7 "<11 KPH OR < 6 MPH" 8 "UNKNOWN" ;
VAL_ 1119 ADASIS_NAVILINK_DgtlMpPsngRst 0 "NO PASSING RESTRICTIONS" 1 "GENERAL NO OVERTAKE" 2 "FLUCTUATING (E.G. LED SIGNS)" 3 "CONDITIONAL PASSENGER CAR WITH TRAILER" 4 "CONDITIONAL TRACTORS ARE ALLOWED TO OVERTAKE" 5 "CONDITIONAL WHEN WET" 6 "CONDITIONAL WHEN SNOW" 7 "UNKNOWN CONDITION" ;
VAL_ 1119 ADASIS_NAVILINK_DigMpEfSpdLmTyp 0 "IMPLICIT" 1 "ON TRAFFIC SIGN" 2 "ONLY BY NIGHT" 3 "ONLY BY DAY" 4 "TIME OF DAY" 5 "ONLY BY RAIN" 6 "ONLY BY SNOW OR FOG" 7 "UNKOWN" ;
VAL_ 1119 ADASIS_NAVILINK_DgMpCnSpdLmTyp 0 "LANE DEPENDENT" 1 "ONLY BY FOG" 2 "ONLY BY NIGHT" 3 "ONLY BY DAY" 4 "BY TIME OF DAY" 5 "ONLY BY RAIN" 6 "ONLY BY SNOW" 7 "UNKNOWN" ;
VAL_ 1119 ADASIS_NAVILINK_DigMpPstSpdLmAs 0 "NOT ASSURED" 1 "ASSURED" ;
VAL_ 1119 ADASIS_NAVILINK_DigMpDrvngSd 0 "DRIVING SIDE LEFT" 1 "DRIVING SIDE RIGHT" ;
VAL_ 1119 ADASIS_NAVILINK_CntrldAccssRd 0 "ROAD IS NOT CONTROLLED ACCESS ROAD" 1 "ROAD IS CONTROLLED ACCESS ROAD" ;
VAL_ 1119 ADASIS_NAVILINK_BldUpFlg 0 "NOT VALID" 1 "VALID" ;
VAL_ 1120 ADASIS_NAVILINK_FncRdClss 0 "LOCAL" 1 "SFREEWAY" 2 "FREEWAY" 3 "PED-MALL" 4 "HIGHWAY" 5 "ARTERIAL" 6 "ALLEY" 7 "COLLECTOR" ;
VAL_ 1120 ADASIS_NAVILINK_DigMpVerYr 0 "2000" 1 "2001" 2 "2002" 3 "2003" 4 "2004" 5 "2005" 6 "2006" 7 "2007" 8 "2008" 9 "2009" 10 "2010" 11 "2011" 12 "2012" 13 "2013" 14 "2014" 15 "2015" 16 "2016" 17 "2017" 18 "2018" 19 "2019" 20 "2020" 21 "2021" 22 "2022" 23 "2023" 24 "2024" 25 "2025" 26 "2026" 27 "2027" 28 "2028" 29 "2029" 30 "2030" 31 "2031" 32 "2032" 33 "2033" 34 "2034" 35 "2035" 36 "2036" 37 "2037" 38 "2038" 39 "2039" 40 "2040" 41 "2041" 42 "2042" 43 "2043" 44 "2044" 45 "2045" 46 "2046" 47 "2047" 48 "2048" 49 "2049" 50 "2050" 51 "2051" 52 "2052" 53 "2053" 54 "2054" 55 "2055" 56 "2056" 57 "2057" 58 "2058" 59 "2059" 60 "2060" 61 "2061" 62 "2062" 63 "NOT APPLICABLE" ;
VAL_ 1120 ADASIS_NAVILINK_SpdLmtUnt 0 "MILES/H" 1 "KM/H" ;
VAL_ 1120 ADASIS_NAVILINK_SpdLmtPsdSpd_DuD 0 "FALSE" 1 "TRUE" ;
VAL_ 1120 ADASIS_NAVILINK_MpDtAv 0 "NOT VALID" 1 "VALID" ;
VAL_ 1120 ADASIS_NAVILINK_LnCtgry 0 "NO INFO AVAILABLE" 1 "ONE LANE" 2 "TWO OR THREE LANES" 3 "FOUR OR MORE LANES" ;
VAL_ 1120 ADASIS_NAVILINK_DigMpVerQtr 0 "QUARTER 1" 1 "QUARTER 2" 2 "QUARTER 3" 3 "QUARTER 4" ;
VAL_ 1120 ADASIS_NAVILINK_SprtdLnRd 0 "ROAD IS NOT CONTROLLED ACCESS ROAD" 1 "ROAD IS CONTROLLED ACCESS ROAD" ;
VAL_ 514 EASSI_StrtStpSt 0 "Engine Off" 1 "Engine Running" 2 "Engine Starting" 3 "Engine Stopping" ;
VAL_ 32 HVPPP_ShrtRngRadarModeCmdAuth 0 "Not Radiating" 1 "Not Reporting Object Data" 2 "Reporting Object Data" ;
VAL_ 32 HVPPP_LngRngRadarModeCmdAuth 0 "Not Radiating" 1 "Not Reporting Object Data" 2 "Reporting" ;
VAL_ 32 HVPPP_HstVehLatVelAuth_Inv 0 "FALSE" 1 "TRUE" ;
VAL_ 32 HVPPP_HstVehVelAuth_Inv 0 "FALSE" 1 "TRUE" ;
VAL_ 32 HVPPP_ObjsRetndRrwdSnsrsAuth 0 "Unknown" 1 "Objects Reported" 2 "No Objects Reported" ;
VAL_ 32 HVPPP_HstVehLngVelAuth_Inv 0 "FALSE" 1 "TRUE" ;
VAL_ 32 HVPPP_ObjsRetndFrwdSnsrsAuth 0 "Unknown" 1 "Objects Reported" 2 "No Objects Reported" ;
VAL_ 32 HVPPP_HstVehPathModeAuth 0 "Disabled" 1 "Low Speed" 2 "High Speed" ;
VAL_ 32 HVPPP_HstVehYawRateAuth_Inv 0 "FALSE" 1 "TRUE" ;
VAL_ 32 HVPPP_HstVehTrvlDirAuth 0 "Unknown" 1 "Forward or Stopped on a Forward Gear" 2 "Reversed or Stopped in a Reverse Gear" 3 "Other" ;
VAL_ 32 HVPPP_FrwdVsnModeCmdAuth 0 "Not Reporting Object Data" 1 "Reporting Object Data" ;
VAL_ 36 LLDP_LatAccelSnsrCorrStsAuth 0 "Unknown" 1 "NA" 2 "Correlated" 3 "Uncorellated" ;
VAL_ 36 LLDP_LatAccelAuth_Inv 0 "FALSE" 1 "TRUE" ;
VAL_ 36 LLDP_LongAccelAuth_Inv 0 "FALSE" 1 "TRUE" ;
VAL_ 36 LLDP_VehAccelCalAuth 0 "FALSE" 1 "TRUE" ;
VAL_ 36 LLDP_VehAccelAuth_DuD 0 "FALSE" 1 "TRUE" ;
VAL_ 36 LLDP_LongAccelSnsrCorrStsAuth 0 "Unknown" 1 "NA" 2 "Correlated" 3 "Uncorellated" ;
VAL_ 1377 NodeStsAPA_CAN_2_LcFA 0 "FALSE" 1 "TRUE" ;
VAL_ 1377 NodeStsAPA_CAN_1_LcFA 0 "FALSE" 1 "TRUE" ;
VAL_ 1377 NodeStsAOS_LcFA 0 "FALSE" 1 "TRUE" ;
VAL_ 1377 NodeStsAMP_LcFA 0 "FALSE" 1 "TRUE" ;
VAL_ 1377 NodeStsALC_LcFA 0 "FALSE" 1 "TRUE" ;
VAL_ 1377 NodeStsAHL_AFL_LcFA 0 "FALSE" 1 "TRUE" ;
VAL_ 1377 NodeStsAGC_LcFA 0 "FALSE" 1 "TRUE" ;
VAL_ 1377 NodeStsDMS_LcFA 0 "FALSE" 1 "TRUE" ;
VAL_ 1377 NodeStsDEFC_LcFA 0 "FALSE" 1 "TRUE" ;
VAL_ 1377 NodeStsDCM_LcFA 0 "FALSE" 1 "TRUE" ;
VAL_ 1377 NodeStsCSM_LcFA 0 "FALSE" 1 "TRUE" ;
VAL_ 1377 NodeStsBSM_CAN_3_LcFA 0 "FALSE" 1 "TRUE" ;
VAL_ 1377 NodeStsBSM_CAN_2_LcFA 0 "FALSE" 1 "TRUE" ;
VAL_ 1377 NodeStsBCM_LcFA 0 "FALSE" 1 "TRUE" ;
VAL_ 1377 NodeStsARB_LcFA 0 "FALSE" 1 "TRUE" ;
VAL_ 1377 NodeStsELM_LcFA 0 "FALSE" 1 "TRUE" ;
VAL_ 1377 NodeStsECP_X1_CAN_3_LcFA 0 "FALSE" 1 "TRUE" ;
VAL_ 1377 NodeStsECP_X1_CAN_2_LcFA 0 "FALSE" 1 "TRUE" ;
VAL_ 1377 NodeStsECM_CAN_3_LcFA 0 "FALSE" 1 "TRUE" ;
VAL_ 1377 NodeStsECM_CAN_2_LcFA 0 "FALSE" 1 "TRUE" ;
VAL_ 1377 NodeStsEBCM_CAN_2_LcFA 0 "FALSE" 1 "TRUE" ;
VAL_ 1377 NodeStsEBCM_CAN_1_LcFA 0 "FALSE" 1 "TRUE" ;
VAL_ 1377 NodeStsEPS_LcFA 0 "FALSE" 1 "TRUE" ;
VAL_ 1377 NodeStsEOCM_HCP2_LcFA 0 "FALSE" 1 "TRUE" ;
VAL_ 1377 NodeStsEOCM_HCP1_CAN_8_LcFA 0 "FALSE" 1 "TRUE" ;
VAL_ 1377 NodeStsEOCM_HCP1_CAN_2_LcFA 0 "FALSE" 1 "TRUE" ;
VAL_ 1377 NodeStsEOCM_HCP1_CAN_1_LcFA 0 "FALSE" 1 "TRUE" ;
VAL_ 1377 NodeStsEOCM_CAN_8_LcFA 0 "FALSE" 1 "TRUE" ;
VAL_ 1377 NodeStsEOCM_CAN_2_LcFA 0 "FALSE" 1 "TRUE" ;
VAL_ 1377 NodeStsEOCM_CAN_1_LcFA 0 "FALSE" 1 "TRUE" ;
VAL_ 1377 NodeStsIPC_LcFA 0 "FALSE" 1 "TRUE" ;
VAL_ 1377 NodeStsICS_Info_LcFA 0 "FALSE" 1 "TRUE" ;
VAL_ 1377 NodeStsICCM_LcFA 0 "FALSE" 1 "TRUE" ;
VAL_ 1377 NodeStsHVAC_FP_R_LcFA 0 "FALSE" 1 "TRUE" ;
VAL_ 1377 NodeStsHVAC_FP_F_LcFA 0 "FALSE" 1 "TRUE" ;
VAL_ 1377 NodeStsHUD_CAN_LcFA 0 "FALSE" 1 "TRUE" ;
VAL_ 1377 NodeStsFCM_LcFA 0 "FALSE" 1 "TRUE" ;
VAL_ 1377 NodeStsFCM_LC_LcFA 0 "FALSE" 1 "TRUE" ;
VAL_ 1377 NodeStsMSM_D_LcFA 0 "FALSE" 1 "TRUE" ;
VAL_ 1377 NodeStsMSB2_LcFA 0 "FALSE" 1 "TRUE" ;
VAL_ 1377 NodeStsMSB1_LcFA 0 "FALSE" 1 "TRUE" ;
VAL_ 1377 NodeStsMRCM_R_LcFA 0 "FALSE" 1 "TRUE" ;
VAL_ 1377 NodeStsMRCM_L_LcFA 0 "FALSE" 1 "TRUE" ;
VAL_ 1377 NodeStsMFC_LcFA 0 "FALSE" 1 "TRUE" ;
VAL_ 1377 NodeStsLRR_LcFA 0 "FALSE" 1 "TRUE" ;
VAL_ 1377 NodeStsLRR_HC_LcFA 0 "FALSE" 1 "TRUE" ;
VAL_ 1377 NodeStsPDR_LcFA 0 "FALSE" 1 "TRUE" ;
VAL_ 1377 NodeStsPA_LcFA 0 "FALSE" 1 "TRUE" ;
VAL_ 1377 NodeStsNVM_LcFA 0 "FALSE" 1 "TRUE" ;
VAL_ 1377 NodeStsMTCM_R_LcFA 0 "FALSE" 1 "TRUE" ;
VAL_ 1377 NodeStsMTCM_L_LcFA 0 "FALSE" 1 "TRUE" ;
VAL_ 1377 NodeStsMSM_RR_LcFA 0 "FALSE" 1 "TRUE" ;
VAL_ 1377 NodeStsMSM_P_LcFA 0 "FALSE" 1 "TRUE" ;
VAL_ 1377 NodeStsMSM_LR_LcFA 0 "FALSE" 1 "TRUE" ;
VAL_ 1377 NodeStsSBZA_R_LcFA 0 "FALSE" 1 "TRUE" ;
VAL_ 1377 NodeStsSBZA_L_LcFA 0 "FALSE" 1 "TRUE" ;
VAL_ 1377 NodeStsSADS_LcFA 0 "FALSE" 1 "TRUE" ;
VAL_ 1377 NodeStsAHS_LcFA 0 "FALSE" 1 "TRUE" ;
VAL_ 1377 NodeStsRSC_LcFA 0 "FALSE" 1 "TRUE" ;
VAL_ 1377 NodeStsRDCM_LcFA 0 "FALSE" 1 "TRUE" ;
VAL_ 1377 NodeStsRadioLow_LcFA 0 "FALSE" 1 "TRUE" ;
VAL_ 1377 NodeStsPTM_LcFA 0 "FALSE" 1 "TRUE" ;
VAL_ 1378 NodeStsSRR_SLR_LcFA 0 "FALSE" 1 "TRUE" ;
VAL_ 1378 NodeStsSRR_RR_LcFA 0 "FALSE" 1 "TRUE" ;
VAL_ 1378 NodeStsSRR_RF_LcFA 0 "FALSE" 1 "TRUE" ;
VAL_ 1378 NodeStsSRR_LR_CR_LcFA 0 "FALSE" 1 "TRUE" ;
VAL_ 1378 NodeStsSRR_LF_LcFA 0 "FALSE" 1 "TRUE" ;
VAL_ 1378 NodeStsSIB_LcFA 0 "FALSE" 1 "TRUE" ;
VAL_ 1378 NodeStsSDM_LcFA 0 "FALSE" 1 "TRUE" ;
VAL_ 1378 NodeStsSCL_LcFA 0 "FALSE" 1 "TRUE" ;
VAL_ 1378 NodeStsTIM_LcFA 0 "FALSE" 1 "TRUE" ;
VAL_ 1378 NodeStsTCP_LcFA 0 "FALSE" 1 "TRUE" ;
VAL_ 1378 NodeStsTCM_LcFA 0 "FALSE" 1 "TRUE" ;
VAL_ 1378 NodeStsTCCM3_LcFA 0 "FALSE" 1 "TRUE" ;
VAL_ 1378 NodeStsTCCM_LcFA 0 "FALSE" 1 "TRUE" ;
VAL_ 1378 NodeStsSTC_LcFA 0 "FALSE" 1 "TRUE" ;
VAL_ 1378 NodeStsSRR_SRR_LcFA 0 "FALSE" 1 "TRUE" ;
VAL_ 1378 NodeStsECP_E_CAN_9_LcFA 0 "FALSE" 1 "TRUE" ;
VAL_ 1378 NodeStsCMMb_CAN_2_LcFA 0 "FALSE" 1 "TRUE" ;
VAL_ 1378 NodeStsCMMa_CAN_2_LcFA 0 "FALSE" 1 "TRUE" ;
VAL_ 1378 NodeStsARS_LcFA 0 "FALSE" 1 "TRUE" ;
VAL_ 1378 NodeStsVLM_LcFA 0 "FALSE" 1 "TRUE" ;
VAL_ 1378 NodeStsWCM_LcFA 0 "FALSE" 1 "TRUE" ;
VAL_ 1378 NodeStsVPM_LcFA 0 "FALSE" 1 "TRUE" ;
VAL_ 1378 NodeStsVKM_LcFA 0 "FALSE" 1 "TRUE" ;
VAL_ 1378 NodeStsECP_E_CAN_2_LcFA 0 "FALSE" 1 "TRUE" ;
VAL_ 1441 NodeStsECP_MC_LcFA 0 "FALSE" 1 "TRUE" ;
VAL_ 1441 NodeStsCMMb_CAN_9_LcFA 0 "FALSE" 1 "TRUE" ;
VAL_ 1441 NodeStsCMMa_CAN_9_LcFA 0 "FALSE" 1 "TRUE" ;
VAL_ 1441 NodeStsBSM_MH_LcFA 0 "FALSE" 1 "TRUE" ;
VAL_ 1441 NodeStsSBM_CAN_9_LcFA 0 "FALSE" 1 "TRUE" ;
VAL_ 1441 NodeStsSBM_CAN_10_LcFA 0 "FALSE" 1 "TRUE" ;
VAL_ 1441 NodeStsLIB1_LcFA 0 "FALSE" 1 "TRUE" ;
VAL_ 1441 NodeStsHDLM_LcFA 0 "FALSE" 1 "TRUE" ;
VAL_ 551 PSP_VehTheftImbChlgRespStsAuth 0 "Undetermined" 1 "Pass" 2 "Fail" ;
VAL_ 551 PSP_RmtVehStrtEngRnngAuth 0 "FALSE" 1 "TRUE" ;
VAL_ 551 PSP_PwrtrnCrnkAbrtdAuth 0 "FALSE" 1 "TRUE" ;
VAL_ 551 PSP_PrplSysStlActvAuth 0 "FALSE" 1 "TRUE" ;
VAL_ 551 PSP_PrplSysActvAuth 0 "FALSE" 1 "TRUE" ;
VAL_ 551 PSP_EngRnngAuth 0 "FALSE" 1 "TRUE" ;
VAL_ 551 PSP_ClchBtmTrvlAchvdAuth_Inv 0 "FALSE" 1 "TRUE" ;
VAL_ 551 PSP_ClchBtmTrvlAchvdAuth 0 "FALSE" 1 "TRUE" ;
VAL_ 551 PSP_PrkNeutSwStatAuth_Inv 0 "FALSE" 1 "TRUE" ;
VAL_ 551 PSP_PrkNeutSwStatAuth 0 "Park/Neutral" 1 "Not Park/Neutral" ;
VAL_ 1054 RrCrsTrfcBrkgAutoBrkgRelIndOn 0 "FALSE" 1 "TRUE" ;
VAL_ 140 RrCrsTrfcBrkgAutoBrkgReqdRt 0 "FALSE" 1 "TRUE" ;
VAL_ 139 RCTBAD_BrkgReqd 0 "FALSE" 1 "TRUE" ;
VAL_ 139 RCTBAD_BrkgReqTyp 0 "None" 1 "Hold" ;
VAL_ 1136 LtFstAprchgVehObjDtd 0 "FALSE" 1 "TRUE" ;
VAL_ 1137 RtFstAprchgVehObjDtd 0 "FALSE" 1 "TRUE" ;
VAL_ 1138 RtSdObjDtdAdjTrlr 0 "FALSE" 1 "TRUE" ;
VAL_ 1404 SRRLRCODPGI1P_TrlrDtdAuth 0 "FALSE" 1 "TRUE" ;
VAL_ 1430 SRRRRODPGI1P_TrlrDtdAuth 0 "FALSE" 1 "TRUE" ;
VAL_ 1432 SRRSLRODPGI1P_TrlrDtdAuth 0 "FALSE" 1 "TRUE" ;
VAL_ 1433 SRRSRRODPGI1P_TrlrDtdAuth 0 "FALSE" 1 "TRUE" ;
VAL_ 1135 SBZALCACRrActv 0 "FALSE" 1 "TRUE" ;
VAL_ 1135 SBZALCACRrOprtlSts 0 "Normal Operation" 1 "Needs Service" 2 "Temporary Unavailable" ;
VAL_ 1135 LtSdObjDtdAdjTrlr 0 "FALSE" 1 "TRUE" ;
VAL_ 1109 SBZALCARRActv 0 "FALSE" 1 "TRUE" ;
VAL_ 1109 SBZALCARROprtlSts 0 "Normal Operation" 1 "Needs Service" 2 "Temporary Unavailable" ;
VAL_ 1141 RrCrsTrfcAlrtCstAvlFlg1 0 "FALSE" 1 "TRUE" ;
VAL_ 1141 LnChgAlrtCstAvlFlg7 0 "FALSE" 1 "TRUE" ;
VAL_ 1141 LnChgAlrtCstAvlFlg6 0 "FALSE" 1 "TRUE" ;
VAL_ 1141 LnChgAlrtCstAvlFlg5 0 "FALSE" 1 "TRUE" ;
VAL_ 1141 LnChgAlrtCstAvlFlg4 0 "FALSE" 1 "TRUE" ;
VAL_ 1141 LnChgAlrtCstAvlFlg3 0 "FALSE" 1 "TRUE" ;
VAL_ 1141 LnChgAlrtCstAvlFlg2 0 "FALSE" 1 "TRUE" ;
VAL_ 1141 LnChgAlrtCstAvlFlg1 0 "FALSE" 1 "TRUE" ;
VAL_ 1141 RrCrsTrfcAlrtCstAvlFlg7 0 "FALSE" 1 "TRUE" ;
VAL_ 1141 RrCrsTrfcAlrtCstAvlFlg6 0 "FALSE" 1 "TRUE" ;
VAL_ 1141 RrCrsTrfcAlrtCstAvlFlg5 0 "FALSE" 1 "TRUE" ;
VAL_ 1141 RrCrsTrfcAlrtCstAvlFlg4 0 "FALSE" 1 "TRUE" ;
VAL_ 1141 RrCrsTrfcAlrtCstAvlFlg3 0 "FALSE" 1 "TRUE" ;
VAL_ 1141 RrCrsTrfcAlrtCstAvlFlg2 0 "FALSE" 1 "TRUE" ;
VAL_ 1142 RrCrsTrfcAlrtLtSdChmEvntStat 0 "NO_ACTION" 1 "ACTIVE" 2 "CANCEL_CHIME" ;
VAL_ 1142 RrCrsTrfcAlrtLftIndCtrl 0 "ON" 1 "OFF" 2 "FLASH" ;
VAL_ 1144 RrCrsTrfcAutoBrkgOffIndOn 0 "FALSE" 1 "TRUE" ;
VAL_ 1144 SBZALCAOvrllSts 0 "FALSE" 1 "TRUE" ;
VAL_ 1144 RrCrsTrfcAlrtOffIndOn 0 "FALSE" 1 "TRUE" ;
VAL_ 1144 RCTAOvrllSts 0 "FALSE" 1 "TRUE" ;
VAL_ 1144 LtSdVehObjDtd 0 "FALSE" 1 "TRUE" ;
VAL_ 1145 RrCrsTrfcAlrtCstStAvl 0 "FALSE" 1 "TRUE" ;
VAL_ 1145 LnChgAlrtCstStAvl 0 "FALSE" 1 "TRUE" ;
VAL_ 1145 RrCrsTrfcAlrtCstCrStVal 0 "SETTING_UNKNOWN" 1 "OFF" 2 "ALERT" 3 "ALERT and BRAKE" 4 "RESERVED_4" 5 "RESERVED_5" 6 "RESERVED_6" 7 "RESERVED_7" ;
VAL_ 1145 LnChgAlrtCstCrStVal 0 "SETTING_UNKNOWN" 1 "OFF" 2 "ON" 3 "RESERVED_3" 4 "RESERVED_4" 5 "RESERVED_5" 6 "RESERVED_6" 7 "RESERVED_7" ;
VAL_ 1147 RrCrsTrfcAlrtRtSdChmEvntStat 0 "NO_ACTION" 1 "ACTIVE" 2 "CANCEL_CHIME" ;
VAL_ 1147 RrCrsTrfcAlrtRgIndCtrl 0 "ON" 1 "OFF" 2 "FLASH" ;
VAL_ 1149 SBZALCARtSts 0 "FALSE" 1 "TRUE" ;
VAL_ 1149 RtSdVehObjDtd 0 "FALSE" 1 "TRUE" ;
VAL_ 1149 RCTARtSts 0 "FALSE" 1 "TRUE" ;
VAL_ 1149 SBZALCAROpStat 0 "NORMAL OPERATION" 1 "NEEDS SERVICE" 2 "TEMPORARY UNAVAILABLE" ;
VAL_ 1155 SBZALCAOvrllOplSts 0 "NORMAL OPERATION" 1 "NEEDS SERVICE" 2 "TEMPORARY UNAVAILABLE" ;
VAL_ 1146 SBZAlrtCstAvlFlg1 0 "FALSE" 1 "TRUE" ;
VAL_ 1146 LnChgAlrtSysOffIndOn 0 "FALSE" 1 "TRUE" ;
VAL_ 1146 LnChgAlrtLmtdTrlrIndOn 0 "FALSE" 1 "TRUE" ;
VAL_ 1146 SBZALCAVisIndStatLt 0 "FLASHING" 1 "SOLID" 2 "OFF" ;
VAL_ 1146 SBZAlrtCstCrStVal 0 "SETTING_UNKNOWN" 1 "OFF" 2 "ON" 3 "RESERVED_3" 4 "RESERVED_4" 5 "RESERVED_5" 6 "RESERVED_6" 7 "RESERVED_7" ;
VAL_ 1146 SBZAlrtOffIndOn 0 "FALSE" 1 "TRUE" ;
VAL_ 1146 SBZAlrtCstStAvl 0 "FALSE" 1 "TRUE" ;
VAL_ 1146 SBZAlrtCstAvlFlg7 0 "FALSE" 1 "TRUE" ;
VAL_ 1146 SBZAlrtCstAvlFlg6 0 "FALSE" 1 "TRUE" ;
VAL_ 1146 SBZAlrtCstAvlFlg5 0 "FALSE" 1 "TRUE" ;
VAL_ 1146 SBZAlrtCstAvlFlg4 0 "FALSE" 1 "TRUE" ;
VAL_ 1146 SBZAlrtCstAvlFlg3 0 "FALSE" 1 "TRUE" ;
VAL_ 1146 SBZAlrtCstAvlFlg2 0 "FALSE" 1 "TRUE" ;
VAL_ 1146 ServSdDtcSysIndOn 0 "FALSE" 1 "TRUE" ;
VAL_ 1146 SdDtcTempUnvIndOn 0 "FALSE" 1 "TRUE" ;
VAL_ 1150 SBZALCAVisIndStatRt 0 "FLASHING" 1 "SOLID" 2 "OFF" ;
VAL_ 1068 SLVFSP_SpdLimVsnFsdSpdUntAuth 0 "km/h" 1 "mph" ;
VAL_ 1068 SLVFSP_SpdLimVsnFsdSpdNwDtdAuth 0 "FALSE" 1 "TRUE" ;
VAL_ 1068 SLVFSP_SpdLimVsnFsdSpdAuth_DuD 0 "FALSE" 1 "TRUE" ;
VAL_ 1393 SGI2P_AirSpnsnRdHghtLwrActnAuth 0 "None" 1 "Slow" 2 "Medium (Exhaust)" 3 "Fast" ;
VAL_ 1393 SGI2P_AirSpnsnRdHghtActvAxlAuth 0 "None" 1 "Front" 2 "Rear" 3 "Both" 4 "Pending" ;
VAL_ 1393 SGI2P_AirSpnsnRdHghtActlStsAuth 0 "Faulted" 1 "Entry/Exit" 2 "Lowered 3(Stability)" 3 "Lowered 2 (Sport)" 4 "Lowered 1 (Aero)" 5 "Showroom" 6 "Normal" 7 "Raised 1" 8 "Raised 2" 9 "Raised 3" ;
VAL_ 1393 SGI2P_AirSpnsnRdHghtTgtStsAuth 0 "Faulted" 1 "Entry/Exit" 2 "Lowered 3(Stability)" 3 "Lowered 2 (Sport)" 4 "Lowered 1 (Aero)" 5 "Showroom" 6 "Normal" 7 "Raised 1" 8 "Raised 2" 9 "Raised 3" ;
VAL_ 1393 SGI2P_AirSpnsnRdHghtRseActnAuth 0 "None" 1 "Slow(i.e. compressor)" 2 "Medium (i.e. Boost)" 3 "Fast (i.e. Reservoir)" ;
VAL_ 644 SPMP_SysPwrModeAuth_Inv 0 "FALSE" 1 "TRUE" ;
VAL_ 644 SPMP_SysPwrModeAuth 0 "Off" 1 "Accessory" 2 "Run" 3 "Start Request" 4 "Propulsion" ;
VAL_ 644 SPMP_PriRunCrnkCmdActvAuth_Inv 0 "FALSE" 1 "TRUE" ;
VAL_ 644 SPMP_PriRunCrnkCmdActvAuth 0 "FALSE" 1 "TRUE" ;
VAL_ 49 TEGP_TrnsEstGrAuth 0 "Not Supported" 1 "First Gear" 2 "Second Gear" 3 "Third Gear" 4 "Fourth Gear" 5 "Fifth Gear" 6 "Sixth Gear" 7 "Seventh Gear" 8 "Eighth Gear" 9 "Ninth Gear" 10 "Tenth Gear" 11 "Unused and Reserved" 12 "CVT Forward Gear" 13 "Neutral Gear" 14 "Reverse Gear" 15 "Park Gear" ;
VAL_ 49 TEGP_TransCmndGrAuth 0 "Not Supported" 1 "First Gear" 2 "Second Gear" 3 "Third Gear" 4 "Fourth Gear" 5 "Fifth Gear" 6 "Sixth Gear" 7 "Seventh Gear" 8 "Eighth Gear" 9 "Ninth Gear" 10 "Tenth Gear" 11 "Unused and Reserved" 12 "CVT Forward Gear" 13 "Neutral Gear" 14 "Reverse Gear" 15 "Park Gear" ;
VAL_ 49 TEGP_TrnsEngdStAuth_Inv 0 "FALSE" 1 "TRUE" ;
VAL_ 49 TEGP_TrnsShftLvrPstnAuth 0 "Between Ranges" 1 "Park Range" 2 "Reverse Range" 3 "Neutral Range" 4 "Forward Range A" 5 "Forward Range B" 6 "Forward Range C" 7 "Forward Range D" 8 "Forward Range E" 9 "Forward Range F" 10 "Forward Range G" 11 "Forward Range H" 12 "Forward Range I" 13 "Forward Range J" 14 "Lever Position Unknown" ;
VAL_ 49 TEGP_TrnsEngdStAuth 0 "Transmission Not Engaged" 1 "Transmission Engaged in Forward" 2 "Transmission Engaged in Reverse" 3 "Operating State Not Reached" ;
VAL_ 49 TEGP_TrnsEstGrAuth_Inv 0 "FALSE" 1 "TRUE" ;
VAL_ 49 TEGP_TrnsShftLvrPstnAuth_Inv 0 "FALSE" 1 "TRUE" ;
VAL_ 135 VMI1P_AccelPedOvrrdActvAuth 0 "FALSE" 1 "TRUE" ;
VAL_ 135 VMI1P_VehTopSpdLimModeActvAuth 0 "FALSE" 1 "TRUE" ;
VAL_ 135 VMI1P_AccelActlPstnAuth_Inv 0 "FALSE" 1 "TRUE" ;
VAL_ 553 VSADP_VehSpdAvgDrvnAuth_Inv 0 "FALSE" 1 "TRUE" ;
VAL_ 553 VSADP_FuelModeStsAuth 0 "Unknown" 1 "Gasoline Mode" 2 "Natural Gas Mode" 3 "Liquified Petroleum Gas Mode" 4 "Alternative Fuel Cut-off Active" ;
VAL_ 553 VSADP_RdcdPwrIndOnAuth 0 "FALSE" 1 "TRUE" ;
VAL_ 553 VSADP_VehSpdAvgDrvnSrcAuth 0 "Transmission Output Speed" 1 "Wheel Speed" ;
